VERSION ""

NS_ :

BS_:

BU_: TCU_FB5 RFA_BLEM GWM _delete GENERIC TSTR

BO_ 76 RCMStatusMessage2_HS4: 8 GWM
 SG_ RstrnPsngrOn_D_Stat : 39|4@0+ (1,0) [0|15] "SED"  GENERIC
 SG_ FirstRowBuckle_No_Cs : 47|8@0+ (1,0) [0|255] "unitless"  GENERIC
 SG_ RCMStatusMsg2_No_Cnt : 35|4@0+ (1,0) [0|15] "Unitless"  GENERIC
 SG_ PsngrFmidDetct_D_Actl : 26|2@0+ (1,0) [0|3] "SED"  TCU_FB5
 SG_ FirstRowBuckleMid : 28|2@0+ (1,0) [0|3] "SED"  TCU_FB5
 SG_ ThirdRowBucklePsngr : 17|2@0+ (1,0) [0|3] "SED" Vector__XXX
 SG_ ThirdRowBuckleMid : 19|2@0+ (1,0) [0|3] "SED" Vector__XXX
 SG_ ThirdRowBuckleDriver : 21|2@0+ (1,0) [0|3] "SED" Vector__XXX
 SG_ SecondRowBucklePsngr : 23|2@0+ (1,0) [0|3] "SED"  TCU_FB5
 SG_ SecondRowBuckleMid : 9|2@0+ (1,0) [0|3] "SED"  TCU_FB5
 SG_ SecondRowBuckleDriver : 11|2@0+ (1,0) [0|3] "SED"  TCU_FB5
 SG_ FirstRowBuckleDriver : 15|2@0+ (1,0) [0|3] "SED"  TCU_FB5
 SG_ RILReq : 7|2@0+ (1,0) [0|3] "SED"  GENERIC
 SG_ FirstRowBucklePsngr : 13|2@0+ (1,0) [0|3] "SED"  TCU_FB5
 SG_ RstrnImpactEvntStatus : 3|3@0+ (1,0) [0|7] "SED"  GENERIC
 SG_ PsngrFrntDetct_D_Actl : 5|2@0+ (1,0) [0|3] "SED"  TCU_FB5
 SG_ EDRTriggerEvntSync : 29|1@0+ (1,0) [0|1] "SED"  GENERIC
 SG_ PassRstrnInd_Req : 31|2@0+ (1,0) [0|3] "SED"  GENERIC

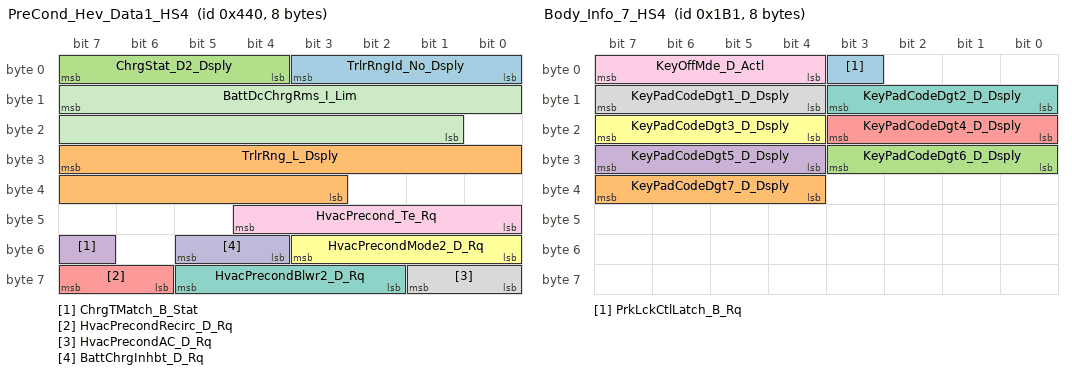
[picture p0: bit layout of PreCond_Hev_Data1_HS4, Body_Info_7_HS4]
BO_ 1088 PreCond_Hev_Data1_HS4: 8 GWM
 SG_ TrlrRngId_No_Dsply : 3|4@0+ (1,0) [0|15] "unitless" Vector__XXX
 SG_ TrlrRng_L_Dsply : 31|13@0+ (0.1,0) [0|818.9] "kilometer"  GENERIC
 SG_ ChrgStat_D2_Dsply : 7|4@0+ (1,0) [0|15] "SED" Vector__XXX
 SG_ ChrgTMatch_B_Stat : 55|1@0+ (1,0) [0|1] "SED"  GENERIC
 SG_ HvacPrecondRecirc_D_Rq : 63|2@0+ (1,0) [0|3] "SED"  GENERIC
 SG_ HvacPrecondMode2_D_Rq : 51|4@0+ (1,0) [0|15] "SED"  GENERIC
 SG_ HvacPrecondBlwr2_D_Rq : 61|4@0+ (1,0) [0|15] "SED"  GENERIC
 SG_ HvacPrecondAC_D_Rq : 57|2@0+ (1,0) [0|3] "SED"  GENERIC
 SG_ HvacPrecond_Te_Rq : 44|5@0+ (0.5,14.5) [14.5|30] "deg C"  GENERIC
 SG_ BattChrgInhbt_D_Rq : 53|2@0+ (1,0) [0|3] "SED"  GENERIC
 SG_ BattDcChrgRms_I_Lim : 15|15@0+ (0.05,0) [0|1638.25] "ampere"  GENERIC

BO_ 433 Body_Info_7_HS4: 8 GWM
 SG_ PrkLckCtlLatch_B_Rq : 3|1@0+ (1,0) [0|1] "SED" Vector__XXX
 SG_ KeyPadCodeDgt7_D_Dsply : 39|4@0+ (1,0) [0|15] "SED"  GENERIC
 SG_ KeyPadCodeDgt6_D_Dsply : 27|4@0+ (1,0) [0|15] "SED"  GENERIC
 SG_ KeyPadCodeDgt5_D_Dsply : 31|4@0+ (1,0) [0|15] "SED"  GENERIC
 SG_ KeyPadCodeDgt4_D_Dsply : 19|4@0+ (1,0) [0|15] "SED"  GENERIC
 SG_ KeyPadCodeDgt3_D_Dsply : 23|4@0+ (1,0) [0|15] "SED"  GENERIC
 SG_ KeyPadCodeDgt2_D_Dsply : 11|4@0+ (1,0) [0|15] "SED"  GENERIC
 SG_ KeyPadCodeDgt1_D_Dsply : 15|4@0+ (1,0) [0|15] "SED"  GENERIC
 SG_ KeyOffMde_D_Actl : 7|4@0+ (1,0) [0|15] "SED"  RFA_BLEM,TCU_FB5

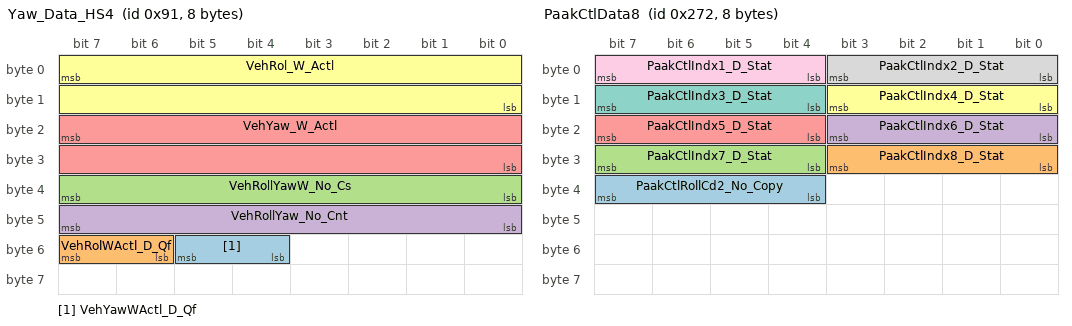
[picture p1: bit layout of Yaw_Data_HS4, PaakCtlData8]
BO_ 145 Yaw_Data_HS4: 8 GWM
 SG_ VehYawWActl_D_Qf : 53|2@0+ (1,0) [0|3] "SED"  TCU_FB5
 SG_ VehRolWActl_D_Qf : 55|2@0+ (1,0) [0|3] "SED"  GENERIC
 SG_ VehRollYawW_No_Cs : 39|8@0+ (1,0) [0|255] "Unitless"  GENERIC
 SG_ VehRollYaw_No_Cnt : 47|8@0+ (1,0) [0|255] "Unitless"  TCU_FB5
 SG_ VehYaw_W_Actl : 23|16@0+ (0.0002,-6.5) [-6.5|6.6066] "rad/s"  TCU_FB5
 SG_ VehRol_W_Actl : 7|16@0+ (0.0002,-6.5) [-6.5|6.6066] "rad/s"  GENERIC

BO_ 626 PaakCtlData8: 8 RFA_BLEM
 SG_ PaakCtlRollCd2_No_Copy : 39|4@0+ (1,0) [0|15] "unitless"  GWM
 SG_ PaakCtlIndx8_D_Stat : 27|4@0+ (1,0) [0|15] "SED"  GWM
 SG_ PaakCtlIndx7_D_Stat : 31|4@0+ (1,0) [0|15] "SED"  GWM
 SG_ PaakCtlIndx6_D_Stat : 19|4@0+ (1,0) [0|15] "SED"  GWM
 SG_ PaakCtlIndx5_D_Stat : 23|4@0+ (1,0) [0|15] "SED"  GWM
 SG_ PaakCtlIndx4_D_Stat : 11|4@0+ (1,0) [0|15] "SED"  GWM
 SG_ PaakCtlIndx3_D_Stat : 15|4@0+ (1,0) [0|15] "SED"  GWM
 SG_ PaakCtlIndx2_D_Stat : 3|4@0+ (1,0) [0|15] "SED"  GWM
 SG_ PaakCtlIndx1_D_Stat : 7|4@0+ (1,0) [0|15] "SED"  GWM

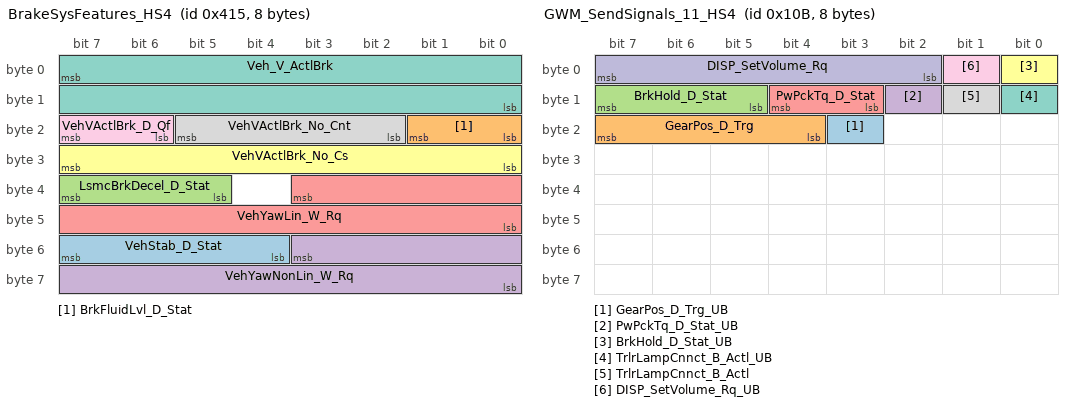
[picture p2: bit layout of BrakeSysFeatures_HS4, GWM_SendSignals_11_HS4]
BO_ 1045 BrakeSysFeatures_HS4: 8 GWM
 SG_ VehStab_D_Stat : 55|4@0+ (1,0) [0|15] "SED"  GENERIC
 SG_ BrkFluidLvl_D_Stat : 17|2@0+ (1,0) [0|3] "SED"  GENERIC
 SG_ LsmcBrkDecel_D_Stat : 39|3@0+ (1,0) [0|7] "SED"  GENERIC
 SG_ VehYawNonLin_W_Rq : 51|12@0+ (0.03663,-75) [-75|74.92659] "deg/s"  GENERIC
 SG_ VehYawLin_W_Rq : 35|12@0+ (0.03663,-75) [-75|74.92659] "deg/s"  GENERIC
 SG_ VehVActlBrk_No_Cs : 31|8@0+ (1,0) [0|255] "Unitless"  RFA_BLEM
 SG_ Veh_V_ActlBrk : 7|16@0+ (0.01,0) [0|655.35] "kph"  RFA_BLEM
 SG_ VehVActlBrk_No_Cnt : 21|4@0+ (1,0) [0|15] "Unitless"  RFA_BLEM
 SG_ VehVActlBrk_D_Qf : 23|2@0+ (1,0) [0|3] "SED"  RFA_BLEM

BO_ 1192 APIM_TCU_Word_Tx_HS4: 8 GWM
 SG_ APIM_TCU_Word_Tx : 7|64@0+ (1,0) [0|1.84467440737096E+019] "unitless"  TCU_FB5

BO_ 267 GWM_SendSignals_11_HS4: 8 GWM
 SG_ GearPos_D_Trg_UB : 19|1@0+ (1,0) [0|1] "SED"  RFA_BLEM
 SG_ GearPos_D_Trg : 23|4@0+ (1,0) [0|15] "SED"  RFA_BLEM
 SG_ BrkHold_D_Stat : 15|3@0+ (1,0) [0|7] "SED"  RFA_BLEM
 SG_ PwPckTq_D_Stat_UB : 10|1@0+ (1,0) [0|1] "SED"  RFA_BLEM
 SG_ PwPckTq_D_Stat : 12|2@0+ (1,0) [0|3] "SED"  RFA_BLEM
 SG_ BrkHold_D_Stat_UB : 0|1@0+ (1,0) [0|1] "SED"  RFA_BLEM
 SG_ TrlrLampCnnct_B_Actl_UB : 8|1@0+ (1,0) [0|1] "SED"  RFA_BLEM
 SG_ TrlrLampCnnct_B_Actl : 9|1@0+ (1,0) [0|1] "SED"  RFA_BLEM
 SG_ DISP_SetVolume_Rq_UB : 1|1@0+ (1,0) [0|1] "SED"  TCU_FB5
 SG_ DISP_SetVolume_Rq : 7|6@0+ (1,-30) [-30|33] "steps"  TCU_FB5

BO_ 2612224076 PARSEDPushRFAtoGWM_ECG: 8 RFA_BLEM
 SG_ PARSEDPushRFAtoGWM_ECG : 7|29@0+ (1,0) [0|536870911] "unitless"  GWM

BO_ 2611032280 PARSEDPhysGWM_ECGtoRFA: 8 GWM
 SG_ PARSEDPhysGWM_ECGtoRFA : 7|29@0+ (1,0) [0|536870911] "unitless"  RFA_BLEM

BO_ 351 LocationServices_Data2_HS4: 8 GWM
 SG_ LocationServices_2 : 7|64@0+ (1,0) [0|1.84467440737096E+019] "unitless"  RFA_BLEM

BO_ 350 LocationServices_Data1_HS4: 8 GWM
 SG_ LocationServices_1 : 7|64@0+ (1,0) [0|1.84467440737096E+019] "unitless"  RFA_BLEM,TCU_FB5

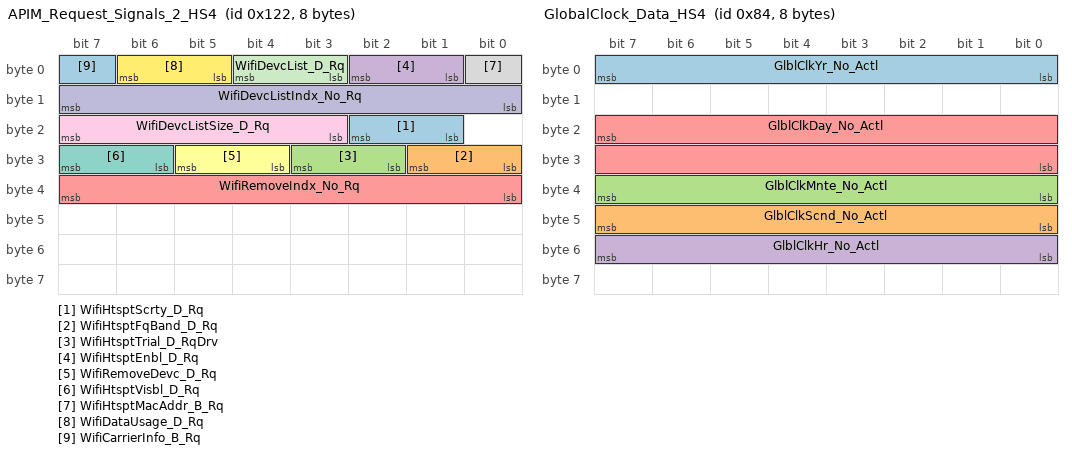
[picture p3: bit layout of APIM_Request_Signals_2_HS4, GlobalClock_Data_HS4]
BO_ 290 APIM_Request_Signals_2_HS4: 8 GWM
 SG_ WifiHtsptScrty_D_Rq : 18|2@0+ (1,0) [0|3] "SED"  GENERIC
 SG_ WifiHtsptFqBand_D_Rq : 25|2@0+ (1,0) [0|3] "SED"  TCU_FB5
 SG_ WifiHtsptTrial_D_RqDrv : 27|2@0+ (1,0) [0|3] "SED"  TCU_FB5
 SG_ WifiHtsptEnbl_D_Rq : 2|2@0+ (1,0) [0|3] "SED"  TCU_FB5
 SG_ WifiRemoveIndx_No_Rq : 39|8@0+ (1,0) [0|255] "unitless"  TCU_FB5
 SG_ WifiRemoveDevc_D_Rq : 29|2@0+ (1,0) [0|3] "SED"  TCU_FB5
 SG_ WifiHtsptVisbl_D_Rq : 31|2@0+ (1,0) [0|3] "SED"  TCU_FB5
 SG_ WifiHtsptMacAddr_B_Rq : 0|1@0+ (1,0) [0|1] "SED"  TCU_FB5
 SG_ WifiDevcListSize_D_Rq : 23|5@0+ (1,0) [0|31] "unitless"  TCU_FB5
 SG_ WifiDevcListIndx_No_Rq : 15|8@0+ (1,0) [0|255] "unitless"  TCU_FB5
 SG_ WifiDevcList_D_Rq : 4|2@0+ (1,0) [0|3] "SED"  TCU_FB5
 SG_ WifiDataUsage_D_Rq : 6|2@0+ (1,0) [0|3] "SED"  TCU_FB5
 SG_ WifiCarrierInfo_B_Rq : 7|1@0+ (1,0) [0|1] "SED"  TCU_FB5

BO_ 542 LocationServices_3: 8 TCU_FB5
 SG_ LocationServices_3 : 7|64@0+ (1,0) [0|1.84467440737096E+019] "unitless"  RFA_BLEM,GWM

BO_ 1849 TesterPhysicalResRFA: 8 RFA_BLEM
 SG_ TesterPhysicalResRFA : 7|64@0+ (1,0) [0|1.84467E+019] "unitless"  TSTR

BO_ 132 GlobalClock_Data_HS4: 8 GWM
 SG_ GlblClkYr_No_Actl : 7|8@0+ (1,2000) [2000|2255] "year"  TCU_FB5
 SG_ GlblClkScnd_No_Actl : 47|8@0+ (1,0) [0|255] "second"  TCU_FB5
 SG_ GlblClkMnte_No_Actl : 39|8@0+ (1,0) [0|255] "minute"  TCU_FB5
 SG_ GlblClkHr_No_Actl : 55|8@0+ (1,0) [0|255] "hour"  TCU_FB5
 SG_ GlblClkDay_No_Actl : 23|16@0+ (1,0) [0|65535] "julian day"  TCU_FB5

BO_ 636 TCU_Send_Signals_3: 8 TCU_FB5
 SG_ WifiHtsptFqBand_D_Stat : 60|2@0+ (1,0) [0|3] "SED"  GWM
 SG_ WifiHtspt_D_Falt : 51|4@0+ (1,0) [0|15] "SED"  GWM
 SG_ WifiNoDevcCnnct_No_Actl : 47|8@0+ (1,0) [0|255] "unitless"  GWM
 SG_ WifiHtsptCnnct_D_Stat : 26|2@0+ (1,0) [0|3] "SED"  GWM
 SG_ Telematics_D_Falt : 39|3@0+ (1,0) [0|7] "SED"  GWM
 SG_ WifiEnbl_D_Stat : 4|2@0+ (1,0) [0|3] "SED"  GWM
 SG_ WifiHtsptVisbl_D_Stat : 13|2@0+ (1,0) [0|3] "SED"  GWM
 SG_ WifiHtsptScrty_D_Stat : 15|2@0+ (1,0) [0|3] "SED"  GWM
 SG_ WifiHtsptEnbl_D_Stat : 2|2@0+ (1,0) [0|3] "SED"  GWM
 SG_ WifiDevcListNew_B_Stat : 5|1@0+ (1,0) [0|1] "SED"  GWM
 SG_ WifiDataUsage_Pc_Actl : 20|4@0+ (5,50) [50|125] "percent"  GWM
 SG_ WifiDataUsage_D_Stat : 7|2@0+ (1,0) [0|3] "SED"  GWM
 SG_ ModemSigStren_D_Stat : 11|3@0+ (1,0) [0|7] "SED"  GWM
 SG_ WifiHtsptCrdntl_B_Stat : 0|1@0+ (1,0) [0|1] "SED"  GWM
 SG_ WifiHtsptFq_D_Avail : 63|3@0+ (1,0) [0|7] "SED"  GWM
 SG_ WifiDataUsageOn_D_Stat : 28|2@0+ (1,0) [0|3] "SED"  GWM
 SG_ ModemTechnology_D2_Stat : 31|3@0+ (1,0) [0|7] "SED"  GWM

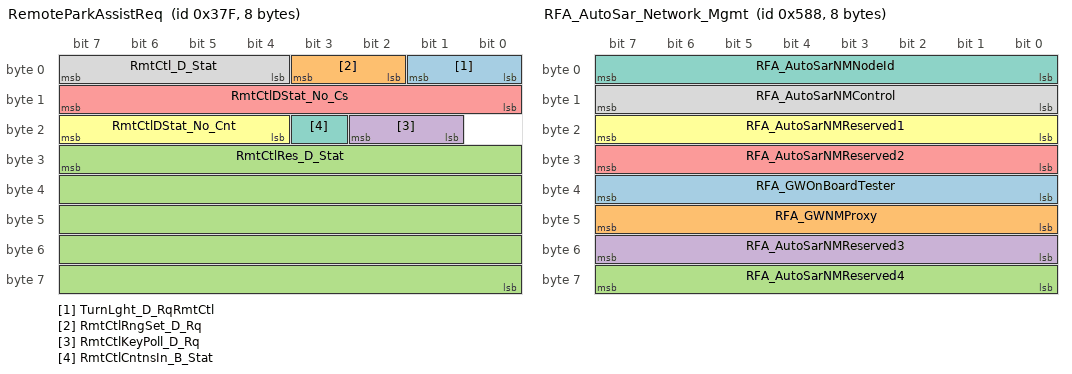
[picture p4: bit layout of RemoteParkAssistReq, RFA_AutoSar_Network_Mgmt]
BO_ 895 RemoteParkAssistReq: 8 RFA_BLEM
 SG_ TurnLght_D_RqRmtCtl : 1|2@0+ (1,0) [0|3] "SED"  GWM
 SG_ RmtCtlRngSet_D_Rq : 3|2@0+ (1,0) [0|3] "SED"  GWM
 SG_ RmtCtlRes_D_Stat : 31|40@0+ (1,0) [0|1099511627775] "unitless"  GWM
 SG_ RmtCtlKeyPoll_D_Rq : 18|2@0+ (1,0) [0|3] "SED"  GWM
 SG_ RmtCtlDStat_No_Cs : 15|8@0+ (1,0) [0|255] "Unitless"  GWM
 SG_ RmtCtlDStat_No_Cnt : 23|4@0+ (1,0) [0|15] "Unitless"  GWM
 SG_ RmtCtlCntnsIn_B_Stat : 19|1@0+ (1,0) [0|1] "SED"  GWM
 SG_ RmtCtl_D_Stat : 7|4@0+ (1,0) [0|15] "SED"  GWM

BO_ 1841 TesterPhysicalReqRFA: 8 TSTR
 SG_ TesterPhysicalReqRFA : 7|64@0+ (1,0) [0|1.84467E+019] "unitless"  RFA_BLEM

BO_ 1416 RFA_AutoSar_Network_Mgmt: 8 RFA_BLEM
 SG_ RFA_GWOnBoardTester : 39|8@0+ (1,0) [0|255] "unitless"  GWM
 SG_ RFA_GWNMProxy : 47|8@0+ (1,0) [0|255] "unitless"  GWM
 SG_ RFA_AutoSarNMReserved4 : 63|8@0+ (1,0) [0|255] "unitless"  GWM
 SG_ RFA_AutoSarNMReserved3 : 55|8@0+ (1,0) [0|255] "unitless"  GWM
 SG_ RFA_AutoSarNMReserved2 : 31|8@0+ (1,0) [0|255] "unitless"  GWM
 SG_ RFA_AutoSarNMReserved1 : 23|8@0+ (1,0) [0|255] "unitless"  GWM
 SG_ RFA_AutoSarNMNodeId : 7|8@0+ (1,0) [0|255] "unitless"  GWM
 SG_ RFA_AutoSarNMControl : 15|8@0+ (1,0) [0|255] "unitless"  GWM

BO_ 265 GWM_SendSignals_09_HS4: 8 GWM
 SG_ OdometerMasterValue_UB : 62|1@0+ (1,0) [0|1] "SED"  RFA_BLEM,TCU_FB5
 SG_ OdometerMasterValue : 7|24@0+ (1,0) [0|16777214] "km"  RFA_BLEM,TCU_FB5

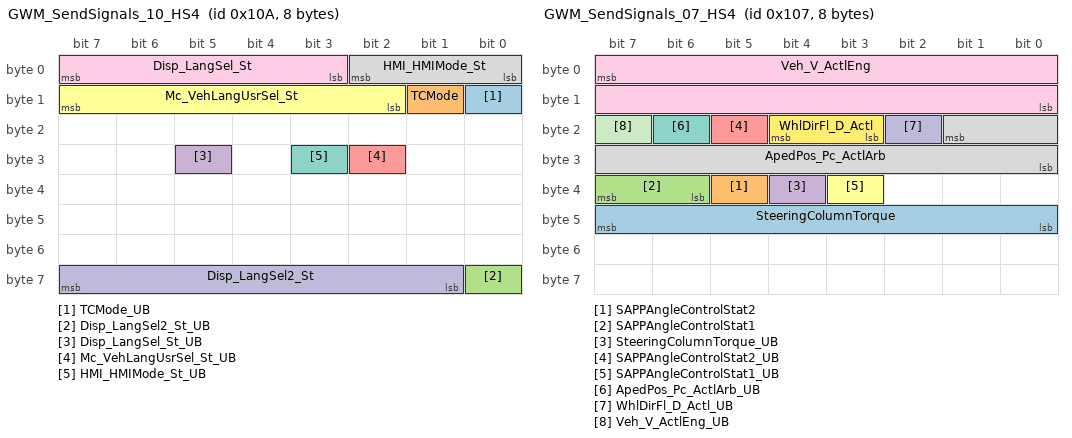
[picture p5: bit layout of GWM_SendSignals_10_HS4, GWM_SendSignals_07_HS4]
BO_ 266 GWM_SendSignals_10_HS4: 8 GWM
 SG_ TCMode_UB : 8|1@0+ (1,0) [0|1] "SED"  RFA_BLEM
 SG_ TCMode : 9|1@0+ (1,0) [0|1] "SED"  RFA_BLEM
 SG_ Disp_LangSel2_St_UB : 56|1@0+ (1,0) [0|1] "SED"  TCU_FB5
 SG_ Disp_LangSel_St_UB : 29|1@0+ (1,0) [0|1] "SED"  TCU_FB5
 SG_ Mc_VehLangUsrSel_St_UB : 26|1@0+ (1,0) [0|1] "SED"  TCU_FB5
 SG_ Mc_VehLangUsrSel_St : 15|6@0+ (1,0) [0|63] "SED"  TCU_FB5
 SG_ HMI_HMIMode_St_UB : 27|1@0+ (1,0) [0|1] "SED"  TCU_FB5
 SG_ HMI_HMIMode_St : 2|3@0+ (1,0) [0|7] "SED"  TCU_FB5
 SG_ Disp_LangSel_St : 7|5@0+ (1,0) [0|31] "SED"  TCU_FB5
 SG_ Disp_LangSel2_St : 63|7@0+ (1,0) [0|127] "SED"  TCU_FB5

BO_ 263 GWM_SendSignals_07_HS4: 8 GWM
 SG_ SteeringColumnTorque : 47|8@0+ (0.0625,-8) [-8|7.8125] "Nm"  RFA_BLEM
 SG_ SAPPAngleControlStat2 : 37|1@0+ (1,0) [0|1] "SED"  RFA_BLEM
 SG_ SAPPAngleControlStat1 : 39|2@0+ (1,0) [0|3] "SED"  RFA_BLEM
 SG_ SteeringColumnTorque_UB : 36|1@0+ (1,0) [0|1] "SED"  RFA_BLEM
 SG_ SAPPAngleControlStat2_UB : 21|1@0+ (1,0) [0|1] "SED"  RFA_BLEM
 SG_ SAPPAngleControlStat1_UB : 35|1@0+ (1,0) [0|1] "SED"  RFA_BLEM
 SG_ ApedPos_Pc_ActlArb_UB : 22|1@0+ (1,0) [0|1] "SED"  RFA_BLEM
 SG_ ApedPos_Pc_ActlArb : 17|10@0+ (0.1,0) [0|102.3] "%"  RFA_BLEM
 SG_ Veh_V_ActlEng : 7|16@0+ (0.01,0) [0|655.35] "kph"  RFA_BLEM,TCU_FB5
 SG_ WhlDirFl_D_Actl_UB : 18|1@0+ (1,0) [0|1] "SED"  TCU_FB5
 SG_ Veh_V_ActlEng_UB : 23|1@0+ (1,0) [0|1] "SED"  TCU_FB5,RFA_BLEM
 SG_ WhlDirFl_D_Actl : 20|2@0+ (1,0) [0|3] "SED"  TCU_FB5

BO_ 261 GWM_SendSignals_05_HS4: 8 GWM
 SG_ RstrnImpactEvntStatus_UB : 45|1@0+ (1,0) [0|1] "SED"  TCU_FB5
 SG_ RstrnImpactEvntStatus : 31|3@0+ (1,0) [0|7] "SED"  TCU_FB5

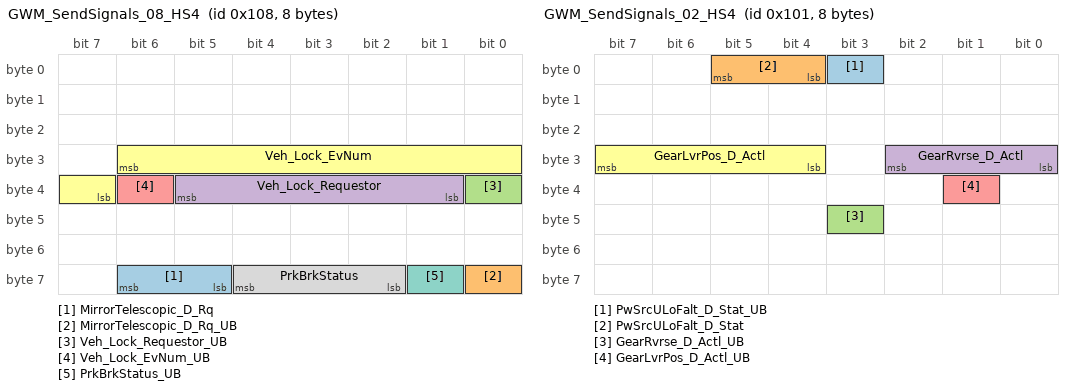
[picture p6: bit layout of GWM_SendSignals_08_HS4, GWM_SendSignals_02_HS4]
BO_ 264 GWM_SendSignals_08_HS4: 8 GWM
 SG_ MirrorTelescopic_D_Rq : 62|2@0+ (1,0) [0|3] "SED"  RFA_BLEM
 SG_ MirrorTelescopic_D_Rq_UB : 56|1@0+ (1,0) [0|1] "SED"  RFA_BLEM
 SG_ Veh_Lock_Requestor_UB : 32|1@0+ (1,0) [0|1] "SED"  TCU_FB5,RFA_BLEM
 SG_ Veh_Lock_Requestor : 37|5@0+ (1,0) [0|31] "SED"  TCU_FB5,RFA_BLEM
 SG_ Veh_Lock_EvNum_UB : 38|1@0+ (1,0) [0|1] "SED"  RFA_BLEM
 SG_ Veh_Lock_EvNum : 30|8@0+ (1,0) [0|255] "unitless"  RFA_BLEM
 SG_ PrkBrkStatus_UB : 57|1@0+ (1,0) [0|1] "SED"  RFA_BLEM
 SG_ PrkBrkStatus : 60|3@0+ (1,0) [0|7] "SED"  RFA_BLEM

BO_ 257 GWM_SendSignals_02_HS4: 8 GWM
 SG_ PwSrcULoFalt_D_Stat_UB : 3|1@0+ (1,0) [0|1] "SED"  TCU_FB5
 SG_ PwSrcULoFalt_D_Stat : 5|2@0+ (1,0) [0|3] "SED"  TCU_FB5
 SG_ GearRvrse_D_Actl_UB : 43|1@0+ (1,0) [0|1] "SED"  TCU_FB5
 SG_ GearRvrse_D_Actl : 26|3@0+ (1,0) [0|7] "SED"  TCU_FB5
 SG_ GearLvrPos_D_Actl_UB : 33|1@0+ (1,0) [0|1] "SED"  RFA_BLEM,TCU_FB5
 SG_ GearLvrPos_D_Actl : 31|4@0+ (1,0) [0|15] "SED"  RFA_BLEM,TCU_FB5

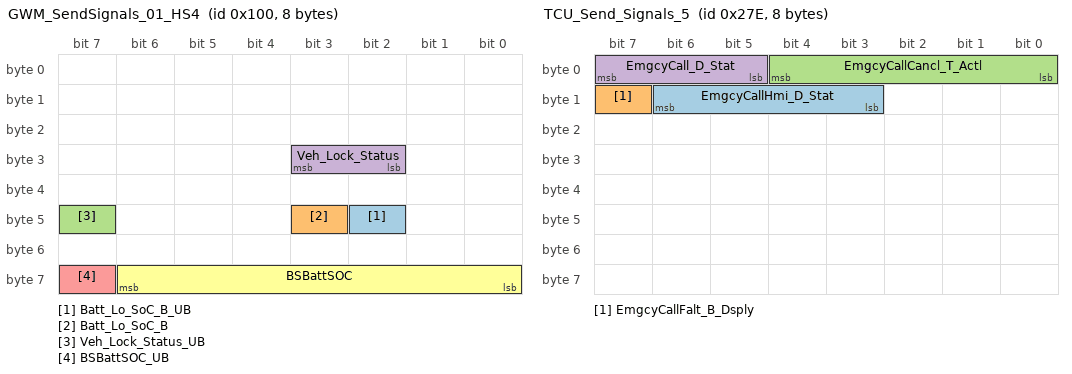
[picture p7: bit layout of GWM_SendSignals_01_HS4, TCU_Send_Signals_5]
BO_ 256 GWM_SendSignals_01_HS4: 8 GWM
 SG_ Batt_Lo_SoC_B_UB : 42|1@0+ (1,0) [0|1] "SED"  RFA_BLEM
 SG_ Batt_Lo_SoC_B : 43|1@0+ (1,0) [0|1] "SED"  RFA_BLEM
 SG_ Veh_Lock_Status_UB : 47|1@0+ (1,0) [0|1] "SED"  TCU_FB5,RFA_BLEM
 SG_ Veh_Lock_Status : 27|2@0+ (1,0) [0|3] "SED"  TCU_FB5,RFA_BLEM
 SG_ BSBattSOC_UB : 63|1@0+ (1,0) [0|1] "SED"  RFA_BLEM
 SG_ BSBattSOC : 62|7@0+ (1,0) [0|127] "%"  RFA_BLEM

BO_ 638 TCU_Send_Signals_5: 8 TCU_FB5
 SG_ EmgcyCallHmi_D_Stat : 14|4@0+ (1,0) [0|15] "SED"  GWM
 SG_ EmgcyCallFalt_B_Dsply : 15|1@0+ (1,0) [0|1] "SED"  GWM
 SG_ EmgcyCallCancl_T_Actl : 4|5@0+ (1,0) [0|31] "second"  GWM
 SG_ EmgcyCall_D_Stat : 7|3@0+ (1,0) [0|7] "SED"  GWM

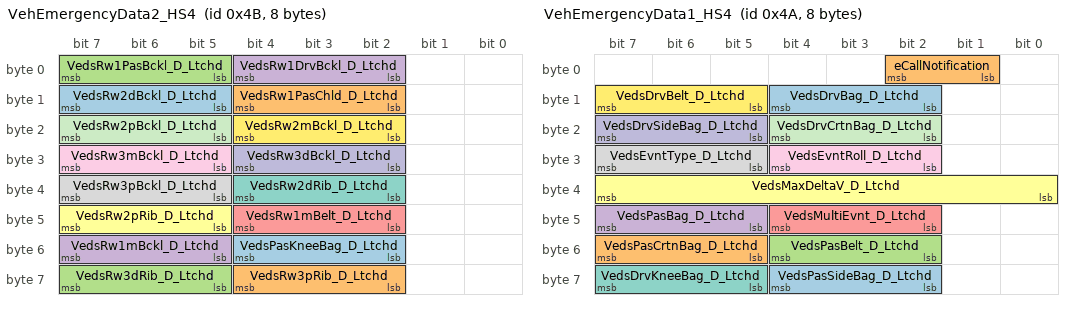
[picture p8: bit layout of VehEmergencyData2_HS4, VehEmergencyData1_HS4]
BO_ 75 VehEmergencyData2_HS4: 8 GWM
 SG_ VedsPasKneeBag_D_Ltchd : 52|3@0+ (1,0) [0|7] "SED"  TCU_FB5
 SG_ VedsRw3pRib_D_Ltchd : 60|3@0+ (1,0) [0|7] "SED"  TCU_FB5
 SG_ VedsRw3dRib_D_Ltchd : 63|3@0+ (1,0) [0|7] "SED"  TCU_FB5
 SG_ VedsRw1mBckl_D_Ltchd : 55|3@0+ (1,0) [0|7] "SED"  TCU_FB5
 SG_ VedsRw1mBelt_D_Ltchd : 44|3@0+ (1,0) [0|7] "SED"  TCU_FB5
 SG_ VedsRw2pRib_D_Ltchd : 47|3@0+ (1,0) [0|7] "SED"  TCU_FB5
 SG_ VedsRw2dRib_D_Ltchd : 36|3@0+ (1,0) [0|7] "SED"  TCU_FB5
 SG_ VedsRw3pBckl_D_Ltchd : 39|3@0+ (1,0) [0|7] "SED"  TCU_FB5
 SG_ VedsRw3mBckl_D_Ltchd : 31|3@0+ (1,0) [0|7] "SED"  TCU_FB5
 SG_ VedsRw3dBckl_D_Ltchd : 28|3@0+ (1,0) [0|7] "SED"  TCU_FB5
 SG_ VedsRw2pBckl_D_Ltchd : 23|3@0+ (1,0) [0|7] "SED"  TCU_FB5
 SG_ VedsRw2mBckl_D_Ltchd : 20|3@0+ (1,0) [0|7] "SED"  TCU_FB5
 SG_ VedsRw2dBckl_D_Ltchd : 15|3@0+ (1,0) [0|7] "SED"  TCU_FB5
 SG_ VedsRw1PasChld_D_Ltchd : 12|3@0+ (1,0) [0|7] "SED"  TCU_FB5
 SG_ VedsRw1PasBckl_D_Ltchd : 7|3@0+ (1,0) [0|7] "SED"  TCU_FB5
 SG_ VedsRw1DrvBckl_D_Ltchd : 4|3@0+ (1,0) [0|7] "SED"  TCU_FB5

BO_ 1184 APIM_TCU_Word_Rx_HS4: 8 TCU_FB5
 SG_ APIM_TCU_Word_Rx : 7|64@0+ (1,0) [0|1.84467440737096E+019] "unitless"  GWM

BO_ 74 VehEmergencyData1_HS4: 8 GWM
 SG_ VedsPasSideBag_D_Ltchd : 60|3@0+ (1,0) [0|7] "SED"  TCU_FB5
 SG_ VedsPasCrtnBag_D_Ltchd : 55|3@0+ (1,0) [0|7] "SED"  TCU_FB5
 SG_ VedsPasBelt_D_Ltchd : 52|3@0+ (1,0) [0|7] "SED"  TCU_FB5
 SG_ VedsPasBag_D_Ltchd : 47|3@0+ (1,0) [0|7] "SED"  TCU_FB5
 SG_ VedsMultiEvnt_D_Ltchd : 44|3@0+ (1,0) [0|7] "SED"  TCU_FB5
 SG_ VedsMaxDeltaV_D_Ltchd : 39|8@0+ (1,0) [0|255] "kph"  TCU_FB5
 SG_ VedsDrvKneeBag_D_Ltchd : 63|3@0+ (1,0) [0|7] "SED"  TCU_FB5
 SG_ VedsEvntType_D_Ltchd : 31|3@0+ (1,0) [0|7] "SED"  TCU_FB5
 SG_ VedsEvntRoll_D_Ltchd : 28|3@0+ (1,0) [0|7] "SED"  TCU_FB5
 SG_ VedsDrvSideBag_D_Ltchd : 23|3@0+ (1,0) [0|7] "SED"  TCU_FB5
 SG_ VedsDrvCrtnBag_D_Ltchd : 20|3@0+ (1,0) [0|7] "SED"  TCU_FB5
 SG_ VedsDrvBelt_D_Ltchd : 15|3@0+ (1,0) [0|7] "SED"  TCU_FB5
 SG_ VedsDrvBag_D_Ltchd : 12|3@0+ (1,0) [0|7] "SED"  TCU_FB5
 SG_ eCallNotification : 2|2@0+ (1,0) [0|3] "SED"  TCU_FB5

BO_ 2611175500 PARSEDPhysRFAtoGWMECG: 8 RFA_BLEM
 SG_ PARSEDPhysRFAtoGWM_ECG : 7|29@0+ (1,0) [0|536870911] "unitless"  GWM

BO_ 2609983704 OTAPhysGWM_ECGtoRFA: 8 GWM
 SG_ OTAPhysGWM_ECGtoRFA : 7|29@0+ (1,0) [0|536870911] "unitless"  RFA_BLEM

BO_ 2612002008 PARSEDFuncGWM_ECG_HS4: 8 GWM
 SG_ PARSEDFuncGWM_ECG : 7|29@0+ (1,0) [0|536870911] "unitless"  RFA_BLEM

BO_ 2610953432 OTAFuncGWM_ECG_HS4: 8 GWM
 SG_ OTAFuncGWM_ECG : 7|29@0+ (1,0) [0|536870911] "unitless"  RFA_BLEM

BO_ 625 PaakCtlData7: 8 GWM
 SG_ ModemAuthrz_D_Stat2 : 7|2@0+ (1,0) [0|3] "SED"  RFA_BLEM
 SG_ PaakSerial_D2_Rq2 : 5|3@0+ (1,0) [0|7] "SED"  RFA_BLEM

BO_ 694 RFA_BLEM_ECG_Word_Tx: 8 RFA_BLEM
 SG_ RFA_BLEM_ECG_Word_Tx : 7|64@0+ (1,0) [0|1.84467440737096E+019] "unitless"  GWM

BO_ 702 ECG_RFA_BLEM_Word_Tx: 8 GWM
 SG_ ECG_RFA_BLEM_Word_Tx : 7|64@0+ (1,0) [0|1.84467440737096E+019] "unitless"  RFA_BLEM

BO_ 1822 TesterPhysicalResGWM_HS4: 8 GWM
 SG_ TesterPhysicalResGWM_H4 : 7|64@0+ (1,0) [0|1.84467E+019] "unitless"  TSTR

BO_ 435 BodyInfo_3_HS4: 8 GWM
 SG_ ValetMode_D_Mem : 16|1@0+ (1,0) [0|1] "SED"  GENERIC
 SG_ DimmingLvlEvnt_No_Actl : 18|2@0+ (1,0) [0|3] "unitless"  GENERIC
 SG_ DrStatDrvErrCnt_B_Stat : 19|1@0+ (1,0) [0|1] "SED"  GENERIC
 SG_ TurnLghtRight_D_Rq : 63|2@0+ (1,0) [0|3] "SED"  GENERIC
 SG_ TurnLghtRightOn_B_Stat : 35|1@0+ (1,0) [0|1] "SED"  GENERIC
 SG_ TurnLghtLeftOn_B_Stat : 54|1@0+ (1,0) [0|1] "SED"  GENERIC
 SG_ FogLghtRearOn_B_Stat : 1|1@0+ (1,0) [0|1] "SED"  GENERIC
 SG_ Backlit_LED_Status : 23|4@0+ (1,0) [0|15] "SED"  GENERIC
 SG_ TurnLghtLeft_D_Rq : 9|2@0+ (1,0) [0|3] "SED"  GENERIC
 SG_ FogLghtFrontOn_B_Stat : 56|1@0+ (1,0) [0|1] "SED"  GENERIC
 SG_ IgnKeyType_D_Actl : 39|4@0+ (1,0) [0|15] "SED"  GENERIC
 SG_ Parklamp_Status : 3|2@0+ (1,0) [0|3] "SED"  TCU_FB5
 SG_ Litval : 47|8@0+ (1,0) [0|253] "SED"  GENERIC
 SG_ Key_In_Ignition_Stat : 11|1@0+ (1,0) [0|1] "SED"  GENERIC
 SG_ Ignition_Status : 7|4@0+ (1,0) [0|15] "SED"  RFA_BLEM,TCU_FB5
 SG_ Dimming_Lvl : 31|8@0+ (1,0) [0|253] "SED"  TCU_FB5
 SG_ Day_Night_Status : 15|2@0+ (1,0) [0|3] "SED"  TCU_FB5
 SG_ Remote_Start_Status : 13|2@0+ (1,0) [0|3] "SED"  RFA_BLEM
 SG_ DrStatTgate_B_Actl : 0|1@0+ (1,0) [0|1] "SED"  TCU_FB5,RFA_BLEM
 SG_ DrStatRr_B_Actl : 49|1@0+ (1,0) [0|1] "SED"  TCU_FB5,RFA_BLEM
 SG_ DrStatRl_B_Actl : 48|1@0+ (1,0) [0|1] "SED"  TCU_FB5,RFA_BLEM
 SG_ DrStatPsngr_B_Actl : 60|1@0+ (1,0) [0|1] "SED"  TCU_FB5,RFA_BLEM
 SG_ DrStatInnrTgate_B_Actl : 58|1@0+ (1,0) [0|1] "SED"  TCU_FB5,RFA_BLEM
 SG_ DrStatHood_B_Actl : 59|1@0+ (1,0) [0|1] "SED"  TCU_FB5,RFA_BLEM
 SG_ DrStatDrv_B_Actl : 61|1@0+ (1,0) [0|1] "SED"  TCU_FB5,RFA_BLEM
 SG_ PrkBrkActv_B_Actl : 55|1@0+ (1,0) [0|1] "SED"  GENERIC
 SG_ LifeCycMde_D_Actl : 53|4@0+ (1,0) [0|15] "SED"  RFA_BLEM,TCU_FB5
 SG_ Delay_Accy : 57|1@0+ (1,0) [0|1] "SED"  TCU_FB5
 SG_ CrashEvnt_D_Stat : 34|2@0+ (1,0) [0|3] "SED"  GENERIC
 SG_ FuelPmpInhbt_B_Stat : 32|1@0+ (1,0) [0|1] "SED"  GENERIC
 SG_ BodySrvcRqd_B_Rq : 10|1@0+ (1,0) [0|1] "SED"  GENERIC

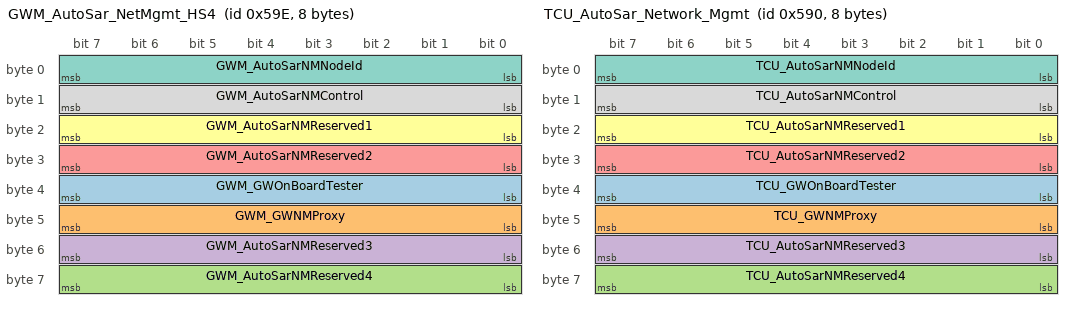
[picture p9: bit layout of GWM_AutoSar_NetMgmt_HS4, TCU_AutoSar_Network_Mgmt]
BO_ 1438 GWM_AutoSar_NetMgmt_HS4: 8 GWM
 SG_ GWM_GWOnBoardTester : 39|8@0+ (1,0) [0|255] "unitless"  RFA_BLEM,GENERIC,TCU_FB5
 SG_ GWM_GWNMProxy : 47|8@0+ (1,0) [0|255] "unitless"  RFA_BLEM,GENERIC,TCU_FB5
 SG_ GWM_AutoSarNMReserved4 : 63|8@0+ (1,0) [0|255] "unitless"  RFA_BLEM,GENERIC,TCU_FB5
 SG_ GWM_AutoSarNMReserved3 : 55|8@0+ (1,0) [0|255] "unitless"  RFA_BLEM,GENERIC,TCU_FB5
 SG_ GWM_AutoSarNMReserved2 : 31|8@0+ (1,0) [0|255] "unitless"  RFA_BLEM,GENERIC,TCU_FB5
 SG_ GWM_AutoSarNMReserved1 : 23|8@0+ (1,0) [0|255] "unitless"  RFA_BLEM,GENERIC,TCU_FB5
 SG_ GWM_AutoSarNMNodeId : 7|8@0+ (1,0) [0|255] "unitless"  RFA_BLEM,GENERIC,TCU_FB5
 SG_ GWM_AutoSarNMControl : 15|8@0+ (1,0) [0|255] "unitless"  RFA_BLEM,GENERIC,TCU_FB5

BO_ 282 GGCC_Config_Mgmt_ID_1_HS4: 8 GWM
 SG_ VehicleGGCCData : 7|64@0+ (1,0) [0|1.84467E+019] "mixed"  RFA_BLEM,TCU_FB5

BO_ 1876 TesterPhysicalReqTCU4: 8 TSTR
 SG_ TesterPhysicalReqTCU : 7|64@0+ (1,0) [0|1.84467E+019] "unitless"  TCU_FB5

BO_ 1884 TesterPhysicalResTCU4: 8 TCU_FB5
 SG_ TesterPhysicalResTCU : 7|64@0+ (1,0) [0|1.84467E+019] "unitless"  TSTR

BO_ 1424 TCU_AutoSar_Network_Mgmt: 8 TCU_FB5
 SG_ TCU_GWOnBoardTester : 39|8@0+ (1,0) [0|255] "unitless"  GWM
 SG_ TCU_GWNMProxy : 47|8@0+ (1,0) [0|255] "unitless"  GWM
 SG_ TCU_AutoSarNMReserved4 : 63|8@0+ (1,0) [0|255] "unitless"  GWM
 SG_ TCU_AutoSarNMReserved3 : 55|8@0+ (1,0) [0|255] "unitless"  GWM
 SG_ TCU_AutoSarNMReserved2 : 31|8@0+ (1,0) [0|255] "unitless"  GWM
 SG_ TCU_AutoSarNMReserved1 : 23|8@0+ (1,0) [0|255] "unitless"  GWM
 SG_ TCU_AutoSarNMNodeId : 7|8@0+ (1,0) [0|255] "unitless"  GWM
 SG_ TCU_AutoSarNMControl : 15|8@0+ (1,0) [0|255] "unitless"  GWM

BO_ 2015 TesterFunctionalReq_H4: 8 TSTR
 SG_ TesterFunctionalReq : 7|64@0+ (1,0) [0|1.84467E+019] "unitless"  RFA_BLEM,GWM,TCU_FB5

BO_ 1814 TesterPhysicalReqGWM_H4: 8 TSTR
 SG_ TesterPhysicalReqGWM_H4 : 7|64@0+ (1,0) [0|1.84467E+019] "unitless"  GWM

CM_ SG_ 1088 HvacPrecondMode2_D_Rq "Signal not transmitted on vehicles that do not have the Fuel operated heater feature.";
CM_ SG_ 1088 HvacPrecondBlwr2_D_Rq "Signal not transmitted on vehicles that do not have the Fuel operated heater feature.";
CM_ BO_ 1192 "TP message";
CM_ SG_ 1192 APIM_TCU_Word_Tx "Tx by HS3 APIM";
CM_ SG_ 267 GearPos_D_Trg "Powersplit HEVs with HF45, HPCM will Tx  this message.  For all other programs it will be Tx by PCM or TCM. ";
CM_ SG_ 351 LocationServices_2 "Tx by HS3 APIM";
CM_ SG_ 350 LocationServices_1 "Tx by HS3 APIM";
CM_ SG_ 542 LocationServices_3 "Tx by HS3 APIM";
CM_ SG_ 266 TCMode "Signal data set to 0x0 for ABS only vehicle option content";
CM_ SG_ 266 Mc_VehLangUsrSel_St "Object.BodyInterface.Settings.VehicleLanguageUserSelection
Object Vehicle Settings.Disp_LangSel
";
CM_ SG_ 266 HMI_HMIMode_St "Object ACU System Master.HMIMode
OR
Object NAV System Master.HMIMode

Refer Method HMIAudioMode in the SPSS";
CM_ SG_ 266 Disp_LangSel_St "Object.VehicleSettings.Disp_LangSel.St.Language";
CM_ SG_ 266 Disp_LangSel2_St "Reference GSDB for encoding: 009522/B;2-ZZ_LangSel";
CM_ SG_ 257 GearRvrse_D_Actl "Do not implement GearRvrse_D_Actl  until eTracker 8804151 is approved, 11/24/09";
CM_ BO_ 1184 "TP message";
CM_ BO_ 74 "Reserve eCallNotification message";
CM_ SG_ 702 ECG_RFA_BLEM_Word_Tx "Tx by HS3 APIM";
CM_ SG_ 435 Dimming_Lvl "Refer to Vehicle Interior Illum Dimming Ctrl Sys Eng Spec, Table 2

";
CM_ SG_ 435 PrkBrkActv_B_Actl "Signal not transmitted on vehicles with electric park brake. ";
CM_ SG_ 282 VehicleGGCCData "RCMGenSigTimeout=6000";
CM_ BO_ 2015 "OBDII Request ($7DF) messages are for FNOS 1.0.1 only.
Diagnostic Functional Addressing ($7DF) and Dual Rate Periodic messages are for FNOS I3 only.";
BA_DEF_ BO_  "FrameRouting" STRING ;
BA_DEF_ BO_  "FrameGatewayNetwork" STRING ;
BA_DEF_ BO_  "NetworkInitialization" ENUM  "No","Yes";
BA_DEF_ BO_  "FrameGatewayId" HEX 0 1407;
BA_DEF_ BO_  "EventRateOfChange" INT 10 10000;
BA_DEF_ BO_  "GenMsgNrOfRepetition" INT 0 100;
BA_DEF_ BO_  "GenMsgDelayTime" INT 0 1000;
BA_DEF_ BO_  "GenMsgCycleTime" INT 0 100000;
BA_DEF_ BO_  "GenMsgSendType" ENUM  "FixedPeriodic","Event","EnabledPeriodic","NotUsed","NotUsed","EventPeriodic","NotUsed","NotUsed","NoMsgSendType";
BA_DEF_ SG_  "U_CD764_MY2022_Tx" ENUM  "No","Yes";
BA_DEF_ SG_  "U_U55X_MY2022_Tx" ENUM  "No","Yes";
BA_DEF_ SG_  "U_CD542_MY2021_Tx" ENUM  "No","Yes";
BA_DEF_ SG_  "ECGUsedTxSignal" ENUM  "No","Yes";
BA_DEF_ SG_  "U_T6_MCA_MY2020_Tx" ENUM  "No","Yes";
BA_DEF_ SG_  "U_P702_MY2021_Tx" ENUM  "No","Yes";
BA_DEF_ SG_  "U_CX727_MY2021_Tx" ENUM  "No","Yes";
BA_DEF_ SG_  "U_CD764_MY2022_Rx" ENUM  "No","Yes";
BA_DEF_ SG_  "U_U55X_MY2022_Rx" ENUM  "No","Yes";
BA_DEF_ SG_  "U_CD542_MY2021_Rx" ENUM  "No","Yes";
BA_DEF_ SG_  "ECGUsedRxSignal" ENUM  "No","Yes";
BA_DEF_ SG_  "U_T6_MCA_MY2020_Rx" ENUM  "No","Yes";
BA_DEF_ SG_  "U_P702_MY2021_Rx" ENUM  "No","Yes";
BA_DEF_ SG_  "U_CX727_MY2021_Rx" ENUM  "No","Yes";
BA_DEF_ SG_  "GenSigStartValue" HEX 0 268435455;
BA_DEF_ SG_  "MetaData" ENUM  "No","Yes";
BA_DEF_ SG_  "ContentDependant" ENUM  "No","Yes";
BA_DEF_ SG_  "GenSigStartValueInteger" INT 0 1000000000;
BA_DEF_ SG_  "UsedOnPgmDBC" ENUM  "No","Yes";
BA_DEF_ SG_  "WakeupSignal" ENUM  "No","Yes";
BA_DEF_ SG_  "GenSigInactiveValue" INT 0 100000;
BA_DEF_ SG_  "GenSigSendType" ENUM  "Cyclic","OnWrite","vector_leerstring","OnChange","vector_leerstring","IfActive","vector_leerstring","NoSigSendType";
BA_DEF_ BO_  "OvtpPushApplication" ENUM  "FALSE","TRUE";
BA_DEF_ BO_  "SCP_FreshnessValueLength" INT 0 512;
BA_DEF_ BO_  "SCP_FreshnessValueTxLength" INT 0 512;
BA_DEF_ BO_  "SCP_AuthInfoTxLength" INT 0 512;
BA_DEF_ BO_  "GenMsgRoutingTimeoutTime" INT 0 5000;
BA_DEF_ BO_  "MessageGateway" ENUM  "No","Yes";
BA_DEF_ BO_  "NmAsrMessage" ENUM  "No","Yes";
BA_DEF_ BO_  "DiagState" ENUM  "No","Yes";
BA_DEF_ BO_  "TpTxIndex" INT 0 536870911;
BA_DEF_ BO_  "DiagRequest" ENUM  "No","Yes";
BA_DEF_ BO_  "DiagResponse" ENUM  "No","Yes";
BA_DEF_ BO_  "GenMsgILSupport" ENUM  "No","Yes";
BA_DEF_DEF_  "FrameRouting" "";
BA_DEF_DEF_  "FrameGatewayNetwork" "NONE";
BA_DEF_DEF_  "NetworkInitialization" "Yes";
BA_DEF_DEF_  "FrameGatewayId" 0;
BA_DEF_DEF_  "EventRateOfChange" 10000;
BA_DEF_DEF_  "GenMsgNrOfRepetition" 1;
BA_DEF_DEF_  "GenMsgDelayTime" 20;
BA_DEF_DEF_  "GenMsgCycleTime" 0;
BA_DEF_DEF_  "GenMsgSendType" "NoMsgSendType";
BA_DEF_DEF_  "U_CD764_MY2022_Tx" "No";
BA_DEF_DEF_  "U_U55X_MY2022_Tx" "No";
BA_DEF_DEF_  "U_CD542_MY2021_Tx" "No";
BA_DEF_DEF_  "ECGUsedTxSignal" "No";
BA_DEF_DEF_  "U_T6_MCA_MY2020_Tx" "No";
BA_DEF_DEF_  "U_P702_MY2021_Tx" "No";
BA_DEF_DEF_  "U_CX727_MY2021_Tx" "No";
BA_DEF_DEF_  "U_CD764_MY2022_Rx" "No";
BA_DEF_DEF_  "U_U55X_MY2022_Rx" "No";
BA_DEF_DEF_  "U_CD542_MY2021_Rx" "No";
BA_DEF_DEF_  "ECGUsedRxSignal" "No";
BA_DEF_DEF_  "U_T6_MCA_MY2020_Rx" "No";
BA_DEF_DEF_  "U_P702_MY2021_Rx" "No";
BA_DEF_DEF_  "U_CX727_MY2021_Rx" "No";
BA_DEF_DEF_  "GenSigStartValue" 0;
BA_DEF_DEF_  "MetaData" "No";
BA_DEF_DEF_  "ContentDependant" "No";
BA_DEF_DEF_  "GenSigStartValueInteger" 0;
BA_DEF_DEF_  "UsedOnPgmDBC" "Yes";
BA_DEF_DEF_  "WakeupSignal" "No";
BA_DEF_DEF_  "GenSigInactiveValue" 0;
BA_DEF_DEF_  "GenSigSendType" "NoSigSendType";
BA_DEF_DEF_  "OvtpPushApplication" "FALSE";
BA_DEF_DEF_  "SCP_FreshnessValueLength" 64;
BA_DEF_DEF_  "SCP_FreshnessValueTxLength" 11;
BA_DEF_DEF_  "SCP_AuthInfoTxLength" 53;
BA_DEF_DEF_  "GenMsgRoutingTimeoutTime" 0;
BA_DEF_DEF_  "MessageGateway" "No";
BA_DEF_DEF_  "NmAsrMessage" "No";
BA_DEF_DEF_  "DiagState" "No";
BA_DEF_DEF_  "TpTxIndex" 0;
BA_DEF_DEF_  "DiagRequest" "No";
BA_DEF_DEF_  "DiagResponse" "No";
BA_DEF_DEF_  "GenMsgILSupport" "Yes";
BA_ "FrameGatewayId" BO_ 76 76;
BA_ "FrameGatewayNetwork" BO_ 76 "HS2_CAN";
BA_ "FrameRouting" BO_ 76 "HS2_CAN,0x4C;";
BA_ "FrameGatewayId" BO_ 1088 1088;
BA_ "FrameGatewayNetwork" BO_ 1088 "FD1_CAN";
BA_ "FrameRouting" BO_ 1088 "FD1_CAN,0x440;";
BA_ "FrameGatewayId" BO_ 433 945;
BA_ "FrameGatewayNetwork" BO_ 433 "HS1_CAN";
BA_ "FrameRouting" BO_ 433 "HS1_CAN,0x3B1";
BA_ "MessageGateway" BO_ 145 1;
BA_ "GenMsgRoutingTimeoutTime" BO_ 145 30;
BA_ "GenMsgSendType" BO_ 145 0;
BA_ "GenMsgCycleTime" BO_ 145 100;
BA_ "GenMsgSendType" BO_ 626 5;
BA_ "GenMsgCycleTime" BO_ 626 200;
BA_ "MessageGateway" BO_ 1045 1;
BA_ "GenMsgRoutingTimeoutTime" BO_ 1045 60;
BA_ "GenMsgSendType" BO_ 1045 0;
BA_ "GenMsgCycleTime" BO_ 1045 100;
BA_ "TpTxIndex" BO_ 1192 20;
BA_ "FrameGatewayId" BO_ 1192 1192;
BA_ "FrameGatewayNetwork" BO_ 1192 "HS3_CAN";
BA_ "FrameRouting" BO_ 1192 "HS3_CAN,0x4A8;";
BA_ "GenMsgSendType" BO_ 267 5;
BA_ "GenMsgCycleTime" BO_ 267 1000;
BA_ "TpTxIndex" BO_ 2612224076 464597208;
BA_ "OvtpPushApplication" BO_ 2612224076 1;
BA_ "GenMsgSendType" BO_ 2612224076 1;
BA_ "GenMsgDelayTime" BO_ 2612224076 0;
BA_ "TpTxIndex" BO_ 2611032280 463548632;
BA_ "GenMsgSendType" BO_ 2611032280 1;
BA_ "GenMsgDelayTime" BO_ 2611032280 0;
BA_ "FrameGatewayId" BO_ 351 1119;
BA_ "FrameGatewayNetwork" BO_ 351 "HS3_CAN";
BA_ "FrameRouting" BO_ 351 "HS3_CAN,0x45F;";
BA_ "FrameGatewayId" BO_ 350 1118;
BA_ "FrameGatewayNetwork" BO_ 350 "HS3_CAN";
BA_ "FrameRouting" BO_ 350 "HS3_CAN,0x45E;";
BA_ "FrameGatewayId" BO_ 290 290;
BA_ "FrameGatewayNetwork" BO_ 290 "HS3_CAN";
BA_ "FrameRouting" BO_ 290 "HS3_CAN,0x122;";
BA_ "GenMsgSendType" BO_ 542 1;
BA_ "NetworkInitialization" BO_ 542 0;
BA_ "GenMsgILSupport" BO_ 1849 0;
BA_ "DiagResponse" BO_ 1849 1;
BA_ "GenMsgSendType" BO_ 1849 1;
BA_ "GenMsgDelayTime" BO_ 1849 0;
BA_ "NetworkInitialization" BO_ 1849 0;
BA_ "FrameGatewayId" BO_ 132 132;
BA_ "FrameGatewayNetwork" BO_ 132 "HS1_CAN";
BA_ "FrameRouting" BO_ 132 "HS1_CAN,0x84;";
BA_ "GenMsgSendType" BO_ 636 5;
BA_ "GenMsgCycleTime" BO_ 636 1000;
BA_ "GenMsgSendType" BO_ 895 0;
BA_ "GenMsgCycleTime" BO_ 895 60;
BA_ "GenMsgILSupport" BO_ 1841 0;
BA_ "DiagRequest" BO_ 1841 1;
BA_ "GenMsgSendType" BO_ 1841 1;
BA_ "GenMsgDelayTime" BO_ 1841 0;
BA_ "NetworkInitialization" BO_ 1841 0;
BA_ "GenMsgILSupport" BO_ 1416 0;
BA_ "NmAsrMessage" BO_ 1416 1;
BA_ "GenMsgSendType" BO_ 1416 0;
BA_ "GenMsgCycleTime" BO_ 1416 1000;
BA_ "NetworkInitialization" BO_ 1416 0;
BA_ "GenMsgSendType" BO_ 265 5;
BA_ "GenMsgCycleTime" BO_ 265 1000;
BA_ "GenMsgSendType" BO_ 266 5;
BA_ "GenMsgCycleTime" BO_ 266 1000;
BA_ "GenMsgSendType" BO_ 263 0;
BA_ "GenMsgCycleTime" BO_ 263 100;
BA_ "GenMsgSendType" BO_ 261 5;
BA_ "GenMsgCycleTime" BO_ 261 1000;
BA_ "GenMsgSendType" BO_ 264 5;
BA_ "GenMsgCycleTime" BO_ 264 1000;
BA_ "GenMsgSendType" BO_ 257 5;
BA_ "GenMsgCycleTime" BO_ 257 1000;
BA_ "GenMsgSendType" BO_ 256 5;
BA_ "GenMsgCycleTime" BO_ 256 1000;
BA_ "GenMsgSendType" BO_ 638 5;
BA_ "GenMsgCycleTime" BO_ 638 1000;
BA_ "FrameGatewayId" BO_ 75 75;
BA_ "FrameGatewayNetwork" BO_ 75 "HS2_CAN";
BA_ "FrameRouting" BO_ 75 "HS2_CAN,0x4B;";
BA_ "TpTxIndex" BO_ 1184 20;
BA_ "FrameGatewayId" BO_ 74 74;
BA_ "FrameGatewayNetwork" BO_ 74 "HS2_CAN";
BA_ "FrameRouting" BO_ 74 "HS2_CAN,0x4A;";
BA_ "TpTxIndex" BO_ 2611175500 463548632;
BA_ "GenMsgSendType" BO_ 2611175500 1;
BA_ "GenMsgDelayTime" BO_ 2611175500 0;
BA_ "TpTxIndex" BO_ 2609983704 462500056;
BA_ "GenMsgSendType" BO_ 2609983704 1;
BA_ "GenMsgDelayTime" BO_ 2609983704 0;
BA_ "TpTxIndex" BO_ 2612002008 464518360;
BA_ "GenMsgSendType" BO_ 2612002008 1;
BA_ "GenMsgDelayTime" BO_ 2612002008 0;
BA_ "NetworkInitialization" BO_ 2612002008 0;
BA_ "TpTxIndex" BO_ 2610953432 463469784;
BA_ "GenMsgSendType" BO_ 2610953432 1;
BA_ "GenMsgDelayTime" BO_ 2610953432 0;
BA_ "NetworkInitialization" BO_ 2610953432 0;
BA_ "GenMsgSendType" BO_ 625 5;
BA_ "GenMsgCycleTime" BO_ 625 1000;
BA_ "TpTxIndex" BO_ 694 54;
BA_ "TpTxIndex" BO_ 702 54;
BA_ "GenMsgILSupport" BO_ 1822 0;
BA_ "DiagResponse" BO_ 1822 1;
BA_ "GenMsgSendType" BO_ 1822 1;
BA_ "GenMsgDelayTime" BO_ 1822 0;
BA_ "NetworkInitialization" BO_ 1822 0;
BA_ "FrameGatewayId" BO_ 435 947;
BA_ "FrameGatewayNetwork" BO_ 435 "HS1_CAN";
BA_ "FrameRouting" BO_ 435 "HS1_CAN,0x3B3;";
BA_ "GenMsgILSupport" BO_ 1438 0;
BA_ "NmAsrMessage" BO_ 1438 1;
BA_ "GenMsgSendType" BO_ 1438 0;
BA_ "GenMsgCycleTime" BO_ 1438 1000;
BA_ "NetworkInitialization" BO_ 1438 0;
BA_ "FrameGatewayId" BO_ 282 1034;
BA_ "FrameGatewayNetwork" BO_ 282 "HS1_CAN";
BA_ "FrameRouting" BO_ 282 "HS1_CAN,0x40A;";
BA_ "GenMsgILSupport" BO_ 1876 0;
BA_ "DiagRequest" BO_ 1876 1;
BA_ "GenMsgSendType" BO_ 1876 1;
BA_ "GenMsgDelayTime" BO_ 1876 0;
BA_ "NetworkInitialization" BO_ 1876 0;
BA_ "GenMsgILSupport" BO_ 1884 0;
BA_ "DiagResponse" BO_ 1884 1;
BA_ "GenMsgSendType" BO_ 1884 1;
BA_ "GenMsgDelayTime" BO_ 1884 0;
BA_ "NetworkInitialization" BO_ 1884 0;
BA_ "GenMsgILSupport" BO_ 1424 0;
BA_ "NmAsrMessage" BO_ 1424 1;
BA_ "GenMsgSendType" BO_ 1424 0;
BA_ "GenMsgCycleTime" BO_ 1424 1000;
BA_ "NetworkInitialization" BO_ 1424 0;
BA_ "GenMsgILSupport" BO_ 2015 0;
BA_ "DiagState" BO_ 2015 1;
BA_ "GenMsgSendType" BO_ 2015 1;
BA_ "GenMsgDelayTime" BO_ 2015 0;
BA_ "NetworkInitialization" BO_ 2015 0;
BA_ "GenMsgILSupport" BO_ 1814 0;
BA_ "DiagRequest" BO_ 1814 1;
BA_ "GenMsgSendType" BO_ 1814 1;
BA_ "GenMsgDelayTime" BO_ 1814 0;
BA_ "NetworkInitialization" BO_ 1814 0;
BA_ "MetaData" SG_ 76 FirstRowBuckle_No_Cs 1;
BA_ "MetaData" SG_ 76 RCMStatusMsg2_No_Cnt 1;
BA_ "GenSigStartValueInteger" SG_ 76 PsngrFmidDetct_D_Actl 3;
BA_ "GenSigStartValue" SG_ 76 PsngrFmidDetct_D_Actl 3;
BA_ "U_CD764_MY2022_Rx" SG_ 76 PsngrFmidDetct_D_Actl 1;
BA_ "GenSigStartValueInteger" SG_ 76 FirstRowBuckleMid 3;
BA_ "GenSigStartValue" SG_ 76 FirstRowBuckleMid 3;
BA_ "U_CD764_MY2022_Rx" SG_ 76 FirstRowBuckleMid 1;
BA_ "GenSigStartValueInteger" SG_ 76 ThirdRowBucklePsngr 3;
BA_ "GenSigStartValue" SG_ 76 ThirdRowBucklePsngr 3;
BA_ "U_CD764_MY2022_Rx" SG_ 76 ThirdRowBucklePsngr 1;
BA_ "GenSigStartValueInteger" SG_ 76 ThirdRowBuckleMid 3;
BA_ "GenSigStartValue" SG_ 76 ThirdRowBuckleMid 3;
BA_ "U_CD764_MY2022_Rx" SG_ 76 ThirdRowBuckleMid 1;
BA_ "GenSigStartValueInteger" SG_ 76 ThirdRowBuckleDriver 3;
BA_ "GenSigStartValue" SG_ 76 ThirdRowBuckleDriver 3;
BA_ "U_CD764_MY2022_Rx" SG_ 76 ThirdRowBuckleDriver 1;
BA_ "GenSigStartValueInteger" SG_ 76 SecondRowBucklePsngr 3;
BA_ "GenSigStartValue" SG_ 76 SecondRowBucklePsngr 3;
BA_ "U_CD764_MY2022_Rx" SG_ 76 SecondRowBucklePsngr 1;
BA_ "GenSigStartValueInteger" SG_ 76 SecondRowBuckleMid 3;
BA_ "GenSigStartValue" SG_ 76 SecondRowBuckleMid 3;
BA_ "U_CD764_MY2022_Rx" SG_ 76 SecondRowBuckleMid 1;
BA_ "GenSigStartValueInteger" SG_ 76 SecondRowBuckleDriver 3;
BA_ "GenSigStartValue" SG_ 76 SecondRowBuckleDriver 3;
BA_ "U_CD764_MY2022_Rx" SG_ 76 SecondRowBuckleDriver 1;
BA_ "GenSigStartValueInteger" SG_ 76 FirstRowBuckleDriver 3;
BA_ "GenSigStartValue" SG_ 76 FirstRowBuckleDriver 3;
BA_ "U_CD764_MY2022_Rx" SG_ 76 FirstRowBuckleDriver 1;
BA_ "GenSigStartValueInteger" SG_ 76 FirstRowBucklePsngr 3;
BA_ "GenSigStartValue" SG_ 76 FirstRowBucklePsngr 3;
BA_ "U_CD764_MY2022_Rx" SG_ 76 FirstRowBucklePsngr 1;
BA_ "WakeupSignal" SG_ 76 RstrnImpactEvntStatus 1;
BA_ "U_CX727_MY2021_Rx" SG_ 76 RstrnImpactEvntStatus 1;
BA_ "U_P702_MY2021_Rx" SG_ 76 RstrnImpactEvntStatus 1;
BA_ "U_T6_MCA_MY2020_Rx" SG_ 76 RstrnImpactEvntStatus 1;
BA_ "U_CD542_MY2021_Rx" SG_ 76 RstrnImpactEvntStatus 1;
BA_ "U_CD764_MY2022_Rx" SG_ 76 RstrnImpactEvntStatus 1;
BA_ "GenSigStartValueInteger" SG_ 76 PsngrFrntDetct_D_Actl 3;
BA_ "GenSigStartValue" SG_ 76 PsngrFrntDetct_D_Actl 3;
BA_ "U_CD764_MY2022_Rx" SG_ 76 PsngrFrntDetct_D_Actl 1;
BA_ "GenSigStartValueInteger" SG_ 76 PassRstrnInd_Req 3;
BA_ "GenSigStartValue" SG_ 76 PassRstrnInd_Req 3;
BA_ "GenSigStartValue" SG_ 1088 TrlrRng_L_Dsply 8190;
BA_ "WakeupSignal" SG_ 1088 ChrgStat_D2_Dsply 1;
BA_ "U_T6_MCA_MY2020_Rx" SG_ 1088 ChrgStat_D2_Dsply 1;
BA_ "U_CD542_MY2021_Rx" SG_ 1088 ChrgStat_D2_Dsply 1;
BA_ "WakeupSignal" SG_ 1088 HvacPrecondMode2_D_Rq 1;
BA_ "ContentDependant" SG_ 1088 HvacPrecondMode2_D_Rq 1;
BA_ "WakeupSignal" SG_ 1088 HvacPrecondBlwr2_D_Rq 1;
BA_ "ContentDependant" SG_ 1088 HvacPrecondBlwr2_D_Rq 1;
BA_ "GenSigStartValueInteger" SG_ 1088 HvacPrecond_Te_Rq 2;
BA_ "GenSigStartValue" SG_ 1088 HvacPrecond_Te_Rq 2;
BA_ "GenSigStartValue" SG_ 1088 BattDcChrgRms_I_Lim 32766;
BA_ "WakeupSignal" SG_ 433 KeyPadCodeDgt6_D_Dsply 1;
BA_ "WakeupSignal" SG_ 433 KeyPadCodeDgt5_D_Dsply 1;
BA_ "WakeupSignal" SG_ 433 KeyPadCodeDgt4_D_Dsply 1;
BA_ "WakeupSignal" SG_ 433 KeyPadCodeDgt3_D_Dsply 1;
BA_ "WakeupSignal" SG_ 433 KeyPadCodeDgt2_D_Dsply 1;
BA_ "WakeupSignal" SG_ 433 KeyPadCodeDgt1_D_Dsply 1;
BA_ "U_CX727_MY2021_Rx" SG_ 433 KeyOffMde_D_Actl 1;
BA_ "U_P702_MY2021_Rx" SG_ 433 KeyOffMde_D_Actl 1;
BA_ "U_T6_MCA_MY2020_Rx" SG_ 433 KeyOffMde_D_Actl 1;
BA_ "U_CD542_MY2021_Rx" SG_ 433 KeyOffMde_D_Actl 1;
BA_ "U_U55X_MY2022_Rx" SG_ 433 KeyOffMde_D_Actl 1;
BA_ "U_CD764_MY2022_Rx" SG_ 433 KeyOffMde_D_Actl 1;
BA_ "GenSigStartValueInteger" SG_ 145 VehYawWActl_D_Qf 1;
BA_ "MetaData" SG_ 145 VehYawWActl_D_Qf 1;
BA_ "GenSigStartValue" SG_ 145 VehYawWActl_D_Qf 1;
BA_ "U_CX727_MY2021_Rx" SG_ 145 VehYawWActl_D_Qf 1;
BA_ "U_P702_MY2021_Rx" SG_ 145 VehYawWActl_D_Qf 1;
BA_ "U_T6_MCA_MY2020_Rx" SG_ 145 VehYawWActl_D_Qf 1;
BA_ "U_CD542_MY2021_Rx" SG_ 145 VehYawWActl_D_Qf 1;
BA_ "U_CD764_MY2022_Rx" SG_ 145 VehYawWActl_D_Qf 1;
BA_ "GenSigStartValueInteger" SG_ 145 VehRolWActl_D_Qf 1;
BA_ "MetaData" SG_ 145 VehRolWActl_D_Qf 1;
BA_ "GenSigStartValue" SG_ 145 VehRolWActl_D_Qf 1;
BA_ "MetaData" SG_ 145 VehRollYawW_No_Cs 1;
BA_ "MetaData" SG_ 145 VehRollYaw_No_Cnt 1;
BA_ "U_CX727_MY2021_Rx" SG_ 145 VehRollYaw_No_Cnt 1;
BA_ "U_P702_MY2021_Rx" SG_ 145 VehRollYaw_No_Cnt 1;
BA_ "U_T6_MCA_MY2020_Rx" SG_ 145 VehRollYaw_No_Cnt 1;
BA_ "U_CD542_MY2021_Rx" SG_ 145 VehRollYaw_No_Cnt 1;
BA_ "U_CD764_MY2022_Rx" SG_ 145 VehRollYaw_No_Cnt 1;
BA_ "GenSigStartValueInteger" SG_ 145 VehYaw_W_Actl 65534;
BA_ "GenSigStartValue" SG_ 145 VehYaw_W_Actl 65534;
BA_ "U_CX727_MY2021_Rx" SG_ 145 VehYaw_W_Actl 1;
BA_ "U_P702_MY2021_Rx" SG_ 145 VehYaw_W_Actl 1;
BA_ "U_T6_MCA_MY2020_Rx" SG_ 145 VehYaw_W_Actl 1;
BA_ "U_CD542_MY2021_Rx" SG_ 145 VehYaw_W_Actl 1;
BA_ "U_CD764_MY2022_Rx" SG_ 145 VehYaw_W_Actl 1;
BA_ "GenSigStartValueInteger" SG_ 145 VehRol_W_Actl 65534;
BA_ "GenSigStartValue" SG_ 145 VehRol_W_Actl 65534;
BA_ "WakeupSignal" SG_ 626 PaakCtlRollCd2_No_Copy 1;
BA_ "GenSigSendType" SG_ 626 PaakCtlRollCd2_No_Copy 3;
BA_ "U_U55X_MY2022_Tx" SG_ 626 PaakCtlRollCd2_No_Copy 1;
BA_ "WakeupSignal" SG_ 626 PaakCtlIndx8_D_Stat 1;
BA_ "GenSigSendType" SG_ 626 PaakCtlIndx8_D_Stat 3;
BA_ "U_U55X_MY2022_Tx" SG_ 626 PaakCtlIndx8_D_Stat 1;
BA_ "WakeupSignal" SG_ 626 PaakCtlIndx7_D_Stat 1;
BA_ "GenSigSendType" SG_ 626 PaakCtlIndx7_D_Stat 3;
BA_ "U_U55X_MY2022_Tx" SG_ 626 PaakCtlIndx7_D_Stat 1;
BA_ "WakeupSignal" SG_ 626 PaakCtlIndx6_D_Stat 1;
BA_ "GenSigSendType" SG_ 626 PaakCtlIndx6_D_Stat 3;
BA_ "U_U55X_MY2022_Tx" SG_ 626 PaakCtlIndx6_D_Stat 1;
BA_ "WakeupSignal" SG_ 626 PaakCtlIndx5_D_Stat 1;
BA_ "GenSigSendType" SG_ 626 PaakCtlIndx5_D_Stat 3;
BA_ "U_U55X_MY2022_Tx" SG_ 626 PaakCtlIndx5_D_Stat 1;
BA_ "WakeupSignal" SG_ 626 PaakCtlIndx4_D_Stat 1;
BA_ "GenSigSendType" SG_ 626 PaakCtlIndx4_D_Stat 3;
BA_ "U_U55X_MY2022_Tx" SG_ 626 PaakCtlIndx4_D_Stat 1;
BA_ "WakeupSignal" SG_ 626 PaakCtlIndx3_D_Stat 1;
BA_ "GenSigSendType" SG_ 626 PaakCtlIndx3_D_Stat 3;
BA_ "U_U55X_MY2022_Tx" SG_ 626 PaakCtlIndx3_D_Stat 1;
BA_ "WakeupSignal" SG_ 626 PaakCtlIndx2_D_Stat 1;
BA_ "GenSigSendType" SG_ 626 PaakCtlIndx2_D_Stat 3;
BA_ "U_U55X_MY2022_Tx" SG_ 626 PaakCtlIndx2_D_Stat 1;
BA_ "WakeupSignal" SG_ 626 PaakCtlIndx1_D_Stat 1;
BA_ "GenSigSendType" SG_ 626 PaakCtlIndx1_D_Stat 3;
BA_ "U_U55X_MY2022_Tx" SG_ 626 PaakCtlIndx1_D_Stat 1;
BA_ "GenSigStartValueInteger" SG_ 1045 VehStab_D_Stat 14;
BA_ "GenSigStartValue" SG_ 1045 VehStab_D_Stat 14;
BA_ "GenSigStartValueInteger" SG_ 1045 VehYawNonLin_W_Rq 4094;
BA_ "GenSigStartValue" SG_ 1045 VehYawNonLin_W_Rq 4094;
BA_ "GenSigStartValueInteger" SG_ 1045 VehYawLin_W_Rq 4094;
BA_ "GenSigStartValue" SG_ 1045 VehYawLin_W_Rq 4094;
BA_ "MetaData" SG_ 1045 VehVActlBrk_No_Cs 1;
BA_ "U_U55X_MY2022_Rx" SG_ 1045 VehVActlBrk_No_Cs 1;
BA_ "U_U55X_MY2022_Rx" SG_ 1045 Veh_V_ActlBrk 1;
BA_ "MetaData" SG_ 1045 VehVActlBrk_No_Cnt 1;
BA_ "U_U55X_MY2022_Rx" SG_ 1045 VehVActlBrk_No_Cnt 1;
BA_ "MetaData" SG_ 1045 VehVActlBrk_D_Qf 1;
BA_ "U_U55X_MY2022_Rx" SG_ 1045 VehVActlBrk_D_Qf 1;
BA_ "U_CX727_MY2021_Rx" SG_ 1192 APIM_TCU_Word_Tx 1;
BA_ "U_P702_MY2021_Rx" SG_ 1192 APIM_TCU_Word_Tx 1;
BA_ "U_T6_MCA_MY2020_Rx" SG_ 1192 APIM_TCU_Word_Tx 1;
BA_ "U_CD542_MY2021_Rx" SG_ 1192 APIM_TCU_Word_Tx 1;
BA_ "U_U55X_MY2022_Rx" SG_ 1192 APIM_TCU_Word_Tx 1;
BA_ "U_CD764_MY2022_Rx" SG_ 1192 APIM_TCU_Word_Tx 1;
BA_ "U_U55X_MY2022_Rx" SG_ 267 GearPos_D_Trg_UB 1;
BA_ "GenSigStartValueInteger" SG_ 267 GearPos_D_Trg 15;
BA_ "ContentDependant" SG_ 267 GearPos_D_Trg 1;
BA_ "GenSigStartValue" SG_ 267 GearPos_D_Trg 15;
BA_ "GenSigSendType" SG_ 267 GearPos_D_Trg 3;
BA_ "U_U55X_MY2022_Rx" SG_ 267 GearPos_D_Trg 1;
BA_ "GenSigSendType" SG_ 267 BrkHold_D_Stat 3;
BA_ "U_U55X_MY2022_Rx" SG_ 267 BrkHold_D_Stat 1;
BA_ "U_U55X_MY2022_Rx" SG_ 267 PwPckTq_D_Stat_UB 1;
BA_ "GenSigSendType" SG_ 267 PwPckTq_D_Stat 3;
BA_ "U_U55X_MY2022_Rx" SG_ 267 PwPckTq_D_Stat 1;
BA_ "U_U55X_MY2022_Rx" SG_ 267 BrkHold_D_Stat_UB 1;
BA_ "U_U55X_MY2022_Rx" SG_ 267 TrlrLampCnnct_B_Actl_UB 1;
BA_ "GenSigSendType" SG_ 267 TrlrLampCnnct_B_Actl 3;
BA_ "U_U55X_MY2022_Rx" SG_ 267 TrlrLampCnnct_B_Actl 1;
BA_ "U_CX727_MY2021_Rx" SG_ 267 DISP_SetVolume_Rq_UB 1;
BA_ "U_P702_MY2021_Rx" SG_ 267 DISP_SetVolume_Rq_UB 1;
BA_ "U_T6_MCA_MY2020_Rx" SG_ 267 DISP_SetVolume_Rq_UB 1;
BA_ "U_CD542_MY2021_Rx" SG_ 267 DISP_SetVolume_Rq_UB 1;
BA_ "U_CD764_MY2022_Rx" SG_ 267 DISP_SetVolume_Rq_UB 1;
BA_ "GenSigStartValueInteger" SG_ 267 DISP_SetVolume_Rq 30;
BA_ "GenSigStartValue" SG_ 267 DISP_SetVolume_Rq 30;
BA_ "GenSigSendType" SG_ 267 DISP_SetVolume_Rq 3;
BA_ "U_CX727_MY2021_Rx" SG_ 267 DISP_SetVolume_Rq 1;
BA_ "U_P702_MY2021_Rx" SG_ 267 DISP_SetVolume_Rq 1;
BA_ "U_T6_MCA_MY2020_Rx" SG_ 267 DISP_SetVolume_Rq 1;
BA_ "U_CD542_MY2021_Rx" SG_ 267 DISP_SetVolume_Rq 1;
BA_ "U_CD764_MY2022_Rx" SG_ 267 DISP_SetVolume_Rq 1;
BA_ "GenSigSendType" SG_ 2612224076 PARSEDPushRFAtoGWM_ECG 3;
BA_ "ECGUsedRxSignal" SG_ 2612224076 PARSEDPushRFAtoGWM_ECG 1;
BA_ "U_CD764_MY2022_Rx" SG_ 2612224076 PARSEDPushRFAtoGWM_ECG 1;
BA_ "U_CD764_MY2022_Tx" SG_ 2612224076 PARSEDPushRFAtoGWM_ECG 1;
BA_ "GenSigSendType" SG_ 2611032280 PARSEDPhysGWM_ECGtoRFA 3;
BA_ "U_CD764_MY2022_Rx" SG_ 2611032280 PARSEDPhysGWM_ECGtoRFA 1;
BA_ "ECGUsedTxSignal" SG_ 2611032280 PARSEDPhysGWM_ECGtoRFA 1;
BA_ "U_CD764_MY2022_Tx" SG_ 2611032280 PARSEDPhysGWM_ECGtoRFA 1;
BA_ "U_CX727_MY2021_Rx" SG_ 351 LocationServices_2 1;
BA_ "U_CD542_MY2021_Rx" SG_ 351 LocationServices_2 1;
BA_ "U_U55X_MY2022_Rx" SG_ 351 LocationServices_2 1;
BA_ "U_CD764_MY2022_Rx" SG_ 351 LocationServices_2 1;
BA_ "U_CX727_MY2021_Rx" SG_ 350 LocationServices_1 1;
BA_ "U_P702_MY2021_Rx" SG_ 350 LocationServices_1 1;
BA_ "U_T6_MCA_MY2020_Rx" SG_ 350 LocationServices_1 1;
BA_ "U_CD542_MY2021_Rx" SG_ 350 LocationServices_1 1;
BA_ "U_U55X_MY2022_Rx" SG_ 350 LocationServices_1 1;
BA_ "U_CD764_MY2022_Rx" SG_ 350 LocationServices_1 1;
BA_ "U_CX727_MY2021_Rx" SG_ 290 WifiHtsptFqBand_D_Rq 1;
BA_ "U_P702_MY2021_Rx" SG_ 290 WifiHtsptFqBand_D_Rq 1;
BA_ "U_T6_MCA_MY2020_Rx" SG_ 290 WifiHtsptFqBand_D_Rq 1;
BA_ "U_CD542_MY2021_Rx" SG_ 290 WifiHtsptFqBand_D_Rq 1;
BA_ "U_U55X_MY2022_Rx" SG_ 290 WifiHtsptFqBand_D_Rq 1;
BA_ "U_CD764_MY2022_Rx" SG_ 290 WifiHtsptFqBand_D_Rq 1;
BA_ "U_CX727_MY2021_Rx" SG_ 290 WifiHtsptTrial_D_RqDrv 1;
BA_ "U_P702_MY2021_Rx" SG_ 290 WifiHtsptTrial_D_RqDrv 1;
BA_ "U_T6_MCA_MY2020_Rx" SG_ 290 WifiHtsptTrial_D_RqDrv 1;
BA_ "U_CD542_MY2021_Rx" SG_ 290 WifiHtsptTrial_D_RqDrv 1;
BA_ "U_U55X_MY2022_Rx" SG_ 290 WifiHtsptTrial_D_RqDrv 1;
BA_ "U_CD764_MY2022_Rx" SG_ 290 WifiHtsptTrial_D_RqDrv 1;
BA_ "U_CX727_MY2021_Rx" SG_ 290 WifiHtsptEnbl_D_Rq 1;
BA_ "U_P702_MY2021_Rx" SG_ 290 WifiHtsptEnbl_D_Rq 1;
BA_ "U_T6_MCA_MY2020_Rx" SG_ 290 WifiHtsptEnbl_D_Rq 1;
BA_ "U_CD542_MY2021_Rx" SG_ 290 WifiHtsptEnbl_D_Rq 1;
BA_ "U_U55X_MY2022_Rx" SG_ 290 WifiHtsptEnbl_D_Rq 1;
BA_ "U_CD764_MY2022_Rx" SG_ 290 WifiHtsptEnbl_D_Rq 1;
BA_ "GenSigStartValueInteger" SG_ 290 WifiRemoveIndx_No_Rq 20;
BA_ "GenSigStartValue" SG_ 290 WifiRemoveIndx_No_Rq 20;
BA_ "U_CX727_MY2021_Rx" SG_ 290 WifiRemoveIndx_No_Rq 1;
BA_ "U_P702_MY2021_Rx" SG_ 290 WifiRemoveIndx_No_Rq 1;
BA_ "U_T6_MCA_MY2020_Rx" SG_ 290 WifiRemoveIndx_No_Rq 1;
BA_ "U_CD542_MY2021_Rx" SG_ 290 WifiRemoveIndx_No_Rq 1;
BA_ "U_U55X_MY2022_Rx" SG_ 290 WifiRemoveIndx_No_Rq 1;
BA_ "U_CD764_MY2022_Rx" SG_ 290 WifiRemoveIndx_No_Rq 1;
BA_ "U_CX727_MY2021_Rx" SG_ 290 WifiRemoveDevc_D_Rq 1;
BA_ "U_P702_MY2021_Rx" SG_ 290 WifiRemoveDevc_D_Rq 1;
BA_ "U_T6_MCA_MY2020_Rx" SG_ 290 WifiRemoveDevc_D_Rq 1;
BA_ "U_CD542_MY2021_Rx" SG_ 290 WifiRemoveDevc_D_Rq 1;
BA_ "U_U55X_MY2022_Rx" SG_ 290 WifiRemoveDevc_D_Rq 1;
BA_ "U_CD764_MY2022_Rx" SG_ 290 WifiRemoveDevc_D_Rq 1;
BA_ "U_CX727_MY2021_Rx" SG_ 290 WifiHtsptVisbl_D_Rq 1;
BA_ "U_P702_MY2021_Rx" SG_ 290 WifiHtsptVisbl_D_Rq 1;
BA_ "U_T6_MCA_MY2020_Rx" SG_ 290 WifiHtsptVisbl_D_Rq 1;
BA_ "U_CD542_MY2021_Rx" SG_ 290 WifiHtsptVisbl_D_Rq 1;
BA_ "U_U55X_MY2022_Rx" SG_ 290 WifiHtsptVisbl_D_Rq 1;
BA_ "U_CD764_MY2022_Rx" SG_ 290 WifiHtsptVisbl_D_Rq 1;
BA_ "U_CX727_MY2021_Rx" SG_ 290 WifiHtsptMacAddr_B_Rq 1;
BA_ "U_P702_MY2021_Rx" SG_ 290 WifiHtsptMacAddr_B_Rq 1;
BA_ "U_T6_MCA_MY2020_Rx" SG_ 290 WifiHtsptMacAddr_B_Rq 1;
BA_ "U_CD542_MY2021_Rx" SG_ 290 WifiHtsptMacAddr_B_Rq 1;
BA_ "U_U55X_MY2022_Rx" SG_ 290 WifiHtsptMacAddr_B_Rq 1;
BA_ "U_CD764_MY2022_Rx" SG_ 290 WifiHtsptMacAddr_B_Rq 1;
BA_ "U_CX727_MY2021_Rx" SG_ 290 WifiDevcListSize_D_Rq 1;
BA_ "U_P702_MY2021_Rx" SG_ 290 WifiDevcListSize_D_Rq 1;
BA_ "U_T6_MCA_MY2020_Rx" SG_ 290 WifiDevcListSize_D_Rq 1;
BA_ "U_CD542_MY2021_Rx" SG_ 290 WifiDevcListSize_D_Rq 1;
BA_ "U_U55X_MY2022_Rx" SG_ 290 WifiDevcListSize_D_Rq 1;
BA_ "U_CD764_MY2022_Rx" SG_ 290 WifiDevcListSize_D_Rq 1;
BA_ "GenSigStartValueInteger" SG_ 290 WifiDevcListIndx_No_Rq 22;
BA_ "GenSigStartValue" SG_ 290 WifiDevcListIndx_No_Rq 22;
BA_ "U_CX727_MY2021_Rx" SG_ 290 WifiDevcListIndx_No_Rq 1;
BA_ "U_P702_MY2021_Rx" SG_ 290 WifiDevcListIndx_No_Rq 1;
BA_ "U_T6_MCA_MY2020_Rx" SG_ 290 WifiDevcListIndx_No_Rq 1;
BA_ "U_CD542_MY2021_Rx" SG_ 290 WifiDevcListIndx_No_Rq 1;
BA_ "U_U55X_MY2022_Rx" SG_ 290 WifiDevcListIndx_No_Rq 1;
BA_ "U_CD764_MY2022_Rx" SG_ 290 WifiDevcListIndx_No_Rq 1;
BA_ "U_CX727_MY2021_Rx" SG_ 290 WifiDevcList_D_Rq 1;
BA_ "U_P702_MY2021_Rx" SG_ 290 WifiDevcList_D_Rq 1;
BA_ "U_T6_MCA_MY2020_Rx" SG_ 290 WifiDevcList_D_Rq 1;
BA_ "U_CD542_MY2021_Rx" SG_ 290 WifiDevcList_D_Rq 1;
BA_ "U_U55X_MY2022_Rx" SG_ 290 WifiDevcList_D_Rq 1;
BA_ "U_CD764_MY2022_Rx" SG_ 290 WifiDevcList_D_Rq 1;
BA_ "U_CX727_MY2021_Rx" SG_ 290 WifiDataUsage_D_Rq 1;
BA_ "U_P702_MY2021_Rx" SG_ 290 WifiDataUsage_D_Rq 1;
BA_ "U_T6_MCA_MY2020_Rx" SG_ 290 WifiDataUsage_D_Rq 1;
BA_ "U_CD542_MY2021_Rx" SG_ 290 WifiDataUsage_D_Rq 1;
BA_ "U_U55X_MY2022_Rx" SG_ 290 WifiDataUsage_D_Rq 1;
BA_ "U_CD764_MY2022_Rx" SG_ 290 WifiDataUsage_D_Rq 1;
BA_ "U_CX727_MY2021_Rx" SG_ 290 WifiCarrierInfo_B_Rq 1;
BA_ "U_P702_MY2021_Rx" SG_ 290 WifiCarrierInfo_B_Rq 1;
BA_ "U_T6_MCA_MY2020_Rx" SG_ 290 WifiCarrierInfo_B_Rq 1;
BA_ "U_CD542_MY2021_Rx" SG_ 290 WifiCarrierInfo_B_Rq 1;
BA_ "U_U55X_MY2022_Rx" SG_ 290 WifiCarrierInfo_B_Rq 1;
BA_ "U_CD764_MY2022_Rx" SG_ 290 WifiCarrierInfo_B_Rq 1;
BA_ "GenSigSendType" SG_ 542 LocationServices_3 3;
BA_ "U_CX727_MY2021_Rx" SG_ 542 LocationServices_3 1;
BA_ "U_CD542_MY2021_Rx" SG_ 542 LocationServices_3 1;
BA_ "U_U55X_MY2022_Rx" SG_ 542 LocationServices_3 1;
BA_ "U_CD764_MY2022_Rx" SG_ 542 LocationServices_3 1;
BA_ "U_CX727_MY2021_Tx" SG_ 542 LocationServices_3 1;
BA_ "U_P702_MY2021_Tx" SG_ 542 LocationServices_3 1;
BA_ "U_T6_MCA_MY2020_Tx" SG_ 542 LocationServices_3 1;
BA_ "U_CD542_MY2021_Tx" SG_ 542 LocationServices_3 1;
BA_ "U_U55X_MY2022_Tx" SG_ 542 LocationServices_3 1;
BA_ "U_CD764_MY2022_Tx" SG_ 542 LocationServices_3 1;
BA_ "GenSigSendType" SG_ 1849 TesterPhysicalResRFA 3;
BA_ "U_CX727_MY2021_Tx" SG_ 1849 TesterPhysicalResRFA 1;
BA_ "U_CD542_MY2021_Tx" SG_ 1849 TesterPhysicalResRFA 1;
BA_ "U_U55X_MY2022_Tx" SG_ 1849 TesterPhysicalResRFA 1;
BA_ "U_CD764_MY2022_Tx" SG_ 1849 TesterPhysicalResRFA 1;
BA_ "U_CX727_MY2021_Rx" SG_ 132 GlblClkYr_No_Actl 1;
BA_ "U_P702_MY2021_Rx" SG_ 132 GlblClkYr_No_Actl 1;
BA_ "U_T6_MCA_MY2020_Rx" SG_ 132 GlblClkYr_No_Actl 1;
BA_ "U_CD542_MY2021_Rx" SG_ 132 GlblClkYr_No_Actl 1;
BA_ "U_U55X_MY2022_Rx" SG_ 132 GlblClkYr_No_Actl 1;
BA_ "U_CD764_MY2022_Rx" SG_ 132 GlblClkYr_No_Actl 1;
BA_ "U_CX727_MY2021_Rx" SG_ 132 GlblClkScnd_No_Actl 1;
BA_ "U_P702_MY2021_Rx" SG_ 132 GlblClkScnd_No_Actl 1;
BA_ "U_T6_MCA_MY2020_Rx" SG_ 132 GlblClkScnd_No_Actl 1;
BA_ "U_CD542_MY2021_Rx" SG_ 132 GlblClkScnd_No_Actl 1;
BA_ "U_U55X_MY2022_Rx" SG_ 132 GlblClkScnd_No_Actl 1;
BA_ "U_CD764_MY2022_Rx" SG_ 132 GlblClkScnd_No_Actl 1;
BA_ "U_CX727_MY2021_Rx" SG_ 132 GlblClkMnte_No_Actl 1;
BA_ "U_P702_MY2021_Rx" SG_ 132 GlblClkMnte_No_Actl 1;
BA_ "U_T6_MCA_MY2020_Rx" SG_ 132 GlblClkMnte_No_Actl 1;
BA_ "U_CD542_MY2021_Rx" SG_ 132 GlblClkMnte_No_Actl 1;
BA_ "U_U55X_MY2022_Rx" SG_ 132 GlblClkMnte_No_Actl 1;
BA_ "U_CD764_MY2022_Rx" SG_ 132 GlblClkMnte_No_Actl 1;
BA_ "U_CX727_MY2021_Rx" SG_ 132 GlblClkHr_No_Actl 1;
BA_ "U_P702_MY2021_Rx" SG_ 132 GlblClkHr_No_Actl 1;
BA_ "U_T6_MCA_MY2020_Rx" SG_ 132 GlblClkHr_No_Actl 1;
BA_ "U_CD542_MY2021_Rx" SG_ 132 GlblClkHr_No_Actl 1;
BA_ "U_U55X_MY2022_Rx" SG_ 132 GlblClkHr_No_Actl 1;
BA_ "U_CD764_MY2022_Rx" SG_ 132 GlblClkHr_No_Actl 1;
BA_ "U_CX727_MY2021_Rx" SG_ 132 GlblClkDay_No_Actl 1;
BA_ "U_P702_MY2021_Rx" SG_ 132 GlblClkDay_No_Actl 1;
BA_ "U_T6_MCA_MY2020_Rx" SG_ 132 GlblClkDay_No_Actl 1;
BA_ "U_CD542_MY2021_Rx" SG_ 132 GlblClkDay_No_Actl 1;
BA_ "U_U55X_MY2022_Rx" SG_ 132 GlblClkDay_No_Actl 1;
BA_ "U_CD764_MY2022_Rx" SG_ 132 GlblClkDay_No_Actl 1;
BA_ "GenSigSendType" SG_ 636 WifiHtsptFqBand_D_Stat 3;
BA_ "U_CX727_MY2021_Tx" SG_ 636 WifiHtsptFqBand_D_Stat 1;
BA_ "U_T6_MCA_MY2020_Tx" SG_ 636 WifiHtsptFqBand_D_Stat 1;
BA_ "U_CD542_MY2021_Tx" SG_ 636 WifiHtsptFqBand_D_Stat 1;
BA_ "U_U55X_MY2022_Tx" SG_ 636 WifiHtsptFqBand_D_Stat 1;
BA_ "U_CD764_MY2022_Tx" SG_ 636 WifiHtsptFqBand_D_Stat 1;
BA_ "GenSigSendType" SG_ 636 WifiHtspt_D_Falt 3;
BA_ "U_CX727_MY2021_Tx" SG_ 636 WifiHtspt_D_Falt 1;
BA_ "U_T6_MCA_MY2020_Tx" SG_ 636 WifiHtspt_D_Falt 1;
BA_ "U_CD542_MY2021_Tx" SG_ 636 WifiHtspt_D_Falt 1;
BA_ "U_U55X_MY2022_Tx" SG_ 636 WifiHtspt_D_Falt 1;
BA_ "U_CD764_MY2022_Tx" SG_ 636 WifiHtspt_D_Falt 1;
BA_ "U_CX727_MY2021_Tx" SG_ 636 WifiNoDevcCnnct_No_Actl 1;
BA_ "U_P702_MY2021_Tx" SG_ 636 WifiNoDevcCnnct_No_Actl 1;
BA_ "U_T6_MCA_MY2020_Tx" SG_ 636 WifiNoDevcCnnct_No_Actl 1;
BA_ "U_CD542_MY2021_Tx" SG_ 636 WifiNoDevcCnnct_No_Actl 1;
BA_ "U_U55X_MY2022_Tx" SG_ 636 WifiNoDevcCnnct_No_Actl 1;
BA_ "U_CD764_MY2022_Tx" SG_ 636 WifiNoDevcCnnct_No_Actl 1;
BA_ "GenSigSendType" SG_ 636 WifiHtsptCnnct_D_Stat 3;
BA_ "U_CX727_MY2021_Tx" SG_ 636 WifiHtsptCnnct_D_Stat 1;
BA_ "U_P702_MY2021_Tx" SG_ 636 WifiHtsptCnnct_D_Stat 1;
BA_ "U_T6_MCA_MY2020_Tx" SG_ 636 WifiHtsptCnnct_D_Stat 1;
BA_ "U_CD542_MY2021_Tx" SG_ 636 WifiHtsptCnnct_D_Stat 1;
BA_ "U_U55X_MY2022_Tx" SG_ 636 WifiHtsptCnnct_D_Stat 1;
BA_ "U_CD764_MY2022_Tx" SG_ 636 WifiHtsptCnnct_D_Stat 1;
BA_ "GenSigSendType" SG_ 636 Telematics_D_Falt 3;
BA_ "U_CX727_MY2021_Tx" SG_ 636 Telematics_D_Falt 1;
BA_ "U_P702_MY2021_Tx" SG_ 636 Telematics_D_Falt 1;
BA_ "U_T6_MCA_MY2020_Tx" SG_ 636 Telematics_D_Falt 1;
BA_ "U_CD542_MY2021_Tx" SG_ 636 Telematics_D_Falt 1;
BA_ "U_U55X_MY2022_Tx" SG_ 636 Telematics_D_Falt 1;
BA_ "U_CD764_MY2022_Tx" SG_ 636 Telematics_D_Falt 1;
BA_ "GenSigSendType" SG_ 636 WifiEnbl_D_Stat 3;
BA_ "U_CX727_MY2021_Tx" SG_ 636 WifiEnbl_D_Stat 1;
BA_ "U_P702_MY2021_Tx" SG_ 636 WifiEnbl_D_Stat 1;
BA_ "U_T6_MCA_MY2020_Tx" SG_ 636 WifiEnbl_D_Stat 1;
BA_ "U_CD542_MY2021_Tx" SG_ 636 WifiEnbl_D_Stat 1;
BA_ "U_U55X_MY2022_Tx" SG_ 636 WifiEnbl_D_Stat 1;
BA_ "U_CD764_MY2022_Tx" SG_ 636 WifiEnbl_D_Stat 1;
BA_ "GenSigSendType" SG_ 636 WifiHtsptVisbl_D_Stat 3;
BA_ "U_CX727_MY2021_Tx" SG_ 636 WifiHtsptVisbl_D_Stat 1;
BA_ "U_P702_MY2021_Tx" SG_ 636 WifiHtsptVisbl_D_Stat 1;
BA_ "U_T6_MCA_MY2020_Tx" SG_ 636 WifiHtsptVisbl_D_Stat 1;
BA_ "U_CD542_MY2021_Tx" SG_ 636 WifiHtsptVisbl_D_Stat 1;
BA_ "U_U55X_MY2022_Tx" SG_ 636 WifiHtsptVisbl_D_Stat 1;
BA_ "U_CD764_MY2022_Tx" SG_ 636 WifiHtsptVisbl_D_Stat 1;
BA_ "GenSigSendType" SG_ 636 WifiHtsptScrty_D_Stat 3;
BA_ "U_CX727_MY2021_Tx" SG_ 636 WifiHtsptScrty_D_Stat 1;
BA_ "U_P702_MY2021_Tx" SG_ 636 WifiHtsptScrty_D_Stat 1;
BA_ "U_T6_MCA_MY2020_Tx" SG_ 636 WifiHtsptScrty_D_Stat 1;
BA_ "U_CD542_MY2021_Tx" SG_ 636 WifiHtsptScrty_D_Stat 1;
BA_ "U_U55X_MY2022_Tx" SG_ 636 WifiHtsptScrty_D_Stat 1;
BA_ "U_CD764_MY2022_Tx" SG_ 636 WifiHtsptScrty_D_Stat 1;
BA_ "GenSigSendType" SG_ 636 WifiHtsptEnbl_D_Stat 3;
BA_ "U_CX727_MY2021_Tx" SG_ 636 WifiHtsptEnbl_D_Stat 1;
BA_ "U_P702_MY2021_Tx" SG_ 636 WifiHtsptEnbl_D_Stat 1;
BA_ "U_T6_MCA_MY2020_Tx" SG_ 636 WifiHtsptEnbl_D_Stat 1;
BA_ "U_CD542_MY2021_Tx" SG_ 636 WifiHtsptEnbl_D_Stat 1;
BA_ "U_U55X_MY2022_Tx" SG_ 636 WifiHtsptEnbl_D_Stat 1;
BA_ "U_CD764_MY2022_Tx" SG_ 636 WifiHtsptEnbl_D_Stat 1;
BA_ "GenSigSendType" SG_ 636 WifiDevcListNew_B_Stat 3;
BA_ "U_CX727_MY2021_Tx" SG_ 636 WifiDevcListNew_B_Stat 1;
BA_ "U_P702_MY2021_Tx" SG_ 636 WifiDevcListNew_B_Stat 1;
BA_ "U_T6_MCA_MY2020_Tx" SG_ 636 WifiDevcListNew_B_Stat 1;
BA_ "U_CD542_MY2021_Tx" SG_ 636 WifiDevcListNew_B_Stat 1;
BA_ "U_U55X_MY2022_Tx" SG_ 636 WifiDevcListNew_B_Stat 1;
BA_ "U_CD764_MY2022_Tx" SG_ 636 WifiDevcListNew_B_Stat 1;
BA_ "U_CX727_MY2021_Tx" SG_ 636 WifiDataUsage_Pc_Actl 1;
BA_ "U_P702_MY2021_Tx" SG_ 636 WifiDataUsage_Pc_Actl 1;
BA_ "U_T6_MCA_MY2020_Tx" SG_ 636 WifiDataUsage_Pc_Actl 1;
BA_ "U_CD542_MY2021_Tx" SG_ 636 WifiDataUsage_Pc_Actl 1;
BA_ "U_U55X_MY2022_Tx" SG_ 636 WifiDataUsage_Pc_Actl 1;
BA_ "U_CD764_MY2022_Tx" SG_ 636 WifiDataUsage_Pc_Actl 1;
BA_ "GenSigSendType" SG_ 636 WifiDataUsage_D_Stat 3;
BA_ "U_CX727_MY2021_Tx" SG_ 636 WifiDataUsage_D_Stat 1;
BA_ "U_P702_MY2021_Tx" SG_ 636 WifiDataUsage_D_Stat 1;
BA_ "U_T6_MCA_MY2020_Tx" SG_ 636 WifiDataUsage_D_Stat 1;
BA_ "U_CD542_MY2021_Tx" SG_ 636 WifiDataUsage_D_Stat 1;
BA_ "U_U55X_MY2022_Tx" SG_ 636 WifiDataUsage_D_Stat 1;
BA_ "U_CD764_MY2022_Tx" SG_ 636 WifiDataUsage_D_Stat 1;
BA_ "GenSigStartValueInteger" SG_ 636 ModemSigStren_D_Stat 6;
BA_ "GenSigStartValue" SG_ 636 ModemSigStren_D_Stat 6;
BA_ "GenSigSendType" SG_ 636 ModemSigStren_D_Stat 3;
BA_ "U_CX727_MY2021_Tx" SG_ 636 ModemSigStren_D_Stat 1;
BA_ "U_P702_MY2021_Tx" SG_ 636 ModemSigStren_D_Stat 1;
BA_ "U_T6_MCA_MY2020_Tx" SG_ 636 ModemSigStren_D_Stat 1;
BA_ "U_CD542_MY2021_Tx" SG_ 636 ModemSigStren_D_Stat 1;
BA_ "U_U55X_MY2022_Tx" SG_ 636 ModemSigStren_D_Stat 1;
BA_ "U_CD764_MY2022_Tx" SG_ 636 ModemSigStren_D_Stat 1;
BA_ "GenSigSendType" SG_ 636 WifiHtsptCrdntl_B_Stat 3;
BA_ "U_T6_MCA_MY2020_Tx" SG_ 636 WifiHtsptCrdntl_B_Stat 1;
BA_ "U_CD542_MY2021_Tx" SG_ 636 WifiHtsptCrdntl_B_Stat 1;
BA_ "U_U55X_MY2022_Tx" SG_ 636 WifiHtsptCrdntl_B_Stat 1;
BA_ "U_CD764_MY2022_Tx" SG_ 636 WifiHtsptCrdntl_B_Stat 1;
BA_ "GenSigSendType" SG_ 636 WifiHtsptFq_D_Avail 3;
BA_ "U_CX727_MY2021_Tx" SG_ 636 WifiHtsptFq_D_Avail 1;
BA_ "U_T6_MCA_MY2020_Tx" SG_ 636 WifiHtsptFq_D_Avail 1;
BA_ "U_CD542_MY2021_Tx" SG_ 636 WifiHtsptFq_D_Avail 1;
BA_ "U_U55X_MY2022_Tx" SG_ 636 WifiHtsptFq_D_Avail 1;
BA_ "U_CD764_MY2022_Tx" SG_ 636 WifiHtsptFq_D_Avail 1;
BA_ "GenSigSendType" SG_ 636 WifiDataUsageOn_D_Stat 3;
BA_ "U_CX727_MY2021_Tx" SG_ 636 WifiDataUsageOn_D_Stat 1;
BA_ "U_P702_MY2021_Tx" SG_ 636 WifiDataUsageOn_D_Stat 1;
BA_ "U_T6_MCA_MY2020_Tx" SG_ 636 WifiDataUsageOn_D_Stat 1;
BA_ "U_CD542_MY2021_Tx" SG_ 636 WifiDataUsageOn_D_Stat 1;
BA_ "U_U55X_MY2022_Tx" SG_ 636 WifiDataUsageOn_D_Stat 1;
BA_ "U_CD764_MY2022_Tx" SG_ 636 WifiDataUsageOn_D_Stat 1;
BA_ "GenSigSendType" SG_ 636 ModemTechnology_D2_Stat 3;
BA_ "U_CX727_MY2021_Tx" SG_ 636 ModemTechnology_D2_Stat 1;
BA_ "U_P702_MY2021_Tx" SG_ 636 ModemTechnology_D2_Stat 1;
BA_ "U_T6_MCA_MY2020_Tx" SG_ 636 ModemTechnology_D2_Stat 1;
BA_ "U_CD542_MY2021_Tx" SG_ 636 ModemTechnology_D2_Stat 1;
BA_ "U_U55X_MY2022_Tx" SG_ 636 ModemTechnology_D2_Stat 1;
BA_ "U_CD764_MY2022_Tx" SG_ 636 ModemTechnology_D2_Stat 1;
BA_ "U_U55X_MY2022_Tx" SG_ 895 TurnLght_D_RqRmtCtl 1;
BA_ "U_U55X_MY2022_Tx" SG_ 895 RmtCtlRngSet_D_Rq 1;
BA_ "U_U55X_MY2022_Tx" SG_ 895 RmtCtlRes_D_Stat 1;
BA_ "U_U55X_MY2022_Tx" SG_ 895 RmtCtlKeyPoll_D_Rq 1;
BA_ "MetaData" SG_ 895 RmtCtlDStat_No_Cs 1;
BA_ "U_U55X_MY2022_Tx" SG_ 895 RmtCtlDStat_No_Cs 1;
BA_ "MetaData" SG_ 895 RmtCtlDStat_No_Cnt 1;
BA_ "U_U55X_MY2022_Tx" SG_ 895 RmtCtlDStat_No_Cnt 1;
BA_ "U_U55X_MY2022_Tx" SG_ 895 RmtCtlCntnsIn_B_Stat 1;
BA_ "WakeupSignal" SG_ 895 RmtCtl_D_Stat 1;
BA_ "U_U55X_MY2022_Tx" SG_ 895 RmtCtl_D_Stat 1;
BA_ "GenSigSendType" SG_ 1841 TesterPhysicalReqRFA 3;
BA_ "U_CX727_MY2021_Rx" SG_ 1841 TesterPhysicalReqRFA 1;
BA_ "U_CD542_MY2021_Rx" SG_ 1841 TesterPhysicalReqRFA 1;
BA_ "U_U55X_MY2022_Rx" SG_ 1841 TesterPhysicalReqRFA 1;
BA_ "U_CD764_MY2022_Rx" SG_ 1841 TesterPhysicalReqRFA 1;
BA_ "GenSigStartValueInteger" SG_ 1416 RFA_GWOnBoardTester 255;
BA_ "ContentDependant" SG_ 1416 RFA_GWOnBoardTester 1;
BA_ "GenSigStartValue" SG_ 1416 RFA_GWOnBoardTester 255;
BA_ "U_CX727_MY2021_Tx" SG_ 1416 RFA_GWOnBoardTester 1;
BA_ "U_CD542_MY2021_Tx" SG_ 1416 RFA_GWOnBoardTester 1;
BA_ "U_U55X_MY2022_Tx" SG_ 1416 RFA_GWOnBoardTester 1;
BA_ "U_CD764_MY2022_Tx" SG_ 1416 RFA_GWOnBoardTester 1;
BA_ "GenSigStartValueInteger" SG_ 1416 RFA_GWNMProxy 255;
BA_ "ContentDependant" SG_ 1416 RFA_GWNMProxy 1;
BA_ "GenSigStartValue" SG_ 1416 RFA_GWNMProxy 255;
BA_ "U_CX727_MY2021_Tx" SG_ 1416 RFA_GWNMProxy 1;
BA_ "U_CD542_MY2021_Tx" SG_ 1416 RFA_GWNMProxy 1;
BA_ "U_U55X_MY2022_Tx" SG_ 1416 RFA_GWNMProxy 1;
BA_ "U_CD764_MY2022_Tx" SG_ 1416 RFA_GWNMProxy 1;
BA_ "GenSigStartValueInteger" SG_ 1416 RFA_AutoSarNMReserved4 255;
BA_ "ContentDependant" SG_ 1416 RFA_AutoSarNMReserved4 1;
BA_ "GenSigStartValue" SG_ 1416 RFA_AutoSarNMReserved4 255;
BA_ "U_CX727_MY2021_Tx" SG_ 1416 RFA_AutoSarNMReserved4 1;
BA_ "U_CD542_MY2021_Tx" SG_ 1416 RFA_AutoSarNMReserved4 1;
BA_ "U_U55X_MY2022_Tx" SG_ 1416 RFA_AutoSarNMReserved4 1;
BA_ "U_CD764_MY2022_Tx" SG_ 1416 RFA_AutoSarNMReserved4 1;
BA_ "GenSigStartValueInteger" SG_ 1416 RFA_AutoSarNMReserved3 255;
BA_ "ContentDependant" SG_ 1416 RFA_AutoSarNMReserved3 1;
BA_ "GenSigStartValue" SG_ 1416 RFA_AutoSarNMReserved3 255;
BA_ "U_CX727_MY2021_Tx" SG_ 1416 RFA_AutoSarNMReserved3 1;
BA_ "U_CD542_MY2021_Tx" SG_ 1416 RFA_AutoSarNMReserved3 1;
BA_ "U_U55X_MY2022_Tx" SG_ 1416 RFA_AutoSarNMReserved3 1;
BA_ "U_CD764_MY2022_Tx" SG_ 1416 RFA_AutoSarNMReserved3 1;
BA_ "GenSigStartValueInteger" SG_ 1416 RFA_AutoSarNMReserved2 255;
BA_ "ContentDependant" SG_ 1416 RFA_AutoSarNMReserved2 1;
BA_ "GenSigStartValue" SG_ 1416 RFA_AutoSarNMReserved2 255;
BA_ "U_CX727_MY2021_Tx" SG_ 1416 RFA_AutoSarNMReserved2 1;
BA_ "U_CD542_MY2021_Tx" SG_ 1416 RFA_AutoSarNMReserved2 1;
BA_ "U_U55X_MY2022_Tx" SG_ 1416 RFA_AutoSarNMReserved2 1;
BA_ "U_CD764_MY2022_Tx" SG_ 1416 RFA_AutoSarNMReserved2 1;
BA_ "GenSigStartValueInteger" SG_ 1416 RFA_AutoSarNMReserved1 255;
BA_ "ContentDependant" SG_ 1416 RFA_AutoSarNMReserved1 1;
BA_ "GenSigStartValue" SG_ 1416 RFA_AutoSarNMReserved1 255;
BA_ "U_CX727_MY2021_Tx" SG_ 1416 RFA_AutoSarNMReserved1 1;
BA_ "U_CD542_MY2021_Tx" SG_ 1416 RFA_AutoSarNMReserved1 1;
BA_ "U_U55X_MY2022_Tx" SG_ 1416 RFA_AutoSarNMReserved1 1;
BA_ "U_CD764_MY2022_Tx" SG_ 1416 RFA_AutoSarNMReserved1 1;
BA_ "GenSigStartValueInteger" SG_ 1416 RFA_AutoSarNMNodeId 136;
BA_ "ContentDependant" SG_ 1416 RFA_AutoSarNMNodeId 1;
BA_ "GenSigStartValue" SG_ 1416 RFA_AutoSarNMNodeId 136;
BA_ "U_CX727_MY2021_Tx" SG_ 1416 RFA_AutoSarNMNodeId 1;
BA_ "U_CD542_MY2021_Tx" SG_ 1416 RFA_AutoSarNMNodeId 1;
BA_ "U_U55X_MY2022_Tx" SG_ 1416 RFA_AutoSarNMNodeId 1;
BA_ "U_CD764_MY2022_Tx" SG_ 1416 RFA_AutoSarNMNodeId 1;
BA_ "ContentDependant" SG_ 1416 RFA_AutoSarNMControl 1;
BA_ "U_CX727_MY2021_Tx" SG_ 1416 RFA_AutoSarNMControl 1;
BA_ "U_CD542_MY2021_Tx" SG_ 1416 RFA_AutoSarNMControl 1;
BA_ "U_U55X_MY2022_Tx" SG_ 1416 RFA_AutoSarNMControl 1;
BA_ "U_CD764_MY2022_Tx" SG_ 1416 RFA_AutoSarNMControl 1;
BA_ "U_CX727_MY2021_Rx" SG_ 265 OdometerMasterValue_UB 1;
BA_ "U_P702_MY2021_Rx" SG_ 265 OdometerMasterValue_UB 1;
BA_ "U_T6_MCA_MY2020_Rx" SG_ 265 OdometerMasterValue_UB 1;
BA_ "U_CD542_MY2021_Rx" SG_ 265 OdometerMasterValue_UB 1;
BA_ "U_U55X_MY2022_Rx" SG_ 265 OdometerMasterValue_UB 1;
BA_ "U_CD764_MY2022_Rx" SG_ 265 OdometerMasterValue_UB 1;
BA_ "U_CX727_MY2021_Rx" SG_ 265 OdometerMasterValue 1;
BA_ "U_P702_MY2021_Rx" SG_ 265 OdometerMasterValue 1;
BA_ "U_T6_MCA_MY2020_Rx" SG_ 265 OdometerMasterValue 1;
BA_ "U_CD542_MY2021_Rx" SG_ 265 OdometerMasterValue 1;
BA_ "U_U55X_MY2022_Rx" SG_ 265 OdometerMasterValue 1;
BA_ "U_CD764_MY2022_Rx" SG_ 265 OdometerMasterValue 1;
BA_ "U_U55X_MY2022_Rx" SG_ 266 TCMode_UB 1;
BA_ "ContentDependant" SG_ 266 TCMode 1;
BA_ "GenSigSendType" SG_ 266 TCMode 3;
BA_ "U_U55X_MY2022_Rx" SG_ 266 TCMode 1;
BA_ "U_CX727_MY2021_Rx" SG_ 266 Disp_LangSel2_St_UB 1;
BA_ "U_P702_MY2021_Rx" SG_ 266 Disp_LangSel2_St_UB 1;
BA_ "U_T6_MCA_MY2020_Rx" SG_ 266 Disp_LangSel2_St_UB 1;
BA_ "U_CD542_MY2021_Rx" SG_ 266 Disp_LangSel2_St_UB 1;
BA_ "U_U55X_MY2022_Rx" SG_ 266 Disp_LangSel2_St_UB 1;
BA_ "U_CD764_MY2022_Rx" SG_ 266 Disp_LangSel2_St_UB 1;
BA_ "U_CX727_MY2021_Rx" SG_ 266 Disp_LangSel_St_UB 1;
BA_ "U_P702_MY2021_Rx" SG_ 266 Disp_LangSel_St_UB 1;
BA_ "U_T6_MCA_MY2020_Rx" SG_ 266 Disp_LangSel_St_UB 1;
BA_ "U_CD542_MY2021_Rx" SG_ 266 Disp_LangSel_St_UB 1;
BA_ "U_U55X_MY2022_Rx" SG_ 266 Disp_LangSel_St_UB 1;
BA_ "U_CD764_MY2022_Rx" SG_ 266 Disp_LangSel_St_UB 1;
BA_ "U_CX727_MY2021_Rx" SG_ 266 Mc_VehLangUsrSel_St_UB 1;
BA_ "U_P702_MY2021_Rx" SG_ 266 Mc_VehLangUsrSel_St_UB 1;
BA_ "U_T6_MCA_MY2020_Rx" SG_ 266 Mc_VehLangUsrSel_St_UB 1;
BA_ "U_CD542_MY2021_Rx" SG_ 266 Mc_VehLangUsrSel_St_UB 1;
BA_ "U_U55X_MY2022_Rx" SG_ 266 Mc_VehLangUsrSel_St_UB 1;
BA_ "U_CD764_MY2022_Rx" SG_ 266 Mc_VehLangUsrSel_St_UB 1;
BA_ "GenSigSendType" SG_ 266 Mc_VehLangUsrSel_St 3;
BA_ "U_CX727_MY2021_Rx" SG_ 266 Mc_VehLangUsrSel_St 1;
BA_ "U_P702_MY2021_Rx" SG_ 266 Mc_VehLangUsrSel_St 1;
BA_ "U_T6_MCA_MY2020_Rx" SG_ 266 Mc_VehLangUsrSel_St 1;
BA_ "U_CD542_MY2021_Rx" SG_ 266 Mc_VehLangUsrSel_St 1;
BA_ "U_U55X_MY2022_Rx" SG_ 266 Mc_VehLangUsrSel_St 1;
BA_ "U_CD764_MY2022_Rx" SG_ 266 Mc_VehLangUsrSel_St 1;
BA_ "U_CX727_MY2021_Rx" SG_ 266 HMI_HMIMode_St_UB 1;
BA_ "U_P702_MY2021_Rx" SG_ 266 HMI_HMIMode_St_UB 1;
BA_ "U_T6_MCA_MY2020_Rx" SG_ 266 HMI_HMIMode_St_UB 1;
BA_ "U_CD542_MY2021_Rx" SG_ 266 HMI_HMIMode_St_UB 1;
BA_ "U_U55X_MY2022_Rx" SG_ 266 HMI_HMIMode_St_UB 1;
BA_ "U_CD764_MY2022_Rx" SG_ 266 HMI_HMIMode_St_UB 1;
BA_ "WakeupSignal" SG_ 266 HMI_HMIMode_St 1;
BA_ "GenSigSendType" SG_ 266 HMI_HMIMode_St 3;
BA_ "U_CX727_MY2021_Rx" SG_ 266 HMI_HMIMode_St 1;
BA_ "U_P702_MY2021_Rx" SG_ 266 HMI_HMIMode_St 1;
BA_ "U_T6_MCA_MY2020_Rx" SG_ 266 HMI_HMIMode_St 1;
BA_ "U_CD542_MY2021_Rx" SG_ 266 HMI_HMIMode_St 1;
BA_ "U_U55X_MY2022_Rx" SG_ 266 HMI_HMIMode_St 1;
BA_ "U_CD764_MY2022_Rx" SG_ 266 HMI_HMIMode_St 1;
BA_ "GenSigSendType" SG_ 266 Disp_LangSel_St 3;
BA_ "U_CX727_MY2021_Rx" SG_ 266 Disp_LangSel_St 1;
BA_ "U_P702_MY2021_Rx" SG_ 266 Disp_LangSel_St 1;
BA_ "U_T6_MCA_MY2020_Rx" SG_ 266 Disp_LangSel_St 1;
BA_ "U_CD542_MY2021_Rx" SG_ 266 Disp_LangSel_St 1;
BA_ "U_U55X_MY2022_Rx" SG_ 266 Disp_LangSel_St 1;
BA_ "U_CD764_MY2022_Rx" SG_ 266 Disp_LangSel_St 1;
BA_ "GenSigSendType" SG_ 266 Disp_LangSel2_St 3;
BA_ "U_CX727_MY2021_Rx" SG_ 266 Disp_LangSel2_St 1;
BA_ "U_P702_MY2021_Rx" SG_ 266 Disp_LangSel2_St 1;
BA_ "U_T6_MCA_MY2020_Rx" SG_ 266 Disp_LangSel2_St 1;
BA_ "U_CD542_MY2021_Rx" SG_ 266 Disp_LangSel2_St 1;
BA_ "U_U55X_MY2022_Rx" SG_ 266 Disp_LangSel2_St 1;
BA_ "U_CD764_MY2022_Rx" SG_ 266 Disp_LangSel2_St 1;
BA_ "GenSigStartValueInteger" SG_ 263 SteeringColumnTorque 254;
BA_ "GenSigStartValue" SG_ 263 SteeringColumnTorque 254;
BA_ "U_U55X_MY2022_Rx" SG_ 263 SteeringColumnTorque 1;
BA_ "U_U55X_MY2022_Rx" SG_ 263 SAPPAngleControlStat2 1;
BA_ "U_U55X_MY2022_Rx" SG_ 263 SAPPAngleControlStat1 1;
BA_ "U_U55X_MY2022_Rx" SG_ 263 SteeringColumnTorque_UB 1;
BA_ "U_U55X_MY2022_Rx" SG_ 263 SAPPAngleControlStat2_UB 1;
BA_ "U_U55X_MY2022_Rx" SG_ 263 SAPPAngleControlStat1_UB 1;
BA_ "U_U55X_MY2022_Rx" SG_ 263 ApedPos_Pc_ActlArb_UB 1;
BA_ "U_U55X_MY2022_Rx" SG_ 263 ApedPos_Pc_ActlArb 1;
BA_ "U_CX727_MY2021_Rx" SG_ 263 Veh_V_ActlEng 1;
BA_ "U_P702_MY2021_Rx" SG_ 263 Veh_V_ActlEng 1;
BA_ "U_T6_MCA_MY2020_Rx" SG_ 263 Veh_V_ActlEng 1;
BA_ "U_CD542_MY2021_Rx" SG_ 263 Veh_V_ActlEng 1;
BA_ "U_U55X_MY2022_Rx" SG_ 263 Veh_V_ActlEng 1;
BA_ "U_CD764_MY2022_Rx" SG_ 263 Veh_V_ActlEng 1;
BA_ "U_CX727_MY2021_Rx" SG_ 263 WhlDirFl_D_Actl_UB 1;
BA_ "U_P702_MY2021_Rx" SG_ 263 WhlDirFl_D_Actl_UB 1;
BA_ "U_T6_MCA_MY2020_Rx" SG_ 263 WhlDirFl_D_Actl_UB 1;
BA_ "U_CD542_MY2021_Rx" SG_ 263 WhlDirFl_D_Actl_UB 1;
BA_ "U_CD764_MY2022_Rx" SG_ 263 WhlDirFl_D_Actl_UB 1;
BA_ "U_CX727_MY2021_Rx" SG_ 263 Veh_V_ActlEng_UB 1;
BA_ "U_CD542_MY2021_Rx" SG_ 263 Veh_V_ActlEng_UB 1;
BA_ "U_U55X_MY2022_Rx" SG_ 263 Veh_V_ActlEng_UB 1;
BA_ "U_CD764_MY2022_Rx" SG_ 263 Veh_V_ActlEng_UB 1;
BA_ "U_P702_MY2021_Rx" SG_ 263 Veh_V_ActlEng_UB 1;
BA_ "U_T6_MCA_MY2020_Rx" SG_ 263 Veh_V_ActlEng_UB 1;
BA_ "U_CX727_MY2021_Rx" SG_ 263 WhlDirFl_D_Actl 1;
BA_ "U_P702_MY2021_Rx" SG_ 263 WhlDirFl_D_Actl 1;
BA_ "U_T6_MCA_MY2020_Rx" SG_ 263 WhlDirFl_D_Actl 1;
BA_ "U_CD542_MY2021_Rx" SG_ 263 WhlDirFl_D_Actl 1;
BA_ "U_CD764_MY2022_Rx" SG_ 263 WhlDirFl_D_Actl 1;
BA_ "U_CX727_MY2021_Rx" SG_ 261 RstrnImpactEvntStatus_UB 1;
BA_ "U_P702_MY2021_Rx" SG_ 261 RstrnImpactEvntStatus_UB 1;
BA_ "U_T6_MCA_MY2020_Rx" SG_ 261 RstrnImpactEvntStatus_UB 1;
BA_ "U_CD542_MY2021_Rx" SG_ 261 RstrnImpactEvntStatus_UB 1;
BA_ "U_CD764_MY2022_Rx" SG_ 261 RstrnImpactEvntStatus_UB 1;
BA_ "WakeupSignal" SG_ 261 RstrnImpactEvntStatus 1;
BA_ "GenSigSendType" SG_ 261 RstrnImpactEvntStatus 3;
BA_ "U_CX727_MY2021_Rx" SG_ 261 RstrnImpactEvntStatus 1;
BA_ "U_P702_MY2021_Rx" SG_ 261 RstrnImpactEvntStatus 1;
BA_ "U_T6_MCA_MY2020_Rx" SG_ 261 RstrnImpactEvntStatus 1;
BA_ "U_CD542_MY2021_Rx" SG_ 261 RstrnImpactEvntStatus 1;
BA_ "U_CD764_MY2022_Rx" SG_ 261 RstrnImpactEvntStatus 1;
BA_ "GenSigSendType" SG_ 264 MirrorTelescopic_D_Rq 3;
BA_ "U_U55X_MY2022_Rx" SG_ 264 MirrorTelescopic_D_Rq 1;
BA_ "U_U55X_MY2022_Rx" SG_ 264 MirrorTelescopic_D_Rq_UB 1;
BA_ "U_CX727_MY2021_Rx" SG_ 264 Veh_Lock_Requestor_UB 1;
BA_ "U_CD542_MY2021_Rx" SG_ 264 Veh_Lock_Requestor_UB 1;
BA_ "U_U55X_MY2022_Rx" SG_ 264 Veh_Lock_Requestor_UB 1;
BA_ "U_CD764_MY2022_Rx" SG_ 264 Veh_Lock_Requestor_UB 1;
BA_ "WakeupSignal" SG_ 264 Veh_Lock_Requestor 1;
BA_ "GenSigSendType" SG_ 264 Veh_Lock_Requestor 3;
BA_ "U_CX727_MY2021_Rx" SG_ 264 Veh_Lock_Requestor 1;
BA_ "U_CD542_MY2021_Rx" SG_ 264 Veh_Lock_Requestor 1;
BA_ "U_U55X_MY2022_Rx" SG_ 264 Veh_Lock_Requestor 1;
BA_ "U_CD764_MY2022_Rx" SG_ 264 Veh_Lock_Requestor 1;
BA_ "U_CX727_MY2021_Rx" SG_ 264 Veh_Lock_EvNum_UB 1;
BA_ "U_CD542_MY2021_Rx" SG_ 264 Veh_Lock_EvNum_UB 1;
BA_ "U_U55X_MY2022_Rx" SG_ 264 Veh_Lock_EvNum_UB 1;
BA_ "U_CD764_MY2022_Rx" SG_ 264 Veh_Lock_EvNum_UB 1;
BA_ "WakeupSignal" SG_ 264 Veh_Lock_EvNum 1;
BA_ "U_CX727_MY2021_Rx" SG_ 264 Veh_Lock_EvNum 1;
BA_ "U_CD542_MY2021_Rx" SG_ 264 Veh_Lock_EvNum 1;
BA_ "U_U55X_MY2022_Rx" SG_ 264 Veh_Lock_EvNum 1;
BA_ "U_CD764_MY2022_Rx" SG_ 264 Veh_Lock_EvNum 1;
BA_ "U_U55X_MY2022_Rx" SG_ 264 PrkBrkStatus_UB 1;
BA_ "GenSigStartValueInteger" SG_ 264 PrkBrkStatus 7;
BA_ "GenSigStartValue" SG_ 264 PrkBrkStatus 7;
BA_ "GenSigSendType" SG_ 264 PrkBrkStatus 3;
BA_ "U_U55X_MY2022_Rx" SG_ 264 PrkBrkStatus 1;
BA_ "U_CX727_MY2021_Rx" SG_ 257 PwSrcULoFalt_D_Stat_UB 1;
BA_ "U_P702_MY2021_Rx" SG_ 257 PwSrcULoFalt_D_Stat_UB 1;
BA_ "U_T6_MCA_MY2020_Rx" SG_ 257 PwSrcULoFalt_D_Stat_UB 1;
BA_ "U_CD542_MY2021_Rx" SG_ 257 PwSrcULoFalt_D_Stat_UB 1;
BA_ "U_U55X_MY2022_Rx" SG_ 257 PwSrcULoFalt_D_Stat_UB 1;
BA_ "U_CD764_MY2022_Rx" SG_ 257 PwSrcULoFalt_D_Stat_UB 1;
BA_ "GenSigSendType" SG_ 257 PwSrcULoFalt_D_Stat 3;
BA_ "U_CX727_MY2021_Rx" SG_ 257 PwSrcULoFalt_D_Stat 1;
BA_ "U_P702_MY2021_Rx" SG_ 257 PwSrcULoFalt_D_Stat 1;
BA_ "U_T6_MCA_MY2020_Rx" SG_ 257 PwSrcULoFalt_D_Stat 1;
BA_ "U_CD542_MY2021_Rx" SG_ 257 PwSrcULoFalt_D_Stat 1;
BA_ "U_U55X_MY2022_Rx" SG_ 257 PwSrcULoFalt_D_Stat 1;
BA_ "U_CD764_MY2022_Rx" SG_ 257 PwSrcULoFalt_D_Stat 1;
BA_ "U_CX727_MY2021_Rx" SG_ 257 GearRvrse_D_Actl_UB 1;
BA_ "U_P702_MY2021_Rx" SG_ 257 GearRvrse_D_Actl_UB 1;
BA_ "U_T6_MCA_MY2020_Rx" SG_ 257 GearRvrse_D_Actl_UB 1;
BA_ "U_CD542_MY2021_Rx" SG_ 257 GearRvrse_D_Actl_UB 1;
BA_ "U_U55X_MY2022_Rx" SG_ 257 GearRvrse_D_Actl_UB 1;
BA_ "U_CD764_MY2022_Rx" SG_ 257 GearRvrse_D_Actl_UB 1;
BA_ "GenSigStartValueInteger" SG_ 257 GearRvrse_D_Actl 7;
BA_ "GenSigStartValue" SG_ 257 GearRvrse_D_Actl 7;
BA_ "GenSigSendType" SG_ 257 GearRvrse_D_Actl 3;
BA_ "U_CX727_MY2021_Rx" SG_ 257 GearRvrse_D_Actl 1;
BA_ "U_P702_MY2021_Rx" SG_ 257 GearRvrse_D_Actl 1;
BA_ "U_T6_MCA_MY2020_Rx" SG_ 257 GearRvrse_D_Actl 1;
BA_ "U_CD542_MY2021_Rx" SG_ 257 GearRvrse_D_Actl 1;
BA_ "U_U55X_MY2022_Rx" SG_ 257 GearRvrse_D_Actl 1;
BA_ "U_CD764_MY2022_Rx" SG_ 257 GearRvrse_D_Actl 1;
BA_ "U_CX727_MY2021_Rx" SG_ 257 GearLvrPos_D_Actl_UB 1;
BA_ "U_CD542_MY2021_Rx" SG_ 257 GearLvrPos_D_Actl_UB 1;
BA_ "U_U55X_MY2022_Rx" SG_ 257 GearLvrPos_D_Actl_UB 1;
BA_ "U_CD764_MY2022_Rx" SG_ 257 GearLvrPos_D_Actl_UB 1;
BA_ "GenSigStartValueInteger" SG_ 257 GearLvrPos_D_Actl 14;
BA_ "GenSigStartValue" SG_ 257 GearLvrPos_D_Actl 14;
BA_ "GenSigSendType" SG_ 257 GearLvrPos_D_Actl 3;
BA_ "U_CX727_MY2021_Rx" SG_ 257 GearLvrPos_D_Actl 1;
BA_ "U_CD542_MY2021_Rx" SG_ 257 GearLvrPos_D_Actl 1;
BA_ "U_U55X_MY2022_Rx" SG_ 257 GearLvrPos_D_Actl 1;
BA_ "U_CD764_MY2022_Rx" SG_ 257 GearLvrPos_D_Actl 1;
BA_ "U_CX727_MY2021_Rx" SG_ 256 Batt_Lo_SoC_B_UB 1;
BA_ "U_CD542_MY2021_Rx" SG_ 256 Batt_Lo_SoC_B_UB 1;
BA_ "U_U55X_MY2022_Rx" SG_ 256 Batt_Lo_SoC_B_UB 1;
BA_ "U_CD764_MY2022_Rx" SG_ 256 Batt_Lo_SoC_B_UB 1;
BA_ "GenSigSendType" SG_ 256 Batt_Lo_SoC_B 3;
BA_ "U_CX727_MY2021_Rx" SG_ 256 Batt_Lo_SoC_B 1;
BA_ "U_CD542_MY2021_Rx" SG_ 256 Batt_Lo_SoC_B 1;
BA_ "U_U55X_MY2022_Rx" SG_ 256 Batt_Lo_SoC_B 1;
BA_ "U_CD764_MY2022_Rx" SG_ 256 Batt_Lo_SoC_B 1;
BA_ "U_CX727_MY2021_Rx" SG_ 256 Veh_Lock_Status_UB 1;
BA_ "U_CD542_MY2021_Rx" SG_ 256 Veh_Lock_Status_UB 1;
BA_ "U_U55X_MY2022_Rx" SG_ 256 Veh_Lock_Status_UB 1;
BA_ "U_CD764_MY2022_Rx" SG_ 256 Veh_Lock_Status_UB 1;
BA_ "WakeupSignal" SG_ 256 Veh_Lock_Status 1;
BA_ "GenSigStartValueInteger" SG_ 256 Veh_Lock_Status 1;
BA_ "GenSigStartValue" SG_ 256 Veh_Lock_Status 1;
BA_ "GenSigSendType" SG_ 256 Veh_Lock_Status 3;
BA_ "U_CX727_MY2021_Rx" SG_ 256 Veh_Lock_Status 1;
BA_ "U_CD542_MY2021_Rx" SG_ 256 Veh_Lock_Status 1;
BA_ "U_U55X_MY2022_Rx" SG_ 256 Veh_Lock_Status 1;
BA_ "U_CD764_MY2022_Rx" SG_ 256 Veh_Lock_Status 1;
BA_ "U_CX727_MY2021_Rx" SG_ 256 BSBattSOC_UB 1;
BA_ "U_CD542_MY2021_Rx" SG_ 256 BSBattSOC_UB 1;
BA_ "U_U55X_MY2022_Rx" SG_ 256 BSBattSOC_UB 1;
BA_ "U_CD764_MY2022_Rx" SG_ 256 BSBattSOC_UB 1;
BA_ "U_CX727_MY2021_Rx" SG_ 256 BSBattSOC 1;
BA_ "U_CD542_MY2021_Rx" SG_ 256 BSBattSOC 1;
BA_ "U_U55X_MY2022_Rx" SG_ 256 BSBattSOC 1;
BA_ "U_CD764_MY2022_Rx" SG_ 256 BSBattSOC 1;
BA_ "GenSigSendType" SG_ 638 EmgcyCallHmi_D_Stat 3;
BA_ "U_CX727_MY2021_Tx" SG_ 638 EmgcyCallHmi_D_Stat 1;
BA_ "U_P702_MY2021_Tx" SG_ 638 EmgcyCallHmi_D_Stat 1;
BA_ "U_T6_MCA_MY2020_Tx" SG_ 638 EmgcyCallHmi_D_Stat 1;
BA_ "U_CD542_MY2021_Tx" SG_ 638 EmgcyCallHmi_D_Stat 1;
BA_ "U_CD764_MY2022_Tx" SG_ 638 EmgcyCallHmi_D_Stat 1;
BA_ "GenSigSendType" SG_ 638 EmgcyCallFalt_B_Dsply 3;
BA_ "U_CX727_MY2021_Tx" SG_ 638 EmgcyCallFalt_B_Dsply 1;
BA_ "U_P702_MY2021_Tx" SG_ 638 EmgcyCallFalt_B_Dsply 1;
BA_ "U_T6_MCA_MY2020_Tx" SG_ 638 EmgcyCallFalt_B_Dsply 1;
BA_ "U_CD542_MY2021_Tx" SG_ 638 EmgcyCallFalt_B_Dsply 1;
BA_ "U_CD764_MY2022_Tx" SG_ 638 EmgcyCallFalt_B_Dsply 1;
BA_ "U_CX727_MY2021_Tx" SG_ 638 EmgcyCallCancl_T_Actl 1;
BA_ "U_P702_MY2021_Tx" SG_ 638 EmgcyCallCancl_T_Actl 1;
BA_ "U_T6_MCA_MY2020_Tx" SG_ 638 EmgcyCallCancl_T_Actl 1;
BA_ "U_CD542_MY2021_Tx" SG_ 638 EmgcyCallCancl_T_Actl 1;
BA_ "U_CD764_MY2022_Tx" SG_ 638 EmgcyCallCancl_T_Actl 1;
BA_ "GenSigSendType" SG_ 638 EmgcyCall_D_Stat 3;
BA_ "U_CX727_MY2021_Tx" SG_ 638 EmgcyCall_D_Stat 1;
BA_ "U_P702_MY2021_Tx" SG_ 638 EmgcyCall_D_Stat 1;
BA_ "U_T6_MCA_MY2020_Tx" SG_ 638 EmgcyCall_D_Stat 1;
BA_ "U_CD542_MY2021_Tx" SG_ 638 EmgcyCall_D_Stat 1;
BA_ "U_CD764_MY2022_Tx" SG_ 638 EmgcyCall_D_Stat 1;
BA_ "U_T6_MCA_MY2020_Rx" SG_ 75 VedsPasKneeBag_D_Ltchd 1;
BA_ "U_CD764_MY2022_Rx" SG_ 75 VedsPasKneeBag_D_Ltchd 1;
BA_ "U_T6_MCA_MY2020_Rx" SG_ 75 VedsRw3pRib_D_Ltchd 1;
BA_ "U_CD764_MY2022_Rx" SG_ 75 VedsRw3pRib_D_Ltchd 1;
BA_ "U_T6_MCA_MY2020_Rx" SG_ 75 VedsRw3dRib_D_Ltchd 1;
BA_ "U_CD764_MY2022_Rx" SG_ 75 VedsRw3dRib_D_Ltchd 1;
BA_ "U_T6_MCA_MY2020_Rx" SG_ 75 VedsRw1mBckl_D_Ltchd 1;
BA_ "U_CD764_MY2022_Rx" SG_ 75 VedsRw1mBckl_D_Ltchd 1;
BA_ "U_T6_MCA_MY2020_Rx" SG_ 75 VedsRw1mBelt_D_Ltchd 1;
BA_ "U_CD764_MY2022_Rx" SG_ 75 VedsRw1mBelt_D_Ltchd 1;
BA_ "U_T6_MCA_MY2020_Rx" SG_ 75 VedsRw2pRib_D_Ltchd 1;
BA_ "U_CD764_MY2022_Rx" SG_ 75 VedsRw2pRib_D_Ltchd 1;
BA_ "U_T6_MCA_MY2020_Rx" SG_ 75 VedsRw2dRib_D_Ltchd 1;
BA_ "U_CD764_MY2022_Rx" SG_ 75 VedsRw2dRib_D_Ltchd 1;
BA_ "U_T6_MCA_MY2020_Rx" SG_ 75 VedsRw3pBckl_D_Ltchd 1;
BA_ "U_CD764_MY2022_Rx" SG_ 75 VedsRw3pBckl_D_Ltchd 1;
BA_ "U_T6_MCA_MY2020_Rx" SG_ 75 VedsRw3mBckl_D_Ltchd 1;
BA_ "U_CD764_MY2022_Rx" SG_ 75 VedsRw3mBckl_D_Ltchd 1;
BA_ "U_T6_MCA_MY2020_Rx" SG_ 75 VedsRw3dBckl_D_Ltchd 1;
BA_ "U_CD764_MY2022_Rx" SG_ 75 VedsRw3dBckl_D_Ltchd 1;
BA_ "U_T6_MCA_MY2020_Rx" SG_ 75 VedsRw2pBckl_D_Ltchd 1;
BA_ "U_CD764_MY2022_Rx" SG_ 75 VedsRw2pBckl_D_Ltchd 1;
BA_ "U_T6_MCA_MY2020_Rx" SG_ 75 VedsRw2mBckl_D_Ltchd 1;
BA_ "U_CD764_MY2022_Rx" SG_ 75 VedsRw2mBckl_D_Ltchd 1;
BA_ "U_T6_MCA_MY2020_Rx" SG_ 75 VedsRw2dBckl_D_Ltchd 1;
BA_ "U_CD764_MY2022_Rx" SG_ 75 VedsRw2dBckl_D_Ltchd 1;
BA_ "U_T6_MCA_MY2020_Rx" SG_ 75 VedsRw1PasChld_D_Ltchd 1;
BA_ "U_CD764_MY2022_Rx" SG_ 75 VedsRw1PasChld_D_Ltchd 1;
BA_ "U_T6_MCA_MY2020_Rx" SG_ 75 VedsRw1PasBckl_D_Ltchd 1;
BA_ "U_CD764_MY2022_Rx" SG_ 75 VedsRw1PasBckl_D_Ltchd 1;
BA_ "U_T6_MCA_MY2020_Rx" SG_ 75 VedsRw1DrvBckl_D_Ltchd 1;
BA_ "U_CD764_MY2022_Rx" SG_ 75 VedsRw1DrvBckl_D_Ltchd 1;
BA_ "U_CX727_MY2021_Tx" SG_ 1184 APIM_TCU_Word_Rx 1;
BA_ "U_P702_MY2021_Tx" SG_ 1184 APIM_TCU_Word_Rx 1;
BA_ "U_T6_MCA_MY2020_Tx" SG_ 1184 APIM_TCU_Word_Rx 1;
BA_ "U_CD542_MY2021_Tx" SG_ 1184 APIM_TCU_Word_Rx 1;
BA_ "U_U55X_MY2022_Tx" SG_ 1184 APIM_TCU_Word_Rx 1;
BA_ "U_CD764_MY2022_Tx" SG_ 1184 APIM_TCU_Word_Rx 1;
BA_ "U_T6_MCA_MY2020_Rx" SG_ 74 VedsPasSideBag_D_Ltchd 1;
BA_ "U_CD764_MY2022_Rx" SG_ 74 VedsPasSideBag_D_Ltchd 1;
BA_ "U_T6_MCA_MY2020_Rx" SG_ 74 VedsPasCrtnBag_D_Ltchd 1;
BA_ "U_CD764_MY2022_Rx" SG_ 74 VedsPasCrtnBag_D_Ltchd 1;
BA_ "U_T6_MCA_MY2020_Rx" SG_ 74 VedsPasBelt_D_Ltchd 1;
BA_ "U_CD764_MY2022_Rx" SG_ 74 VedsPasBelt_D_Ltchd 1;
BA_ "U_T6_MCA_MY2020_Rx" SG_ 74 VedsPasBag_D_Ltchd 1;
BA_ "U_CD764_MY2022_Rx" SG_ 74 VedsPasBag_D_Ltchd 1;
BA_ "U_T6_MCA_MY2020_Rx" SG_ 74 VedsMultiEvnt_D_Ltchd 1;
BA_ "U_CD764_MY2022_Rx" SG_ 74 VedsMultiEvnt_D_Ltchd 1;
BA_ "U_T6_MCA_MY2020_Rx" SG_ 74 VedsMaxDeltaV_D_Ltchd 1;
BA_ "U_CD764_MY2022_Rx" SG_ 74 VedsMaxDeltaV_D_Ltchd 1;
BA_ "U_T6_MCA_MY2020_Rx" SG_ 74 VedsDrvKneeBag_D_Ltchd 1;
BA_ "U_CD764_MY2022_Rx" SG_ 74 VedsDrvKneeBag_D_Ltchd 1;
BA_ "U_T6_MCA_MY2020_Rx" SG_ 74 VedsEvntType_D_Ltchd 1;
BA_ "U_CD764_MY2022_Rx" SG_ 74 VedsEvntType_D_Ltchd 1;
BA_ "U_T6_MCA_MY2020_Rx" SG_ 74 VedsEvntRoll_D_Ltchd 1;
BA_ "U_CD764_MY2022_Rx" SG_ 74 VedsEvntRoll_D_Ltchd 1;
BA_ "U_T6_MCA_MY2020_Rx" SG_ 74 VedsDrvSideBag_D_Ltchd 1;
BA_ "U_CD764_MY2022_Rx" SG_ 74 VedsDrvSideBag_D_Ltchd 1;
BA_ "U_T6_MCA_MY2020_Rx" SG_ 74 VedsDrvCrtnBag_D_Ltchd 1;
BA_ "U_CD764_MY2022_Rx" SG_ 74 VedsDrvCrtnBag_D_Ltchd 1;
BA_ "U_T6_MCA_MY2020_Rx" SG_ 74 VedsDrvBelt_D_Ltchd 1;
BA_ "U_CD764_MY2022_Rx" SG_ 74 VedsDrvBelt_D_Ltchd 1;
BA_ "U_T6_MCA_MY2020_Rx" SG_ 74 VedsDrvBag_D_Ltchd 1;
BA_ "U_CD764_MY2022_Rx" SG_ 74 VedsDrvBag_D_Ltchd 1;
BA_ "GenSigStartValueInteger" SG_ 74 eCallNotification 1;
BA_ "GenSigStartValue" SG_ 74 eCallNotification 1;
BA_ "U_T6_MCA_MY2020_Rx" SG_ 74 eCallNotification 1;
BA_ "U_CD764_MY2022_Rx" SG_ 74 eCallNotification 1;
BA_ "GenSigSendType" SG_ 2611175500 PARSEDPhysRFAtoGWM_ECG 3;
BA_ "ECGUsedRxSignal" SG_ 2611175500 PARSEDPhysRFAtoGWM_ECG 1;
BA_ "U_CD764_MY2022_Rx" SG_ 2611175500 PARSEDPhysRFAtoGWM_ECG 1;
BA_ "U_CD764_MY2022_Tx" SG_ 2611175500 PARSEDPhysRFAtoGWM_ECG 1;
BA_ "GenSigSendType" SG_ 2609983704 OTAPhysGWM_ECGtoRFA 3;
BA_ "U_CD764_MY2022_Rx" SG_ 2609983704 OTAPhysGWM_ECGtoRFA 1;
BA_ "ECGUsedTxSignal" SG_ 2609983704 OTAPhysGWM_ECGtoRFA 1;
BA_ "U_CD764_MY2022_Tx" SG_ 2609983704 OTAPhysGWM_ECGtoRFA 1;
BA_ "GenSigSendType" SG_ 2612002008 PARSEDFuncGWM_ECG 3;
BA_ "U_CD764_MY2022_Rx" SG_ 2612002008 PARSEDFuncGWM_ECG 1;
BA_ "U_T6_MCA_MY2020_Tx" SG_ 2612002008 PARSEDFuncGWM_ECG 1;
BA_ "ECGUsedTxSignal" SG_ 2612002008 PARSEDFuncGWM_ECG 1;
BA_ "U_CD542_MY2021_Tx" SG_ 2612002008 PARSEDFuncGWM_ECG 1;
BA_ "U_U55X_MY2022_Tx" SG_ 2612002008 PARSEDFuncGWM_ECG 1;
BA_ "U_CD764_MY2022_Tx" SG_ 2612002008 PARSEDFuncGWM_ECG 1;
BA_ "GenSigSendType" SG_ 2610953432 OTAFuncGWM_ECG 3;
BA_ "U_CD764_MY2022_Rx" SG_ 2610953432 OTAFuncGWM_ECG 1;
BA_ "U_T6_MCA_MY2020_Tx" SG_ 2610953432 OTAFuncGWM_ECG 1;
BA_ "ECGUsedTxSignal" SG_ 2610953432 OTAFuncGWM_ECG 1;
BA_ "U_CD542_MY2021_Tx" SG_ 2610953432 OTAFuncGWM_ECG 1;
BA_ "U_U55X_MY2022_Tx" SG_ 2610953432 OTAFuncGWM_ECG 1;
BA_ "U_CD764_MY2022_Tx" SG_ 2610953432 OTAFuncGWM_ECG 1;
BA_ "GenSigStartValueInteger" SG_ 625 ModemAuthrz_D_Stat2 3;
BA_ "GenSigStartValue" SG_ 625 ModemAuthrz_D_Stat2 3;
BA_ "GenSigSendType" SG_ 625 ModemAuthrz_D_Stat2 3;
BA_ "U_CX727_MY2021_Rx" SG_ 625 ModemAuthrz_D_Stat2 1;
BA_ "U_U55X_MY2022_Rx" SG_ 625 ModemAuthrz_D_Stat2 1;
BA_ "ECGUsedTxSignal" SG_ 625 ModemAuthrz_D_Stat2 1;
BA_ "U_CD542_MY2021_Tx" SG_ 625 ModemAuthrz_D_Stat2 1;
BA_ "U_CD764_MY2022_Tx" SG_ 625 ModemAuthrz_D_Stat2 1;
BA_ "U_CX727_MY2021_Rx" SG_ 625 PaakSerial_D2_Rq2 1;
BA_ "U_U55X_MY2022_Rx" SG_ 625 PaakSerial_D2_Rq2 1;
BA_ "ECGUsedTxSignal" SG_ 625 PaakSerial_D2_Rq2 1;
BA_ "U_CD542_MY2021_Tx" SG_ 625 PaakSerial_D2_Rq2 1;
BA_ "U_CD764_MY2022_Tx" SG_ 625 PaakSerial_D2_Rq2 1;
BA_ "ECGUsedRxSignal" SG_ 694 RFA_BLEM_ECG_Word_Tx 1;
BA_ "U_CD542_MY2021_Rx" SG_ 694 RFA_BLEM_ECG_Word_Tx 1;
BA_ "U_CD764_MY2022_Rx" SG_ 694 RFA_BLEM_ECG_Word_Tx 1;
BA_ "U_CX727_MY2021_Tx" SG_ 694 RFA_BLEM_ECG_Word_Tx 1;
BA_ "U_U55X_MY2022_Tx" SG_ 694 RFA_BLEM_ECG_Word_Tx 1;
BA_ "U_CX727_MY2021_Rx" SG_ 702 ECG_RFA_BLEM_Word_Tx 1;
BA_ "U_U55X_MY2022_Rx" SG_ 702 ECG_RFA_BLEM_Word_Tx 1;
BA_ "ECGUsedTxSignal" SG_ 702 ECG_RFA_BLEM_Word_Tx 1;
BA_ "U_CD542_MY2021_Tx" SG_ 702 ECG_RFA_BLEM_Word_Tx 1;
BA_ "U_CD764_MY2022_Tx" SG_ 702 ECG_RFA_BLEM_Word_Tx 1;
BA_ "GenSigSendType" SG_ 1822 TesterPhysicalResGWM_H4 3;
BA_ "U_T6_MCA_MY2020_Tx" SG_ 1822 TesterPhysicalResGWM_H4 1;
BA_ "ECGUsedTxSignal" SG_ 1822 TesterPhysicalResGWM_H4 1;
BA_ "U_CD542_MY2021_Tx" SG_ 1822 TesterPhysicalResGWM_H4 1;
BA_ "U_U55X_MY2022_Tx" SG_ 1822 TesterPhysicalResGWM_H4 1;
BA_ "U_CD764_MY2022_Tx" SG_ 1822 TesterPhysicalResGWM_H4 1;
BA_ "WakeupSignal" SG_ 435 DimmingLvlEvnt_No_Actl 1;
BA_ "WakeupSignal" SG_ 435 TurnLghtRight_D_Rq 1;
BA_ "WakeupSignal" SG_ 435 Backlit_LED_Status 1;
BA_ "WakeupSignal" SG_ 435 TurnLghtLeft_D_Rq 1;
BA_ "GenSigStartValueInteger" SG_ 435 IgnKeyType_D_Actl 14;
BA_ "GenSigStartValue" SG_ 435 IgnKeyType_D_Actl 14;
BA_ "WakeupSignal" SG_ 435 Parklamp_Status 1;
BA_ "GenSigStartValueInteger" SG_ 435 Parklamp_Status 1;
BA_ "GenSigStartValue" SG_ 435 Parklamp_Status 1;
BA_ "U_CX727_MY2021_Rx" SG_ 435 Parklamp_Status 1;
BA_ "U_P702_MY2021_Rx" SG_ 435 Parklamp_Status 1;
BA_ "U_T6_MCA_MY2020_Rx" SG_ 435 Parklamp_Status 1;
BA_ "U_CD542_MY2021_Rx" SG_ 435 Parklamp_Status 1;
BA_ "U_CD764_MY2022_Rx" SG_ 435 Parklamp_Status 1;
BA_ "WakeupSignal" SG_ 435 Litval 1;
BA_ "WakeupSignal" SG_ 435 Key_In_Ignition_Stat 1;
BA_ "WakeupSignal" SG_ 435 Ignition_Status 1;
BA_ "U_CX727_MY2021_Rx" SG_ 435 Ignition_Status 1;
BA_ "U_P702_MY2021_Rx" SG_ 435 Ignition_Status 1;
BA_ "U_T6_MCA_MY2020_Rx" SG_ 435 Ignition_Status 1;
BA_ "U_CD542_MY2021_Rx" SG_ 435 Ignition_Status 1;
BA_ "U_U55X_MY2022_Rx" SG_ 435 Ignition_Status 1;
BA_ "U_CD764_MY2022_Rx" SG_ 435 Ignition_Status 1;
BA_ "WakeupSignal" SG_ 435 Dimming_Lvl 1;
BA_ "GenSigStartValueInteger" SG_ 435 Dimming_Lvl 12;
BA_ "GenSigStartValue" SG_ 435 Dimming_Lvl 12;
BA_ "U_CX727_MY2021_Rx" SG_ 435 Dimming_Lvl 1;
BA_ "U_P702_MY2021_Rx" SG_ 435 Dimming_Lvl 1;
BA_ "U_T6_MCA_MY2020_Rx" SG_ 435 Dimming_Lvl 1;
BA_ "U_CD542_MY2021_Rx" SG_ 435 Dimming_Lvl 1;
BA_ "U_CD764_MY2022_Rx" SG_ 435 Dimming_Lvl 1;
BA_ "WakeupSignal" SG_ 435 Day_Night_Status 1;
BA_ "U_CX727_MY2021_Rx" SG_ 435 Day_Night_Status 1;
BA_ "U_P702_MY2021_Rx" SG_ 435 Day_Night_Status 1;
BA_ "U_T6_MCA_MY2020_Rx" SG_ 435 Day_Night_Status 1;
BA_ "U_CD542_MY2021_Rx" SG_ 435 Day_Night_Status 1;
BA_ "U_CD764_MY2022_Rx" SG_ 435 Day_Night_Status 1;
BA_ "WakeupSignal" SG_ 435 Remote_Start_Status 1;
BA_ "U_CX727_MY2021_Rx" SG_ 435 Remote_Start_Status 1;
BA_ "U_CD542_MY2021_Rx" SG_ 435 Remote_Start_Status 1;
BA_ "U_U55X_MY2022_Rx" SG_ 435 Remote_Start_Status 1;
BA_ "U_CD764_MY2022_Rx" SG_ 435 Remote_Start_Status 1;
BA_ "WakeupSignal" SG_ 435 DrStatTgate_B_Actl 1;
BA_ "U_U55X_MY2022_Rx" SG_ 435 DrStatTgate_B_Actl 1;
BA_ "WakeupSignal" SG_ 435 DrStatRr_B_Actl 1;
BA_ "U_U55X_MY2022_Rx" SG_ 435 DrStatRr_B_Actl 1;
BA_ "WakeupSignal" SG_ 435 DrStatRl_B_Actl 1;
BA_ "U_U55X_MY2022_Rx" SG_ 435 DrStatRl_B_Actl 1;
BA_ "WakeupSignal" SG_ 435 DrStatPsngr_B_Actl 1;
BA_ "U_CX727_MY2021_Rx" SG_ 435 DrStatPsngr_B_Actl 1;
BA_ "U_CD542_MY2021_Rx" SG_ 435 DrStatPsngr_B_Actl 1;
BA_ "U_U55X_MY2022_Rx" SG_ 435 DrStatPsngr_B_Actl 1;
BA_ "U_CD764_MY2022_Rx" SG_ 435 DrStatPsngr_B_Actl 1;
BA_ "WakeupSignal" SG_ 435 DrStatInnrTgate_B_Actl 1;
BA_ "U_CX727_MY2021_Rx" SG_ 435 DrStatInnrTgate_B_Actl 1;
BA_ "U_CD542_MY2021_Rx" SG_ 435 DrStatInnrTgate_B_Actl 1;
BA_ "U_U55X_MY2022_Rx" SG_ 435 DrStatInnrTgate_B_Actl 1;
BA_ "U_CD764_MY2022_Rx" SG_ 435 DrStatInnrTgate_B_Actl 1;
BA_ "WakeupSignal" SG_ 435 DrStatHood_B_Actl 1;
BA_ "U_U55X_MY2022_Rx" SG_ 435 DrStatHood_B_Actl 1;
BA_ "WakeupSignal" SG_ 435 DrStatDrv_B_Actl 1;
BA_ "U_CX727_MY2021_Rx" SG_ 435 DrStatDrv_B_Actl 1;
BA_ "U_CD542_MY2021_Rx" SG_ 435 DrStatDrv_B_Actl 1;
BA_ "U_U55X_MY2022_Rx" SG_ 435 DrStatDrv_B_Actl 1;
BA_ "U_CD764_MY2022_Rx" SG_ 435 DrStatDrv_B_Actl 1;
BA_ "WakeupSignal" SG_ 435 PrkBrkActv_B_Actl 1;
BA_ "ContentDependant" SG_ 435 PrkBrkActv_B_Actl 1;
BA_ "U_CX727_MY2021_Rx" SG_ 435 LifeCycMde_D_Actl 1;
BA_ "U_P702_MY2021_Rx" SG_ 435 LifeCycMde_D_Actl 1;
BA_ "U_T6_MCA_MY2020_Rx" SG_ 435 LifeCycMde_D_Actl 1;
BA_ "U_CD542_MY2021_Rx" SG_ 435 LifeCycMde_D_Actl 1;
BA_ "U_U55X_MY2022_Rx" SG_ 435 LifeCycMde_D_Actl 1;
BA_ "U_CD764_MY2022_Rx" SG_ 435 LifeCycMde_D_Actl 1;
BA_ "WakeupSignal" SG_ 435 Delay_Accy 1;
BA_ "U_CX727_MY2021_Rx" SG_ 435 Delay_Accy 1;
BA_ "U_P702_MY2021_Rx" SG_ 435 Delay_Accy 1;
BA_ "U_T6_MCA_MY2020_Rx" SG_ 435 Delay_Accy 1;
BA_ "U_CD542_MY2021_Rx" SG_ 435 Delay_Accy 1;
BA_ "U_U55X_MY2022_Rx" SG_ 435 Delay_Accy 1;
BA_ "U_CD764_MY2022_Rx" SG_ 435 Delay_Accy 1;
BA_ "WakeupSignal" SG_ 435 CrashEvnt_D_Stat 1;
BA_ "GenSigStartValueInteger" SG_ 435 CrashEvnt_D_Stat 3;
BA_ "GenSigStartValue" SG_ 435 CrashEvnt_D_Stat 3;
BA_ "GenSigStartValueInteger" SG_ 1438 GWM_GWOnBoardTester 255;
BA_ "ContentDependant" SG_ 1438 GWM_GWOnBoardTester 1;
BA_ "GenSigStartValue" SG_ 1438 GWM_GWOnBoardTester 255;
BA_ "U_CX727_MY2021_Rx" SG_ 1438 GWM_GWOnBoardTester 1;
BA_ "U_P702_MY2021_Rx" SG_ 1438 GWM_GWOnBoardTester 1;
BA_ "U_T6_MCA_MY2020_Rx" SG_ 1438 GWM_GWOnBoardTester 1;
BA_ "U_CD542_MY2021_Rx" SG_ 1438 GWM_GWOnBoardTester 1;
BA_ "U_U55X_MY2022_Rx" SG_ 1438 GWM_GWOnBoardTester 1;
BA_ "U_CD764_MY2022_Rx" SG_ 1438 GWM_GWOnBoardTester 1;
BA_ "U_T6_MCA_MY2020_Tx" SG_ 1438 GWM_GWOnBoardTester 1;
BA_ "ECGUsedTxSignal" SG_ 1438 GWM_GWOnBoardTester 1;
BA_ "U_CD542_MY2021_Tx" SG_ 1438 GWM_GWOnBoardTester 1;
BA_ "U_U55X_MY2022_Tx" SG_ 1438 GWM_GWOnBoardTester 1;
BA_ "U_CD764_MY2022_Tx" SG_ 1438 GWM_GWOnBoardTester 1;
BA_ "GenSigStartValueInteger" SG_ 1438 GWM_GWNMProxy 255;
BA_ "ContentDependant" SG_ 1438 GWM_GWNMProxy 1;
BA_ "GenSigStartValue" SG_ 1438 GWM_GWNMProxy 255;
BA_ "U_CX727_MY2021_Rx" SG_ 1438 GWM_GWNMProxy 1;
BA_ "U_P702_MY2021_Rx" SG_ 1438 GWM_GWNMProxy 1;
BA_ "U_T6_MCA_MY2020_Rx" SG_ 1438 GWM_GWNMProxy 1;
BA_ "U_CD542_MY2021_Rx" SG_ 1438 GWM_GWNMProxy 1;
BA_ "U_U55X_MY2022_Rx" SG_ 1438 GWM_GWNMProxy 1;
BA_ "U_CD764_MY2022_Rx" SG_ 1438 GWM_GWNMProxy 1;
BA_ "U_T6_MCA_MY2020_Tx" SG_ 1438 GWM_GWNMProxy 1;
BA_ "ECGUsedTxSignal" SG_ 1438 GWM_GWNMProxy 1;
BA_ "U_CD542_MY2021_Tx" SG_ 1438 GWM_GWNMProxy 1;
BA_ "U_U55X_MY2022_Tx" SG_ 1438 GWM_GWNMProxy 1;
BA_ "U_CD764_MY2022_Tx" SG_ 1438 GWM_GWNMProxy 1;
BA_ "GenSigStartValueInteger" SG_ 1438 GWM_AutoSarNMReserved4 255;
BA_ "ContentDependant" SG_ 1438 GWM_AutoSarNMReserved4 1;
BA_ "GenSigStartValue" SG_ 1438 GWM_AutoSarNMReserved4 255;
BA_ "U_CX727_MY2021_Rx" SG_ 1438 GWM_AutoSarNMReserved4 1;
BA_ "U_P702_MY2021_Rx" SG_ 1438 GWM_AutoSarNMReserved4 1;
BA_ "U_T6_MCA_MY2020_Rx" SG_ 1438 GWM_AutoSarNMReserved4 1;
BA_ "U_CD542_MY2021_Rx" SG_ 1438 GWM_AutoSarNMReserved4 1;
BA_ "U_U55X_MY2022_Rx" SG_ 1438 GWM_AutoSarNMReserved4 1;
BA_ "U_CD764_MY2022_Rx" SG_ 1438 GWM_AutoSarNMReserved4 1;
BA_ "U_T6_MCA_MY2020_Tx" SG_ 1438 GWM_AutoSarNMReserved4 1;
BA_ "ECGUsedTxSignal" SG_ 1438 GWM_AutoSarNMReserved4 1;
BA_ "U_CD542_MY2021_Tx" SG_ 1438 GWM_AutoSarNMReserved4 1;
BA_ "U_U55X_MY2022_Tx" SG_ 1438 GWM_AutoSarNMReserved4 1;
BA_ "U_CD764_MY2022_Tx" SG_ 1438 GWM_AutoSarNMReserved4 1;
BA_ "GenSigStartValueInteger" SG_ 1438 GWM_AutoSarNMReserved3 255;
BA_ "ContentDependant" SG_ 1438 GWM_AutoSarNMReserved3 1;
BA_ "GenSigStartValue" SG_ 1438 GWM_AutoSarNMReserved3 255;
BA_ "U_CX727_MY2021_Rx" SG_ 1438 GWM_AutoSarNMReserved3 1;
BA_ "U_P702_MY2021_Rx" SG_ 1438 GWM_AutoSarNMReserved3 1;
BA_ "U_T6_MCA_MY2020_Rx" SG_ 1438 GWM_AutoSarNMReserved3 1;
BA_ "U_CD542_MY2021_Rx" SG_ 1438 GWM_AutoSarNMReserved3 1;
BA_ "U_U55X_MY2022_Rx" SG_ 1438 GWM_AutoSarNMReserved3 1;
BA_ "U_CD764_MY2022_Rx" SG_ 1438 GWM_AutoSarNMReserved3 1;
BA_ "U_T6_MCA_MY2020_Tx" SG_ 1438 GWM_AutoSarNMReserved3 1;
BA_ "ECGUsedTxSignal" SG_ 1438 GWM_AutoSarNMReserved3 1;
BA_ "U_CD542_MY2021_Tx" SG_ 1438 GWM_AutoSarNMReserved3 1;
BA_ "U_U55X_MY2022_Tx" SG_ 1438 GWM_AutoSarNMReserved3 1;
BA_ "U_CD764_MY2022_Tx" SG_ 1438 GWM_AutoSarNMReserved3 1;
BA_ "GenSigStartValueInteger" SG_ 1438 GWM_AutoSarNMReserved2 255;
BA_ "ContentDependant" SG_ 1438 GWM_AutoSarNMReserved2 1;
BA_ "GenSigStartValue" SG_ 1438 GWM_AutoSarNMReserved2 255;
BA_ "U_CX727_MY2021_Rx" SG_ 1438 GWM_AutoSarNMReserved2 1;
BA_ "U_P702_MY2021_Rx" SG_ 1438 GWM_AutoSarNMReserved2 1;
BA_ "U_T6_MCA_MY2020_Rx" SG_ 1438 GWM_AutoSarNMReserved2 1;
BA_ "U_CD542_MY2021_Rx" SG_ 1438 GWM_AutoSarNMReserved2 1;
BA_ "U_U55X_MY2022_Rx" SG_ 1438 GWM_AutoSarNMReserved2 1;
BA_ "U_CD764_MY2022_Rx" SG_ 1438 GWM_AutoSarNMReserved2 1;
BA_ "U_T6_MCA_MY2020_Tx" SG_ 1438 GWM_AutoSarNMReserved2 1;
BA_ "ECGUsedTxSignal" SG_ 1438 GWM_AutoSarNMReserved2 1;
BA_ "U_CD542_MY2021_Tx" SG_ 1438 GWM_AutoSarNMReserved2 1;
BA_ "U_U55X_MY2022_Tx" SG_ 1438 GWM_AutoSarNMReserved2 1;
BA_ "U_CD764_MY2022_Tx" SG_ 1438 GWM_AutoSarNMReserved2 1;
BA_ "GenSigStartValueInteger" SG_ 1438 GWM_AutoSarNMReserved1 255;
BA_ "ContentDependant" SG_ 1438 GWM_AutoSarNMReserved1 1;
BA_ "GenSigStartValue" SG_ 1438 GWM_AutoSarNMReserved1 255;
BA_ "U_CX727_MY2021_Rx" SG_ 1438 GWM_AutoSarNMReserved1 1;
BA_ "U_P702_MY2021_Rx" SG_ 1438 GWM_AutoSarNMReserved1 1;
BA_ "U_T6_MCA_MY2020_Rx" SG_ 1438 GWM_AutoSarNMReserved1 1;
BA_ "U_CD542_MY2021_Rx" SG_ 1438 GWM_AutoSarNMReserved1 1;
BA_ "U_U55X_MY2022_Rx" SG_ 1438 GWM_AutoSarNMReserved1 1;
BA_ "U_CD764_MY2022_Rx" SG_ 1438 GWM_AutoSarNMReserved1 1;
BA_ "U_T6_MCA_MY2020_Tx" SG_ 1438 GWM_AutoSarNMReserved1 1;
BA_ "ECGUsedTxSignal" SG_ 1438 GWM_AutoSarNMReserved1 1;
BA_ "U_CD542_MY2021_Tx" SG_ 1438 GWM_AutoSarNMReserved1 1;
BA_ "U_U55X_MY2022_Tx" SG_ 1438 GWM_AutoSarNMReserved1 1;
BA_ "U_CD764_MY2022_Tx" SG_ 1438 GWM_AutoSarNMReserved1 1;
BA_ "GenSigStartValueInteger" SG_ 1438 GWM_AutoSarNMNodeId 158;
BA_ "ContentDependant" SG_ 1438 GWM_AutoSarNMNodeId 1;
BA_ "GenSigStartValue" SG_ 1438 GWM_AutoSarNMNodeId 158;
BA_ "U_CX727_MY2021_Rx" SG_ 1438 GWM_AutoSarNMNodeId 1;
BA_ "U_P702_MY2021_Rx" SG_ 1438 GWM_AutoSarNMNodeId 1;
BA_ "U_T6_MCA_MY2020_Rx" SG_ 1438 GWM_AutoSarNMNodeId 1;
BA_ "U_CD542_MY2021_Rx" SG_ 1438 GWM_AutoSarNMNodeId 1;
BA_ "U_U55X_MY2022_Rx" SG_ 1438 GWM_AutoSarNMNodeId 1;
BA_ "U_CD764_MY2022_Rx" SG_ 1438 GWM_AutoSarNMNodeId 1;
BA_ "U_T6_MCA_MY2020_Tx" SG_ 1438 GWM_AutoSarNMNodeId 1;
BA_ "ECGUsedTxSignal" SG_ 1438 GWM_AutoSarNMNodeId 1;
BA_ "U_CD542_MY2021_Tx" SG_ 1438 GWM_AutoSarNMNodeId 1;
BA_ "U_U55X_MY2022_Tx" SG_ 1438 GWM_AutoSarNMNodeId 1;
BA_ "U_CD764_MY2022_Tx" SG_ 1438 GWM_AutoSarNMNodeId 1;
BA_ "ContentDependant" SG_ 1438 GWM_AutoSarNMControl 1;
BA_ "U_CX727_MY2021_Rx" SG_ 1438 GWM_AutoSarNMControl 1;
BA_ "U_P702_MY2021_Rx" SG_ 1438 GWM_AutoSarNMControl 1;
BA_ "U_T6_MCA_MY2020_Rx" SG_ 1438 GWM_AutoSarNMControl 1;
BA_ "U_CD542_MY2021_Rx" SG_ 1438 GWM_AutoSarNMControl 1;
BA_ "U_U55X_MY2022_Rx" SG_ 1438 GWM_AutoSarNMControl 1;
BA_ "U_CD764_MY2022_Rx" SG_ 1438 GWM_AutoSarNMControl 1;
BA_ "U_T6_MCA_MY2020_Tx" SG_ 1438 GWM_AutoSarNMControl 1;
BA_ "ECGUsedTxSignal" SG_ 1438 GWM_AutoSarNMControl 1;
BA_ "U_CD542_MY2021_Tx" SG_ 1438 GWM_AutoSarNMControl 1;
BA_ "U_U55X_MY2022_Tx" SG_ 1438 GWM_AutoSarNMControl 1;
BA_ "U_CD764_MY2022_Tx" SG_ 1438 GWM_AutoSarNMControl 1;
BA_ "U_CX727_MY2021_Rx" SG_ 282 VehicleGGCCData 1;
BA_ "U_P702_MY2021_Rx" SG_ 282 VehicleGGCCData 1;
BA_ "U_T6_MCA_MY2020_Rx" SG_ 282 VehicleGGCCData 1;
BA_ "U_CD542_MY2021_Rx" SG_ 282 VehicleGGCCData 1;
BA_ "U_U55X_MY2022_Rx" SG_ 282 VehicleGGCCData 1;
BA_ "U_CD764_MY2022_Rx" SG_ 282 VehicleGGCCData 1;
BA_ "GenSigSendType" SG_ 1876 TesterPhysicalReqTCU 3;
BA_ "U_CX727_MY2021_Rx" SG_ 1876 TesterPhysicalReqTCU 1;
BA_ "U_P702_MY2021_Rx" SG_ 1876 TesterPhysicalReqTCU 1;
BA_ "U_T6_MCA_MY2020_Rx" SG_ 1876 TesterPhysicalReqTCU 1;
BA_ "U_CD542_MY2021_Rx" SG_ 1876 TesterPhysicalReqTCU 1;
BA_ "U_U55X_MY2022_Rx" SG_ 1876 TesterPhysicalReqTCU 1;
BA_ "U_CD764_MY2022_Rx" SG_ 1876 TesterPhysicalReqTCU 1;
BA_ "GenSigSendType" SG_ 1884 TesterPhysicalResTCU 3;
BA_ "U_CX727_MY2021_Tx" SG_ 1884 TesterPhysicalResTCU 1;
BA_ "U_P702_MY2021_Tx" SG_ 1884 TesterPhysicalResTCU 1;
BA_ "U_T6_MCA_MY2020_Tx" SG_ 1884 TesterPhysicalResTCU 1;
BA_ "U_CD542_MY2021_Tx" SG_ 1884 TesterPhysicalResTCU 1;
BA_ "U_U55X_MY2022_Tx" SG_ 1884 TesterPhysicalResTCU 1;
BA_ "U_CD764_MY2022_Tx" SG_ 1884 TesterPhysicalResTCU 1;
BA_ "GenSigStartValueInteger" SG_ 1424 TCU_GWOnBoardTester 255;
BA_ "ContentDependant" SG_ 1424 TCU_GWOnBoardTester 1;
BA_ "GenSigStartValue" SG_ 1424 TCU_GWOnBoardTester 255;
BA_ "U_CX727_MY2021_Tx" SG_ 1424 TCU_GWOnBoardTester 1;
BA_ "U_P702_MY2021_Tx" SG_ 1424 TCU_GWOnBoardTester 1;
BA_ "U_T6_MCA_MY2020_Tx" SG_ 1424 TCU_GWOnBoardTester 1;
BA_ "U_CD542_MY2021_Tx" SG_ 1424 TCU_GWOnBoardTester 1;
BA_ "U_U55X_MY2022_Tx" SG_ 1424 TCU_GWOnBoardTester 1;
BA_ "U_CD764_MY2022_Tx" SG_ 1424 TCU_GWOnBoardTester 1;
BA_ "GenSigStartValueInteger" SG_ 1424 TCU_GWNMProxy 255;
BA_ "ContentDependant" SG_ 1424 TCU_GWNMProxy 1;
BA_ "GenSigStartValue" SG_ 1424 TCU_GWNMProxy 255;
BA_ "U_CX727_MY2021_Tx" SG_ 1424 TCU_GWNMProxy 1;
BA_ "U_P702_MY2021_Tx" SG_ 1424 TCU_GWNMProxy 1;
BA_ "U_T6_MCA_MY2020_Tx" SG_ 1424 TCU_GWNMProxy 1;
BA_ "U_CD542_MY2021_Tx" SG_ 1424 TCU_GWNMProxy 1;
BA_ "U_U55X_MY2022_Tx" SG_ 1424 TCU_GWNMProxy 1;
BA_ "U_CD764_MY2022_Tx" SG_ 1424 TCU_GWNMProxy 1;
BA_ "GenSigStartValueInteger" SG_ 1424 TCU_AutoSarNMReserved4 255;
BA_ "ContentDependant" SG_ 1424 TCU_AutoSarNMReserved4 1;
BA_ "GenSigStartValue" SG_ 1424 TCU_AutoSarNMReserved4 255;
BA_ "U_CX727_MY2021_Tx" SG_ 1424 TCU_AutoSarNMReserved4 1;
BA_ "U_P702_MY2021_Tx" SG_ 1424 TCU_AutoSarNMReserved4 1;
BA_ "U_T6_MCA_MY2020_Tx" SG_ 1424 TCU_AutoSarNMReserved4 1;
BA_ "U_CD542_MY2021_Tx" SG_ 1424 TCU_AutoSarNMReserved4 1;
BA_ "U_U55X_MY2022_Tx" SG_ 1424 TCU_AutoSarNMReserved4 1;
BA_ "U_CD764_MY2022_Tx" SG_ 1424 TCU_AutoSarNMReserved4 1;
BA_ "GenSigStartValueInteger" SG_ 1424 TCU_AutoSarNMReserved3 255;
BA_ "ContentDependant" SG_ 1424 TCU_AutoSarNMReserved3 1;
BA_ "GenSigStartValue" SG_ 1424 TCU_AutoSarNMReserved3 255;
BA_ "U_CX727_MY2021_Tx" SG_ 1424 TCU_AutoSarNMReserved3 1;
BA_ "U_P702_MY2021_Tx" SG_ 1424 TCU_AutoSarNMReserved3 1;
BA_ "U_T6_MCA_MY2020_Tx" SG_ 1424 TCU_AutoSarNMReserved3 1;
BA_ "U_CD542_MY2021_Tx" SG_ 1424 TCU_AutoSarNMReserved3 1;
BA_ "U_U55X_MY2022_Tx" SG_ 1424 TCU_AutoSarNMReserved3 1;
BA_ "U_CD764_MY2022_Tx" SG_ 1424 TCU_AutoSarNMReserved3 1;
BA_ "GenSigStartValueInteger" SG_ 1424 TCU_AutoSarNMReserved2 255;
BA_ "ContentDependant" SG_ 1424 TCU_AutoSarNMReserved2 1;
BA_ "GenSigStartValue" SG_ 1424 TCU_AutoSarNMReserved2 255;
BA_ "U_CX727_MY2021_Tx" SG_ 1424 TCU_AutoSarNMReserved2 1;
BA_ "U_P702_MY2021_Tx" SG_ 1424 TCU_AutoSarNMReserved2 1;
BA_ "U_T6_MCA_MY2020_Tx" SG_ 1424 TCU_AutoSarNMReserved2 1;
BA_ "U_CD542_MY2021_Tx" SG_ 1424 TCU_AutoSarNMReserved2 1;
BA_ "U_U55X_MY2022_Tx" SG_ 1424 TCU_AutoSarNMReserved2 1;
BA_ "U_CD764_MY2022_Tx" SG_ 1424 TCU_AutoSarNMReserved2 1;
BA_ "GenSigStartValueInteger" SG_ 1424 TCU_AutoSarNMReserved1 255;
BA_ "ContentDependant" SG_ 1424 TCU_AutoSarNMReserved1 1;
BA_ "GenSigStartValue" SG_ 1424 TCU_AutoSarNMReserved1 255;
BA_ "U_CX727_MY2021_Tx" SG_ 1424 TCU_AutoSarNMReserved1 1;
BA_ "U_P702_MY2021_Tx" SG_ 1424 TCU_AutoSarNMReserved1 1;
BA_ "U_T6_MCA_MY2020_Tx" SG_ 1424 TCU_AutoSarNMReserved1 1;
BA_ "U_CD542_MY2021_Tx" SG_ 1424 TCU_AutoSarNMReserved1 1;
BA_ "U_U55X_MY2022_Tx" SG_ 1424 TCU_AutoSarNMReserved1 1;
BA_ "U_CD764_MY2022_Tx" SG_ 1424 TCU_AutoSarNMReserved1 1;
BA_ "GenSigStartValueInteger" SG_ 1424 TCU_AutoSarNMNodeId 144;
BA_ "ContentDependant" SG_ 1424 TCU_AutoSarNMNodeId 1;
BA_ "GenSigStartValue" SG_ 1424 TCU_AutoSarNMNodeId 144;
BA_ "U_CX727_MY2021_Tx" SG_ 1424 TCU_AutoSarNMNodeId 1;
BA_ "U_P702_MY2021_Tx" SG_ 1424 TCU_AutoSarNMNodeId 1;
BA_ "U_T6_MCA_MY2020_Tx" SG_ 1424 TCU_AutoSarNMNodeId 1;
BA_ "U_CD542_MY2021_Tx" SG_ 1424 TCU_AutoSarNMNodeId 1;
BA_ "U_U55X_MY2022_Tx" SG_ 1424 TCU_AutoSarNMNodeId 1;
BA_ "U_CD764_MY2022_Tx" SG_ 1424 TCU_AutoSarNMNodeId 1;
BA_ "ContentDependant" SG_ 1424 TCU_AutoSarNMControl 1;
BA_ "U_CX727_MY2021_Tx" SG_ 1424 TCU_AutoSarNMControl 1;
BA_ "U_P702_MY2021_Tx" SG_ 1424 TCU_AutoSarNMControl 1;
BA_ "U_T6_MCA_MY2020_Tx" SG_ 1424 TCU_AutoSarNMControl 1;
BA_ "U_CD542_MY2021_Tx" SG_ 1424 TCU_AutoSarNMControl 1;
BA_ "U_U55X_MY2022_Tx" SG_ 1424 TCU_AutoSarNMControl 1;
BA_ "U_CD764_MY2022_Tx" SG_ 1424 TCU_AutoSarNMControl 1;
BA_ "GenSigSendType" SG_ 2015 TesterFunctionalReq 3;
BA_ "U_CX727_MY2021_Rx" SG_ 2015 TesterFunctionalReq 1;
BA_ "U_P702_MY2021_Rx" SG_ 2015 TesterFunctionalReq 1;
BA_ "U_T6_MCA_MY2020_Rx" SG_ 2015 TesterFunctionalReq 1;
BA_ "U_CD542_MY2021_Rx" SG_ 2015 TesterFunctionalReq 1;
BA_ "U_U55X_MY2022_Rx" SG_ 2015 TesterFunctionalReq 1;
BA_ "U_CD764_MY2022_Rx" SG_ 2015 TesterFunctionalReq 1;
BA_ "ECGUsedRxSignal" SG_ 2015 TesterFunctionalReq 1;
BA_ "GenSigSendType" SG_ 1814 TesterPhysicalReqGWM_H4 3;
BA_ "U_T6_MCA_MY2020_Rx" SG_ 1814 TesterPhysicalReqGWM_H4 1;
BA_ "ECGUsedRxSignal" SG_ 1814 TesterPhysicalReqGWM_H4 1;
BA_ "U_CD542_MY2021_Rx" SG_ 1814 TesterPhysicalReqGWM_H4 1;
BA_ "U_U55X_MY2022_Rx" SG_ 1814 TesterPhysicalReqGWM_H4 1;
BA_ "U_CD764_MY2022_Rx" SG_ 1814 TesterPhysicalReqGWM_H4 1;
VAL_ 76 RstrnPsngrOn_D_Stat 15 "Faulty" 14 "NotUsed_11" 13 "NotUsed_10" 12 "ConfiguredOff" 11 "NotUsed_9" 10 "On" 9 "NotUsed_8" 8 "NotUsed_7" 7 "NotUsed_6" 6 "NotUsed_5" 5 "Off" 4 "NotUsed_4" 3 "NotUsed_3" 2 "NotUsed_2" 1 "NotUsed_1" 0 "NoAction" ;
VAL_ 76 PsngrFmidDetct_D_Actl 3 "Unknown" 2 "Empty" 1 "Occupied" 0 "Fault" ;
VAL_ 76 FirstRowBuckleMid 3 "Unknown" 2 "Unbelted" 1 "Belted" 0 "Faulty" ;
VAL_ 76 ThirdRowBucklePsngr 3 "Unknown" 2 "Unbelted" 1 "Belted" 0 "Faulty" ;
VAL_ 76 ThirdRowBuckleMid 3 "Unknown" 2 "Unbelted" 1 "Belted" 0 "Faulty" ;
VAL_ 76 ThirdRowBuckleDriver 3 "Unknown" 2 "Unbelted" 1 "Belted" 0 "Faulty" ;
VAL_ 76 SecondRowBucklePsngr 3 "Unknown" 2 "Unbelted" 1 "Belted" 0 "Faulty" ;
VAL_ 76 SecondRowBuckleMid 3 "Unknown" 2 "Unbelted" 1 "Belted" 0 "Faulty" ;
VAL_ 76 SecondRowBuckleDriver 3 "Unknown" 2 "Unbelted" 1 "Belted" 0 "Faulty" ;
VAL_ 76 FirstRowBuckleDriver 3 "Unknown" 2 "Unbelted" 1 "Belted" 0 "Faulty" ;
VAL_ 76 RILReq 3 "Not_Used" 2 "Plant_Mode" 1 "On" 0 "Off" ;
VAL_ 76 FirstRowBucklePsngr 3 "Unknown" 2 "Unbelted" 1 "Belted" 0 "Faulty" ;
VAL_ 76 RstrnImpactEvntStatus 7 "Invalid" 6 "Not_Used_4" 5 "Threshold_2_Exceeded" 4 "Not_Used_3" 3 "Threshold_1_Exceeded" 2 "Not_Used_2" 1 "Not_Used_1" 0 "Normal" ;
VAL_ 76 PsngrFrntDetct_D_Actl 3 "Unknown" 2 "Empty" 0 "Faulty" 1 "Occupied" ;
VAL_ 76 EDRTriggerEvntSync 1 "Threshold_Exceeded" 0 "Normal" ;
VAL_ 76 PassRstrnInd_Req 3 "ABOnNotIllum_OffNotIllum" 2 "AirbagOnNot_Illum_OffIllum" 1 "AirbagOn_Illum_OffNotIllum" 0 "AirbagOn_Illum_Off_Illum" ;
VAL_ 1088 TrlrRng_L_Dsply 8191 "Faulty" 8190 "NoDataExists" ;
VAL_ 1088 ChrgStat_D2_Dsply 15 "ChargeStopCommanded" 14 "ChargeStartCommanded" 13 "ChargeTargetReached" 12 "DriveConditioning" 11 "CabinPreconditioning" 10 "ChargingSystemMaintain" 9 "ChargingInductive" 8 "ChargingDCFastCharge" 7 "ChargingAC" 6 "ChargeScheduled" 5 "EvsePaused" 4 "EvseNotDetected" 3 "EvseNotCompatible" 2 "FaultOutsideCar" 1 "FaultInsideCar" 0 "NotReady" ;
VAL_ 1088 ChrgTMatch_B_Stat 1 "True" 0 "False" ;
VAL_ 1088 HvacPrecondRecirc_D_Rq 3 "Last_User_Setting" 2 "Auto" 1 "Recirc" 0 "Outside" ;
VAL_ 1088 HvacPrecondMode2_D_Rq 15 "NotUsed4" 14 "NotUsed3" 13 "NotUsed2" 12 "NotUsed1" 11 "Last_User_Settings" 10 "Auto" 9 "Max_Defrost" 8 "Windshield_Panel_Floor" 7 "Windshield_Panel" 6 "Windshield" 5 "Windshield_Floor" 4 "Floor" 3 "Panel_Floor" 2 "Panel" 1 "MAX_AC" 0 "Off" ;
VAL_ 1088 HvacPrecondBlwr2_D_Rq 15 "NotUsed6" 14 "NotUsed5" 13 "NotUsed4" 12 "NotUsed3" 11 "NotUsed2" 10 "NotUsed1" 9 "Last_User_Setting" 8 "Auto" 7 "Speed7" 6 "Speed6" 5 "Speed5" 4 "Speed4" 3 "Speed3" 2 "Speed2" 1 "Speed1" 0 "Off" ;
VAL_ 1088 HvacPrecondAC_D_Rq 3 "Last_User_Setting" 2 "Auto" 1 "On" 0 "Off" ;
VAL_ 1088 BattChrgInhbt_D_Rq 3 "MaintainTargetSoc" 2 "NotUsed" 1 "InhibitChargingThermal" 0 "Enable_Charging" ;
VAL_ 1088 BattDcChrgRms_I_Lim 32767 "Faulty" 32766 "NoDataExists" ;
VAL_ 433 PrkLckCtlLatch_B_Rq 1 "On" 0 "Off" ;
VAL_ 433 KeyPadCodeDgt7_D_Dsply 15 "NotUsed_4" 14 "NotUsed_3" 13 "NotUsed_2" 12 "NotUsed_1" 11 "Button7_8and9_0" 10 "Button0" 9 "Button9_0or9" 8 "Button8" 7 "Button7_8or7" 6 "Button6" 5 "Button5_6or5" 4 "Button4" 3 "Button3_4or3" 2 "Button2" 1 "Button1_2or1" 0 "EndofString" ;
VAL_ 433 KeyPadCodeDgt6_D_Dsply 15 "NotUsed_4" 14 "NotUsed_3" 13 "NotUsed_2" 12 "NotUsed_1" 11 "Button7_8and9_0" 10 "Button0" 9 "Button9_0or9" 8 "Button8" 7 "Button7_8or7" 6 "Button6" 5 "Button5_6or5" 4 "Button4" 3 "Button3_4or3" 2 "Button2" 1 "Button1_2or1" 0 "EndofString" ;
VAL_ 433 KeyPadCodeDgt5_D_Dsply 15 "NotUsed_4" 14 "NotUsed_3" 13 "NotUsed_2" 12 "NotUsed_1" 11 "Button7_8and9_0" 10 "Button0" 9 "Button9_0or9" 8 "Button8" 7 "Button7_8or7" 6 "Button6" 5 "Button5_6or5" 4 "Button4" 3 "Button3_4or3" 2 "Button2" 1 "Button1_2or1" 0 "EndofString" ;
VAL_ 433 KeyPadCodeDgt4_D_Dsply 15 "NotUsed_4" 14 "NotUsed_3" 13 "NotUsed_2" 12 "NotUsed_1" 11 "Button7_8and9_0" 10 "Button0" 9 "Button9_0or9" 8 "Button8" 7 "Button7_8or7" 6 "Button6" 5 "Button5_6or5" 4 "Button4" 3 "Button3_4or3" 2 "Button2" 1 "Button1_2or1" 0 "EndofString" ;
VAL_ 433 KeyPadCodeDgt3_D_Dsply 15 "NotUsed_4" 14 "NotUsed_3" 13 "NotUsed_2" 12 "NotUsed_1" 11 "Button7_8and9_0" 10 "Button0" 9 "Button9_0or9" 8 "Button8" 7 "Button7_8or7" 6 "Button6" 5 "Button5_6or5" 4 "Button4" 3 "Button3_4or3" 2 "Button2" 1 "Button1_2or1" 0 "EndofString" ;
VAL_ 433 KeyPadCodeDgt2_D_Dsply 15 "NotUsed_4" 14 "NotUsed_3" 13 "NotUsed_2" 12 "NotUsed_1" 11 "Button7_8and9_0" 10 "Button0" 9 "Button9_0or9" 8 "Button8" 7 "Button7_8or7" 6 "Button6" 5 "Button5_6or5" 4 "Button4" 3 "Button3_4or3" 2 "Button2" 1 "Button1_2or1" 0 "EndofString" ;
VAL_ 433 KeyPadCodeDgt1_D_Dsply 15 "NotUsed_4" 14 "NotUsed_3" 13 "NotUsed_2" 12 "NotUsed_1" 11 "Button7_8and9_0" 10 "Button0" 9 "Button9_0or9" 8 "Button8" 7 "Button7_8or7" 6 "Button6" 5 "Button5_6or5" 4 "Button4" 3 "Button3_4or3" 2 "Button2" 1 "Button1_2or1" 0 "EndofString" ;
VAL_ 433 KeyOffMde_D_Actl 15 "NotUsed_11" 14 "NotUsed_10" 13 "NotUsed_9" 12 "NotUsed_8" 11 "NotUsed_7" 10 "NotUsed_6" 9 "NotUsed_5" 8 "NotUsed_4" 7 "NotUsed_3" 6 "NotUsed_2" 5 "NotUsed_1" 4 "CriticalBattery" 3 "Hibernate" 2 "Transport" 1 "Factory" 0 "Normal" ;
VAL_ 145 VehYawWActl_D_Qf 3 "OK" 2 "Not_Within_Specifications" 1 "No_Data_Exists" 0 "Faulty" ;
VAL_ 145 VehRolWActl_D_Qf 3 "OK" 2 "Not_Within_Specifications" 1 "No_Data_Exists" 0 "Faulty" ;
VAL_ 145 VehYaw_W_Actl 65535 "Faulty" 65534 "NoDataExists" ;
VAL_ 145 VehRol_W_Actl 65535 "Faulty" 65534 "NoDataExists" ;
VAL_ 626 PaakCtlIndx8_D_Stat 15 "NotUsed_9" 14 "NotUsed_8" 13 "NotUsed_7" 12 "NotUsed_6" 11 "NotUsed_5" 10 "NotUsed_4" 9 "NotUsed_3" 8 "NotUsed_2" 7 "NotUsed_1" 6 "Approach" 5 "RearInterior" 4 "RearExterior" 3 "Passenger" 2 "Driver" 1 "Interior" 0 "Null" ;
VAL_ 626 PaakCtlIndx7_D_Stat 15 "NotUsed_9" 14 "NotUsed_8" 13 "NotUsed_7" 12 "NotUsed_6" 11 "NotUsed_5" 10 "NotUsed_4" 9 "NotUsed_3" 8 "NotUsed_2" 7 "NotUsed_1" 6 "Approach" 5 "RearInterior" 4 "RearExterior" 3 "Passenger" 2 "Driver" 1 "Interior" 0 "Null" ;
VAL_ 626 PaakCtlIndx6_D_Stat 15 "NotUsed_9" 14 "NotUsed_8" 13 "NotUsed_7" 12 "NotUsed_6" 11 "NotUsed_5" 10 "NotUsed_4" 9 "NotUsed_3" 8 "NotUsed_2" 7 "NotUsed_1" 6 "Approach" 5 "RearInterior" 4 "RearExterior" 3 "Passenger" 2 "Driver" 1 "Interior" 0 "Null" ;
VAL_ 626 PaakCtlIndx5_D_Stat 15 "NotUsed_9" 14 "NotUsed_8" 13 "NotUsed_7" 12 "NotUsed_6" 11 "NotUsed_5" 10 "NotUsed_4" 9 "NotUsed_3" 8 "NotUsed_2" 7 "NotUsed_1" 6 "Approach" 5 "RearInterior" 4 "RearExterior" 3 "Passenger" 2 "Driver" 1 "Interior" 0 "Null" ;
VAL_ 626 PaakCtlIndx4_D_Stat 15 "NotUsed_9" 14 "NotUsed_8" 13 "NotUsed_7" 12 "NotUsed_6" 11 "NotUsed_5" 10 "NotUsed_4" 9 "NotUsed_3" 8 "NotUsed_2" 7 "NotUsed_1" 6 "Approach" 5 "RearInterior" 4 "RearExterior" 3 "Passenger" 2 "Driver" 1 "Interior" 0 "Null" ;
VAL_ 626 PaakCtlIndx3_D_Stat 15 "NotUsed_9" 14 "NotUsed_8" 13 "NotUsed_7" 12 "NotUsed_6" 11 "NotUsed_5" 10 "NotUsed_4" 9 "NotUsed_3" 8 "NotUsed_2" 7 "NotUsed_1" 6 "Approach" 5 "RearInterior" 4 "RearExterior" 3 "Passenger" 2 "Driver" 1 "Interior" 0 "Null" ;
VAL_ 626 PaakCtlIndx2_D_Stat 15 "NotUsed_9" 14 "NotUsed_8" 13 "NotUsed_7" 12 "NotUsed_6" 11 "NotUsed_5" 10 "NotUsed_4" 9 "NotUsed_3" 8 "NotUsed_2" 7 "NotUsed_1" 6 "Approach" 5 "RearInterior" 4 "RearExterior" 3 "Passenger" 2 "Driver" 1 "Interior" 0 "Null" ;
VAL_ 626 PaakCtlIndx1_D_Stat 15 "NotUsed_9" 14 "NotUsed_8" 13 "NotUsed_7" 12 "NotUsed_6" 11 "NotUsed_5" 10 "NotUsed_4" 9 "NotUsed_3" 8 "NotUsed_2" 7 "NotUsed_1" 6 "Approach" 5 "RearInterior" 4 "RearExterior" 3 "Passenger" 2 "Driver" 1 "Interior" 0 "Null" ;
VAL_ 1045 VehStab_D_Stat 15 "Faulty" 14 "No_Data_Exists" 13 "NotUsed6" 12 "NotUsed5" 11 "NotUsed4" 10 "NotUsed3" 9 "NotUsed2" 8 "Combined_OS_and_US" 7 "High_SSRA_no_OS" 6 "Straight" 5 "Post_Oversteer" 4 "Post_Transition" 3 "Countersteer" 2 "Understeer" 1 "Oversteer" 0 "Linear" ;
VAL_ 1045 BrkFluidLvl_D_Stat 3 "Invalid" 2 "Unknown" 1 "Low" 0 "OK" ;
VAL_ 1045 LsmcBrkDecel_D_Stat 7 "NotUsed_3" 6 "NotUsed_2" 5 "NotUsed_1" 4 "Denied" 3 "FaultDegraded" 2 "FaultExt" 1 "On" 0 "Off" ;
VAL_ 1045 VehYawNonLin_W_Rq 4095 "Fault" 4094 "Unknown" ;
VAL_ 1045 VehYawLin_W_Rq 4095 "Fault" 4094 "Unknown" ;
VAL_ 1045 VehVActlBrk_D_Qf 3 "OK" 2 "Not_Within_Specifications" 1 "No_Data_Exists" 0 "Faulty" ;
VAL_ 267 GearPos_D_Trg_UB 1 "Fresh_data" 0 "Unchanged_data" ;
VAL_ 267 GearPos_D_Trg 15 "Unknown" 14 "Reverse" 13 "Undefined_5" 12 "Undefined_4" 11 "Undefined_3" 10 "Tenth" 9 "Ninth" 8 "Eighth" 7 "Seventh" 6 "Sixth" 5 "Fifth" 4 "Fourth" 3 "Third" 2 "Second" 1 "First" 0 "Neutral" ;
VAL_ 267 BrkHold_D_Stat 7 "NotUsed_3" 6 "NotUsed_2" 5 "NotUsed_1" 4 "HeldSecondary" 3 "HeldSecure" 2 "Held" 1 "Inactive" 0 "Off" ;
VAL_ 267 PwPckTq_D_Stat_UB 1 "Fresh_data" 0 "Unchanged_data" ;
VAL_ 267 PwPckTq_D_Stat 3 "PwPckOn_TqAvailable" 2 "StartInPrgrss_TqNotAvail" 1 "PwPckOn_TqNotAvailable" 0 "PwPckOff_TqNotAvailable" ;
VAL_ 267 BrkHold_D_Stat_UB 1 "Fresh_data" 0 "Unchanged_data" ;
VAL_ 267 TrlrLampCnnct_B_Actl_UB 1 "Fresh_data" 0 "Unchanged_data" ;
VAL_ 267 TrlrLampCnnct_B_Actl 1 "Yes" 0 "No" ;
VAL_ 267 DISP_SetVolume_Rq_UB 1 "Fresh_data" 0 "Unchanged_data" ;
VAL_ 290 WifiHtsptScrty_D_Rq 3 "NotUsed_1" 2 "Wapi" 1 "Wpa2_Wpa" 0 "Null" ;
VAL_ 290 WifiHtsptFqBand_D_Rq 3 "NotUsed_1" 2 "Band_2" 1 "Band_1" 0 "Null" ;
VAL_ 290 WifiHtsptTrial_D_RqDrv 3 "NotUsed_1" 2 "StopReminders" 1 "RemindMeLater" 0 "Null" ;
VAL_ 290 WifiHtsptEnbl_D_Rq 3 "Not used" 2 "On" 1 "Off" 0 "Null" ;
VAL_ 290 WifiRemoveDevc_D_Rq 3 "NotUsed_1" 2 "FromBlockedList" 1 "FromConnectedList" 0 "Null" ;
VAL_ 290 WifiHtsptVisbl_D_Rq 3 "Not used" 2 "On" 1 "Off" 0 "Null" ;
VAL_ 290 WifiHtsptMacAddr_B_Rq 1 "Request" 0 "No request" ;
VAL_ 290 WifiDevcList_D_Rq 3 "NoEntry" 2 "BlockedList" 1 "ConnectedList" 0 "Null" ;
VAL_ 290 WifiDataUsage_D_Rq 3 "RetriveDataFromBackend" 2 "RefreshData" 1 "CurrentData" 0 "Null" ;
VAL_ 290 WifiCarrierInfo_B_Rq 1 "Request" 0 "No  request" ;
VAL_ 636 WifiHtsptFqBand_D_Stat 3 "NotUsed_1" 2 "Band_2" 1 "Band_1" 0 "Null" ;
VAL_ 636 WifiHtspt_D_Falt 15 "Error15" 14 "Error14" 13 "Error13" 12 "Error12" 11 "Error11" 10 "Error10" 9 "Error9" 8 "Error8" 7 "Error7" 6 "Error6" 5 "Error5" 4 "Error4" 3 "Error3" 2 "Error2" 1 "Error1" 0 "Null" ;
VAL_ 636 WifiHtsptCnnct_D_Stat 3 "NotUsed" 2 "Connected" 1 "NotConnected" 0 "Null" ;
VAL_ 636 Telematics_D_Falt 7 "NotUsed_5" 6 "NotUsed_4" 5 "NotUsed_3" 4 "NotUsed_2" 3 "NotUsed_1" 2 "RunTimeError" 1 "ChipsetInitializationFailu" 0 "Null" ;
VAL_ 636 WifiEnbl_D_Stat 3 "NotUsed" 2 "Enable" 1 "Disable" 0 "Null" ;
VAL_ 636 WifiHtsptVisbl_D_Stat 3 "Not  used" 2 "On" 1 "Off" 0 "Null" ;
VAL_ 636 WifiHtsptScrty_D_Stat 3 "NotUsed_1" 2 "Wapi" 1 "Wpa2_Wpa" 0 "Null" ;
VAL_ 636 WifiHtsptEnbl_D_Stat 3 "OnDisabled" 2 "On" 1 "Off" 0 "Null" ;
VAL_ 636 WifiDevcListNew_B_Stat 1 "Available" 0 "NotAvailable" ;
VAL_ 636 WifiDataUsage_D_Stat 3 "PercentDataUsed" 2 "DataPlanExpired" 1 "FreeTrialPeriodWaiting" 0 "Null" ;
VAL_ 636 ModemSigStren_D_Stat 7 "NotUsed_1" 6 "NotDetermined" 5 "FiveBars" 4 "FourBars" 3 "ThreeBars" 2 "TwoBars" 1 "OneBar" 0 "ZeroBars" ;
VAL_ 636 WifiHtsptCrdntl_B_Stat 1 "Available" 0 "NotAvailable" ;
VAL_ 636 WifiHtsptFq_D_Avail 7 "NotUsed_3" 6 "NotUsed_2" 5 "NotUsed_1" 4 "AllAvailable" 3 "Band_2_Only" 2 "Band_1_Only" 1 "AllRestricted" 0 "Null" ;
VAL_ 636 WifiDataUsageOn_D_Stat 3 "NotUsed" 2 "On" 1 "Off" 0 "Null" ;
VAL_ 636 ModemTechnology_D2_Stat 7 "Lte" 6 "HspaPlus" 5 "Umts" 4 "Edge" 3 "Gprs" 2 "Gsm" 1 "NoNetwork" 0 "Null" ;
VAL_ 895 TurnLght_D_RqRmtCtl 3 "NotUsed" 2 "Right" 1 "Left" 0 "Null" ;
VAL_ 895 RmtCtlRngSet_D_Rq 3 "NotUsed" 2 "RangeSetB" 1 "RangeSetA" 0 "None" ;
VAL_ 895 RmtCtlKeyPoll_D_Rq 3 "NotUsed" 2 "Polling" 1 "NoPolling" 0 "Null" ;
VAL_ 895 RmtCtlCntnsIn_B_Stat 1 "Available" 0 "NotAvailable" ;
VAL_ 895 RmtCtl_D_Stat 15 "Faulty" 14 "NotUsed_5" 13 "NotUsed_4" 12 "NotUsed_3" 11 "NotUsed_2" 10 "NotUsed_1" 9 "Shutdown" 8 "ManeuverFinished" 7 "ReadyForResume" 6 "Pause" 5 "Maneuvering" 4 "ReadyForManeuvering" 3 "Activation" 2 "Initialize" 1 "Preparation" 0 "Disabled" ;
VAL_ 265 OdometerMasterValue_UB 1 "Fresh_data" 0 "Unchanged_data" ;
VAL_ 265 OdometerMasterValue 16777215 "Invalid" ;
VAL_ 266 TCMode_UB 1 "Fresh_data" 0 "Unchanged_data" ;
VAL_ 266 TCMode 1 "Active" 0 "Inactive" ;
VAL_ 266 Disp_LangSel2_St_UB 1 "Fresh_data" 0 "Unchanged_data" ;
VAL_ 266 Disp_LangSel_St_UB 1 "Fresh_data" 0 "Unchanged_data" ;
VAL_ 266 Mc_VehLangUsrSel_St_UB 1 "Fresh_data" 0 "Unchanged_data" ;
VAL_ 266 Mc_VehLangUsrSel_St 32 "Indian_English" 31 "Thai" 30 "Slovak" 29 "Arabic" 28 "Taiwanese" 27 "Mandarin_Chinese" 26 "Korean" 25 "AU_English" 24 "Japanese" 23 "Braz_Portuguese" 22 "EU_Portuguese" 21 "Finish" 20 "Norwegian" 19 "Danish" 18 "Swedish" 17 "Hungarian" 16 "Greek" 15 "Czech" 14 "Polish" 13 "Flemish" 12 "Dutch" 11 "Russian" 10 "Turkish" 9 "Mex_Spanish" 8 "EU_Spanish" 7 "Cana_French" 6 "EU_French" 5 "Italian" 4 "German" 3 "NA_English" 2 "UK_English" 1 "Unknown" 0 "Invalid" ;
VAL_ 266 HMI_HMIMode_St_UB 1 "Fresh_data" 0 "Unchanged_data" ;
VAL_ 266 HMI_HMIMode_St 7 "NotUsed2" 6 "NotUsed1" 5 "Load_Shed_Active" 0 "Invalid" 1 "OffMode" 2 "On" 3 "Phone" 4 "Climate" ;
VAL_ 266 Disp_LangSel_St 31 "Thai" 30 "Slovak" 29 "Arabic" 28 "Taiwanese" 27 "Mandarin_Chinese" 26 "Korean" 25 "AU_English" 24 "Japanese" 23 "Braz_Portuguese" 22 "EU_Portuguese" 21 "Finish" 20 "Norwegian" 19 "Danish" 18 "Swedish" 17 "Hungarian" 16 "Greek" 15 "Czech" 14 "Polish" 13 "Flemish" 12 "Dutch" 11 "Russian" 10 "Turkish" 9 "Mex_Spanish" 8 "EU_Spanish" 7 "Cana_French" 6 "EU_French" 5 "Italian" 4 "German" 3 "NA_English" 2 "UK_English" 1 "Unknown" 0 "Invalid" ;
VAL_ 266 Disp_LangSel2_St 32 "Indian_English" 31 "Thai" 30 "Slovak" 29 "Arabic" 28 "Taiwanese" 27 "Mandarin_Chinese" 26 "Korean" 25 "AU_English" 24 "Japanese" 23 "Braz_Portuguese" 22 "EU_Portuguese" 21 "Finish" 20 "Norwegian" 19 "Danish" 18 "Swedish" 17 "Hungarian" 16 "Greek" 15 "Czech" 14 "Polish" 13 "Flemish" 12 "Dutch" 11 "Russian" 10 "Turkish" 9 "Mex_Spanish" 8 "EU_Spanish" 7 "Cana_French" 6 "EU_French" 5 "Italian" 4 "German" 3 "NA_English" 2 "UK_English" 1 "Unknown" 0 "Invalid" ;
VAL_ 263 SteeringColumnTorque 255 "Invalid" 254 "Unknown" ;
VAL_ 263 SAPPAngleControlStat2 1 "Rel_ExtSteeringAngleReqx" 0 "NoRel_ExtSteeringAngleReqx" ;
VAL_ 263 SAPPAngleControlStat1 3 "Fault" 2 "Active" 1 "Open" 0 "Closed" ;
VAL_ 263 SteeringColumnTorque_UB 1 "Fresh_data" 0 "Unchanged_data" ;
VAL_ 263 SAPPAngleControlStat2_UB 1 "Fresh_data" 0 "Unchanged_data" ;
VAL_ 263 SAPPAngleControlStat1_UB 1 "Fresh_data" 0 "Unchanged_data" ;
VAL_ 263 ApedPos_Pc_ActlArb_UB 1 "Fresh_data" 0 "Unchanged_data" ;
VAL_ 263 WhlDirFl_D_Actl_UB 1 "Fresh_data" 0 "Unchanged_data" ;
VAL_ 263 Veh_V_ActlEng_UB 1 "Fresh_data" 0 "Unchanged_data" ;
VAL_ 263 WhlDirFl_D_Actl 3 "Faulty" 2 "NoDataExists" 1 "Backward" 0 "Forward" ;
VAL_ 261 RstrnImpactEvntStatus_UB 1 "Fresh_data" 0 "Unchanged_data" ;
VAL_ 261 RstrnImpactEvntStatus 7 "Invalid" 6 "Not_Used_4" 5 "Threshold_2_Exceeded" 4 "Not_Used_3" 3 "Threshold_1_Exceeded" 2 "Not_Used_2" 1 "Not_Used_1" 0 "Normal" ;
VAL_ 264 MirrorTelescopic_D_Rq 3 "NotUsed" 2 "Retract" 1 "Extend" 0 "Null" ;
VAL_ 264 MirrorTelescopic_D_Rq_UB 1 "Fresh_data" 0 "Unchanged_data" ;
VAL_ 264 Veh_Lock_Requestor_UB 1 "Fresh_data" 0 "Unchanged_data" ;
VAL_ 264 Veh_Lock_Requestor 31 "Walk_Away_Locking" 30 "Remote_Park_Assist" 29 "DoorsOffToOn_Smart_Unlock" 28 "Rgtm_Shutlock_Switch" 27 "Boundary_Alert" 26 "Transit_Vehicle_Relock" 25 "Transit_Cargo_Relock" 24 "Transit_Ajar_Lock" 23 "Diagnostics" 22 "Console_Lock" 21 "Child_Lock" 20 "Double_Lock" 19 "Passive_Pasenger" 18 "Passive_Driver" 17 "Slam_Lock_Protect" 16 "SYNC" 15 "Passport" 14 "Passive_Smart_Unlock" 13 "Autorelock" 12 "RemoteStart" 0 "Null" 1 "Autolock" 11 "Smart_Unlock" 10 "Sliding_Door" 9 "Passive" 8 "Remote" 7 "Programming" 6 "Powerslide" 5 "Keypad" 4 "Key_Cylinder" 3 "Interior" 2 "Auto_Unlock" ;
VAL_ 264 Veh_Lock_EvNum_UB 1 "Fresh_data" 0 "Unchanged_data" ;
VAL_ 264 PrkBrkStatus_UB 1 "Fresh_data" 0 "Unchanged_data" ;
VAL_ 264 PrkBrkStatus 7 "GeneralFault_MaintenceMode" 6 "ECD_by_Brake_ECU_Active" 5 "EPB_Limphome_Active" 4 "Rear_Caliper_Open" 3 "RWU_By_EPB_Active" 2 "Rear_Caliper_Transition" 1 "Rear_Caliper_Closed" 0 "Not_Supported" ;
VAL_ 257 PwSrcULoFalt_D_Stat_UB 1 "Fresh_data" 0 "Unchanged_data" ;
VAL_ 257 PwSrcULoFalt_D_Stat 3 "Fault_No_Output" 2 "Fault_Reduced_Output" 1 "Fault_NonSpecific" 0 "No_Fault" ;
VAL_ 257 GearRvrse_D_Actl_UB 1 "Fresh_data" 0 "Unchanged_data" ;
VAL_ 257 GearRvrse_D_Actl 7 "Fault" 6 "NotUsed_3" 5 "NotUsed_2" 4 "NotUsed_1" 3 "Active_confirmed" 2 "Active_not_confirmed" 1 "Inactive_confirmed" 0 "Inactive_not_confirmed" ;
VAL_ 257 GearLvrPos_D_Actl_UB 1 "Fresh_data" 0 "Unchanged_data" ;
VAL_ 257 GearLvrPos_D_Actl 15 "Fault" 14 "Unknown_Position" 13 "Undefined_Treat_as__Fault" 12 "Undefined_Treat_as_Fault" 11 "sixth" 10 "fifth" 9 "fourth" 8 "third" 7 "second" 6 "first" 5 "Low" 4 "Sport_DriveSport" 3 "Drive" 2 "Neutral" 1 "Reverse" 0 "Park" ;
VAL_ 256 Batt_Lo_SoC_B_UB 1 "Fresh_data" 0 "Unchanged_data" ;
VAL_ 256 Batt_Lo_SoC_B 1 "Active" 0 "Inactive" ;
VAL_ 256 Veh_Lock_Status_UB 1 "Fresh_data" 0 "Unchanged_data" ;
VAL_ 256 Veh_Lock_Status 3 "UNLOCK_DRV" 2 "UNLOCK_ALL" 1 "LOCK_ALL" 0 "LOCK_DBL" ;
VAL_ 256 BSBattSOC_UB 1 "Fresh_data" 0 "Unchanged_data" ;
VAL_ 638 EmgcyCallHmi_D_Stat 15 "NotUsed_1" 14 "Standby" 13 "Disabled" 12 "Malfunction" 11 "CallCompleted" 10 "CallDisconnected" 9 "CallNotPossible" 8 "CallCancelled" 7 "CallRetry" 6 "CallConnected" 5 "CallInProgress" 4 "CallMsdTransfer" 3 "CallDial" 2 "CallCancelTimer" 1 "NoEvent" 0 "Null" ;
VAL_ 638 EmgcyCallFalt_B_Dsply 1 "Yes" 0 "No" ;
VAL_ 638 EmgcyCall_D_Stat 7 "NotUsed_3" 6 "NotUsed_2" 5 "NotUsed_1" 4 "ManualEmergencyCall" 3 "AutoEmergencyCall" 2 "NoEvent" 1 "EmergencyCallNotSupported" 0 "Null" ;
VAL_ 75 VedsPasKneeBag_D_Ltchd 7 "Fault" 6 "NotSupported" 5 "Unused_3" 4 "Unused_2" 3 "Unused_1" 2 "NotDeployed" 1 "Deployed" 0 "NoEvent" ;
VAL_ 75 VedsRw3pRib_D_Ltchd 7 "Fault" 6 "NotSupported" 5 "Unused_3" 4 "Unused_2" 3 "Unused_1" 2 "NotDeployed" 1 "Deployed" 0 "NoEvent" ;
VAL_ 75 VedsRw3dRib_D_Ltchd 7 "Fault" 6 "NotSupported" 5 "Unused_3" 4 "Unused_2" 3 "Unused_1" 2 "NotDeployed" 1 "Deployed" 0 "NoEvent" ;
VAL_ 75 VedsRw1mBckl_D_Ltchd 5 "Unused_3" 4 "Unused_2" 3 "Unused_1" 2 "NotBelted" 1 "Belted" 0 "NoEvent" 7 "Fault" 6 "NotSupported" ;
VAL_ 75 VedsRw1mBelt_D_Ltchd 7 "Fault" 6 "NotSupported" 5 "Unused_3" 4 "Unused_2" 3 "Unused_1" 2 "NotDeployed" 1 "Deployed" 0 "NoEvent" ;
VAL_ 75 VedsRw2pRib_D_Ltchd 7 "Fault" 6 "NotSupported" 5 "Unused_3" 4 "Unused_2" 3 "Unused_1" 2 "NotDeployed" 1 "Deployed" 0 "NoEvent" ;
VAL_ 75 VedsRw2dRib_D_Ltchd 7 "Fault" 6 "NotSupported" 5 "Unused_3" 4 "Unused_2" 3 "Unused_1" 2 "NotDeployed" 1 "Deployed" 0 "NoEvent" ;
VAL_ 75 VedsRw3pBckl_D_Ltchd 5 "Unused_3" 4 "Unused_2" 3 "Unused_1" 2 "NotBelted" 1 "Belted" 0 "NoEvent" 7 "Fault" 6 "NotSupported" ;
VAL_ 75 VedsRw3mBckl_D_Ltchd 5 "Unused_3" 4 "Unused_2" 3 "Unused_1" 2 "NotBelted" 1 "Belted" 0 "NoEvent" 7 "Fault" 6 "NotSupported" ;
VAL_ 75 VedsRw3dBckl_D_Ltchd 5 "Unused_3" 4 "Unused_2" 3 "Unused_1" 2 "NotBelted" 1 "Belted" 0 "NoEvent" 7 "Fault" 6 "NotSupported" ;
VAL_ 75 VedsRw2pBckl_D_Ltchd 5 "Unused_3" 4 "Unused_2" 3 "Unused_1" 2 "NotBelted" 1 "Belted" 0 "NoEvent" 7 "Fault" 6 "NotSupported" ;
VAL_ 75 VedsRw2mBckl_D_Ltchd 5 "Unused_3" 4 "Unused_2" 3 "Unused_1" 2 "NotBelted" 1 "Belted" 0 "NoEvent" 7 "Fault" 6 "NotSupported" ;
VAL_ 75 VedsRw2dBckl_D_Ltchd 5 "Unused_3" 4 "Unused_2" 3 "Unused_1" 2 "NotBelted" 1 "Belted" 0 "NoEvent" 7 "Fault" 6 "NotSupported" ;
VAL_ 75 VedsRw1PasChld_D_Ltchd 7 "Fault" 6 "NotSupported" 5 "Unused_3" 4 "Unused_2" 3 "Unused_1" 2 "ChildNotDetected" 1 "ChildDetected" 0 "NoEvent" ;
VAL_ 75 VedsRw1PasBckl_D_Ltchd 5 "Unused_3" 4 "Unused_2" 3 "Unused_1" 2 "NotBelted" 1 "Belted" 0 "NoEvent" 7 "Fault" 6 "NotSupported" ;
VAL_ 75 VedsRw1DrvBckl_D_Ltchd 5 "Unused_3" 4 "Unused_2" 3 "Unused_1" 2 "NotBelted" 1 "Belted" 0 "NoEvent" 7 "Fault" 6 "NotSupported" ;
VAL_ 74 VedsPasSideBag_D_Ltchd 7 "Fault" 6 "NotSupported" 5 "Unused_3" 4 "Unused_2" 3 "Unused_1" 2 "NotDeployed" 1 "Deployed" 0 "NoEvent" ;
VAL_ 74 VedsPasCrtnBag_D_Ltchd 7 "Fault" 6 "NotSupported" 5 "Unused_3" 4 "Unused_2" 3 "Unused_1" 2 "NotDeployed" 1 "Deployed" 0 "NoEvent" ;
VAL_ 74 VedsPasBelt_D_Ltchd 7 "Fault" 6 "NotSupported" 5 "Unused_3" 4 "Unused_2" 3 "Unused_1" 2 "NotDeployed" 1 "Deployed" 0 "NoEvent" ;
VAL_ 74 VedsPasBag_D_Ltchd 7 "Fault" 6 "NotSupported" 5 "Unused_3" 4 "Unused_2" 3 "Unused_1" 2 "NotDeployed" 1 "Deployed" 0 "NoEvent" ;
VAL_ 74 VedsMultiEvnt_D_Ltchd 7 "Fault" 6 "NotSupported" 5 "Unused_3" 4 "Unused_2" 3 "Unused_1" 2 "Yes" 1 "No" 0 "NoEvent" ;
VAL_ 74 VedsMaxDeltaV_D_Ltchd 0 "NoEvent" 255 "Fault" 254 "NotSupported" ;
VAL_ 74 VedsDrvKneeBag_D_Ltchd 7 "Fault" 6 "NotSupported" 5 "Unused_3" 4 "Unused_2" 3 "Unused_1" 2 "NotDeployed" 1 "Deployed" 0 "NoEvent" ;
VAL_ 74 VedsEvntType_D_Ltchd 7 "Fault" 6 "NotSupported" 5 "Unused" 4 "Rolllover" 3 "Rear" 2 "Side" 1 "Frontal" 0 "NoEvent" ;
VAL_ 74 VedsEvntRoll_D_Ltchd 7 "Fault" 6 "NotSupported" 5 "Unused_3" 4 "Unused_2" 3 "Unused_1" 2 "Yes" 1 "No" 0 "NoEvent" ;
VAL_ 74 VedsDrvSideBag_D_Ltchd 7 "Fault" 6 "NotSupported" 5 "Unused_3" 4 "Unused_2" 3 "Unused_1" 2 "NotDeployed" 1 "Deployed" 0 "NoEvent" ;
VAL_ 74 VedsDrvCrtnBag_D_Ltchd 7 "Fault" 6 "NotSupported" 5 "Unused_3" 4 "Unused_2" 3 "Unused_1" 2 "NotDeployed" 1 "Deployed" 0 "NoEvent" ;
VAL_ 74 VedsDrvBelt_D_Ltchd 7 "Fault" 6 "NotSupported" 5 "Unused_3" 4 "Unused_2" 3 "Unused_1" 2 "NotDeployed" 1 "Deployed" 0 "NoEvent" ;
VAL_ 74 VedsDrvBag_D_Ltchd 7 "Fault" 6 "NotSupported" 5 "Unused_3" 4 "Unused_2" 3 "Unused_1" 2 "NotDeployed" 1 "Deployed" 0 "NoEvent" ;
VAL_ 74 eCallNotification 3 "Not_Used" 2 "Active" 1 "Normal" 0 "Not_Supported" ;
VAL_ 625 ModemAuthrz_D_Stat2 3 "Null" 2 "RemoveKeys" 1 "Authorized" 0 "NotAuthorized" ;
VAL_ 625 PaakSerial_D2_Rq2 7 "NotUsed_3" 6 "NotUsed_1" 5 "NotUsed_1" 4 "PresentKeyDelivered" 3 "PresentReadyForKeyDelivery" 2 "PresentBlemProvAlertAck" 1 "PresentUnprovisioned" 0 "NotPresent" ;
VAL_ 435 ValetMode_D_Mem 1 "On" 0 "Off" ;
VAL_ 435 DrStatDrvErrCnt_B_Stat 1 "Yes" 0 "No" ;
VAL_ 435 TurnLghtRight_D_Rq 3 "Seq" 2 "On" 1 "Off" 0 "Null" ;
VAL_ 435 TurnLghtRightOn_B_Stat 1 "On" 0 "Off" ;
VAL_ 435 TurnLghtLeftOn_B_Stat 1 "On" 0 "Off" ;
VAL_ 435 FogLghtRearOn_B_Stat 1 "On" 0 "Off" ;
VAL_ 435 Backlit_LED_Status 15 "Unused3" 14 "Unused2" 13 "Unused1" 12 "Night_12" 11 "Night_11" 10 "Night_10" 9 "Night_9" 8 "Night_8" 7 "Night_7" 6 "Night_6" 5 "Night_5" 4 "Night_4" 3 "Night_3" 2 "Night_2" 1 "Night_1" 0 "Off" ;
VAL_ 435 TurnLghtLeft_D_Rq 3 "Seq" 2 "On" 1 "Off" 0 "Null" ;
VAL_ 435 FogLghtFrontOn_B_Stat 1 "On" 0 "Off" ;
VAL_ 435 IgnKeyType_D_Actl 15 "Invalid" 14 "Unknown" 3 "Key_Not_Prgrm_Read_Failure" 2 "Key_In_Ign_My_Key" 1 "Key_In_Ign_Standard_Key" 0 "Key_Read_In_Progress" ;
VAL_ 435 Parklamp_Status 3 "Invalid" 2 "Unknown" 1 "On" 0 "Off" ;
VAL_ 435 Litval 255 "Invalid" 254 "Unknown" 5 "Day" 4 "Twilight_4" 3 "Twilight_3" 2 "Twilight_2" 1 "Twilight_1" 0 "Night" ;
VAL_ 435 Key_In_Ignition_Stat 1 "In" 0 "Out" ;
VAL_ 435 Ignition_Status 0 "Unknown" 1 "Off" 15 "Invalid" 8 "Start" 4 "Run" 2 "Accessory" ;
VAL_ 435 Dimming_Lvl 255 "Invalid" 254 "Unknown" 18 "Day_6" 17 "Day_5" 16 "Day_4" 15 "Day_3" 14 "Day_2" 13 "Day_1" 12 "Night_12" 11 "Night_11" 10 "Night_10" 9 "Night_9" 8 "Night_8" 7 "Night_7" 6 "Night_6" 5 "Night_5" 4 "Night_4" 3 "Night_3" 2 "Night_2" 1 "Night_1" 0 "Off" ;
VAL_ 435 Day_Night_Status 3 "NotUsed" 2 "Night" 1 "Day" 0 "Null" ;
VAL_ 435 Remote_Start_Status 3 "Invalid" 2 "Unknown" 1 "Remote" 0 "Null" ;
VAL_ 435 DrStatTgate_B_Actl 1 "Ajar" 0 "Closed" ;
VAL_ 435 DrStatRr_B_Actl 1 "Ajar" 0 "Closed" ;
VAL_ 435 DrStatRl_B_Actl 1 "Ajar" 0 "Closed" ;
VAL_ 435 DrStatPsngr_B_Actl 1 "Ajar" 0 "Closed" ;
VAL_ 435 DrStatInnrTgate_B_Actl 1 "Ajar" 0 "Closed" ;
VAL_ 435 DrStatHood_B_Actl 1 "Ajar" 0 "Closed" ;
VAL_ 435 DrStatDrv_B_Actl 1 "Ajar" 0 "Closed" ;
VAL_ 435 PrkBrkActv_B_Actl 1 "Active" 0 "Inactive" ;
VAL_ 435 LifeCycMde_D_Actl 3 "Transport" 2 "NotUsed" 1 "Factory" 0 "Normal" ;
VAL_ 435 Delay_Accy 1 "On" 0 "Off" ;
VAL_ 435 CrashEvnt_D_Stat 3 "Invalid" 2 "Fuel_Cutoff_Event" 1 "Deploy_Event" 0 "No_Event" ;
VAL_ 435 FuelPmpInhbt_B_Stat 1 "Inhibit" 0 "No_Inibit" ;
VAL_ 435 BodySrvcRqd_B_Rq 1 "Yes" 0 "No" ;
